VERSION ""

NS_ :

BS_:

BU_:

VAL_TABLE_ pin_diagnostics_state 1 "pdsNOK" 0 "pdsOK" ;

BO_ 2180423678 REAR_IO_1_ECU_CAN1_1: 8 Vector__XXX

 SG_ rllrShttrLckActtRq : 0|2@1+ (1,0) [0|3] "" Vector__XXX

BO_ 2381750526 CABIN_IO_1_ECU_CAN1_1: 8 Vector__XXX

 SG_ hzrdSwtchStt : 0|2@1+ (1,0) [0|3] "" Vector__XXX

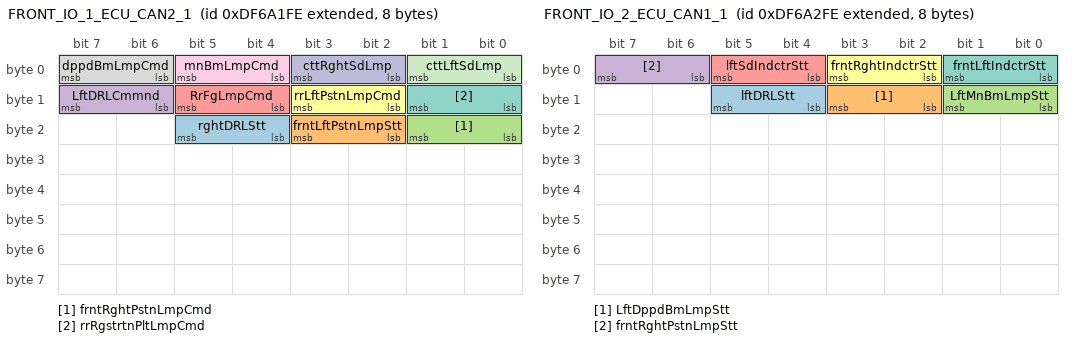
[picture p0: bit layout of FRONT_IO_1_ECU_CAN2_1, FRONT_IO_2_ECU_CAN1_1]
BO_ 2381750782 FRONT_IO_1_ECU_CAN2_1: 8 Vector__XXX

 SG_ rghtDRLStt : 20|2@1+ (1,0) [0|3] "" Vector__XXX

 SG_ frntLftPstnLmpStt : 18|2@1+ (1,0) [0|3] "" Vector__XXX

 SG_ frntRghtPstnLmpCmd : 16|2@1+ (1,0) [0|3] "" Vector__XXX

 SG_ LftDRLCmmnd : 14|2@1+ (1,0) [0|3] "" Vector__XXX

 SG_ RrFgLmpCmd : 12|2@1+ (1,0) [0|3] "" Vector__XXX

 SG_ rrLftPstnLmpCmd : 10|2@1+ (1,0) [0|3] "" Vector__XXX

 SG_ rrRgstrtnPltLmpCmd : 8|2@1+ (1,0) [0|3] "" Vector__XXX

 SG_ dppdBmLmpCmd : 6|2@1+ (1,0) [0|3] "" Vector__XXX

 SG_ mnBmLmpCmd : 4|2@1+ (1,0) [0|3] "" Vector__XXX

 SG_ cttRghtSdLmp : 2|2@1+ (1,0) [0|3] "" Vector__XXX

 SG_ cttLftSdLmp : 0|2@1+ (1,0) [0|3] "" Vector__XXX

BO_ 2381751038 FRONT_IO_2_ECU_CAN1_1: 8 Vector__XXX

 SG_ lftDRLStt : 12|2@1+ (1,0) [0|3] "" Vector__XXX

 SG_ LftDppdBmLmpStt : 10|2@1+ (1,0) [0|3] "" Vector__XXX

 SG_ LftMnBmLmpStt : 8|2@1+ (1,0) [0|3] "" Vector__XXX

 SG_ frntRghtPstnLmpStt : 6|2@1+ (1,0) [0|3] "" Vector__XXX

 SG_ lftSdIndctrStt : 4|2@1+ (1,0) [0|3] "" Vector__XXX

 SG_ frntRghtIndctrStt : 2|2@1+ (1,0) [0|3] "" Vector__XXX

 SG_ frntLftIndctrStt : 0|2@1+ (1,0) [0|3] "" Vector__XXX

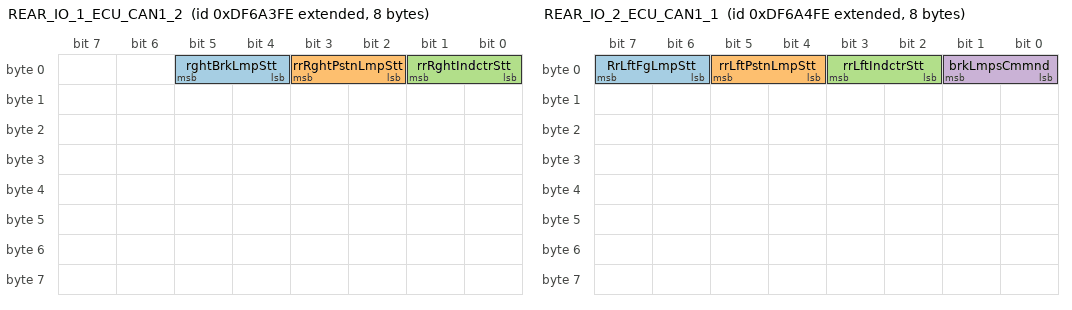
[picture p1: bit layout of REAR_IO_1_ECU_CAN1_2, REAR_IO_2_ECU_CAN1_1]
BO_ 2381751294 REAR_IO_1_ECU_CAN1_2: 8 Vector__XXX

 SG_ rghtBrkLmpStt : 4|2@1+ (1,0) [0|3] "" Vector__XXX

 SG_ rrRghtPstnLmpStt : 2|2@1+ (1,0) [0|3] "" Vector__XXX

 SG_ rrRghtIndctrStt : 0|2@1+ (1,0) [0|3] "" Vector__XXX

BO_ 2381751550 REAR_IO_2_ECU_CAN1_1: 8 Vector__XXX

 SG_ RrLftFgLmpStt : 6|2@1+ (1,0) [0|3] "" Vector__XXX

 SG_ rrLftPstnLmpStt : 4|2@1+ (1,0) [0|3] "" Vector__XXX

 SG_ rrLftIndctrStt : 2|2@1+ (1,0) [0|3] "" Vector__XXX

 SG_ brkLmpsCmmnd : 0|2@1+ (1,0) [0|3] "" Vector__XXX

BO_ 2583078398 CABIN_IO_1_ECU_CAN1_2: 8 Vector__XXX

 SG_ blkhdDrLtchStt : 0|2@1+ (1,0) [0|3] "-" Vector__XXX

BO_ 2583078654 CABIN_IO_2_ECU_CAN2_1: 8 Vector__XXX

 SG_ blkhdDrLtchRq : 4|2@1+ (1,0) [0|3] "-" Vector__XXX

 SG_ pssDrLtchRq : 2|2@1+ (1,0) [0|3] "-" Vector__XXX

 SG_ drvrDrLtchRq : 0|2@1+ (1,0) [0|3] "-" Vector__XXX

BO_ 2583078910 CABIN_IO_3_ECU_CAN1_1: 8 Vector__XXX

 SG_ pssPwrSldngDrSttDspl : 2|3@1+ (1,0) [0|0] "" Vector__XXX

 SG_ pssDrLtchStt : 0|2@1+ (1,0) [0|3] "-" Vector__XXX

BO_ 2583079166 FRONT_IO_1_ECU_CAN2_2: 8 Vector__XXX

 SG_ snsdSrvcHtchStt : 0|2@1+ (1,0) [0|0] "" Vector__XXX

BO_ 2583210494 FRONT_IO_2_ECU_CAN1_2: 8 Vector__XXX

 SG_ WshrCmmnd : 0|1@1+ (1,0) [0|1] "" Vector__XXX

BO_ 2583210750 FRONT_IO_1_ECU_CAN2_3: 8 Vector__XXX

 SG_ Glss2HtrStt : 0|2@1+ (1,0) [0|3] "" Vector__XXX

BO_ 2583211006 FRONT_IO_2_ECU_CAN1_3: 8 Vector__XXX

 SG_ Glss3HtrStt : 0|2@1+ (1,0) [0|3] "" Vector__XXX

BO_ 2365443838 ELREQ_DCU_Stalks: 8 Vector__XXX

 SG_ MainBeamStalksReq : 6|2@1+ (1,0) [0|3] "" Vector__XXX

 SG_ TurnIndReq : 2|4@1+ (1,0) [0|3] "" Vector__XXX

 SG_ SwitchReq : 0|2@1+ (1,0) [0|3] "" Vector__XXX

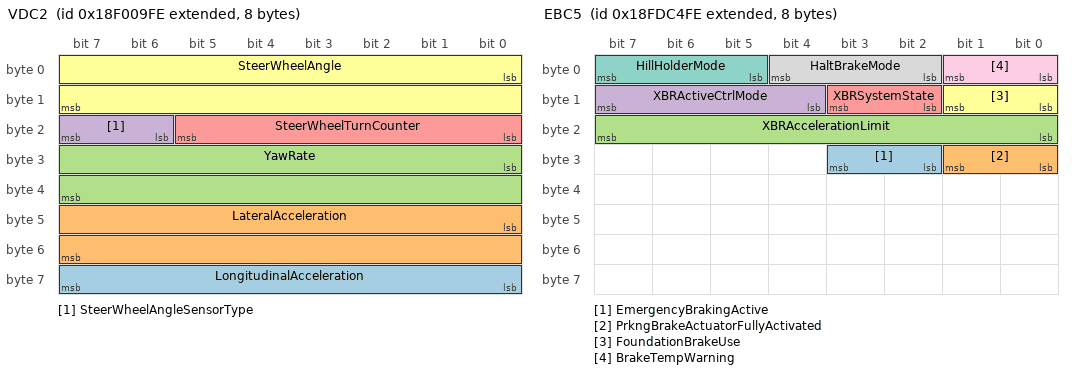
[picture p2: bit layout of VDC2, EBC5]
BO_ 2565868030 VDC2: 8 Vector__XXX

 SG_ LongitudinalAcceleration : 56|8@1+ (0.1,-12.5) [-12.5|12.5] "m/s" Vector__XXX

 SG_ LateralAcceleration : 40|16@1+ (0.00048828125,-15.687) [-15.687|15.687] "m/s" Vector__XXX

 SG_ YawRate : 24|16@1+ (0.0001220703125,-3.92) [-3.92|3.92] "rad/s" Vector__XXX

 SG_ SteerWheelAngleSensorType : 22|2@1+ (1,0) [0|3] "" Vector__XXX

 SG_ SteerWheelTurnCounter : 16|6@1+ (1,-32) [-10|10] "turns" Vector__XXX

 SG_ SteerWheelAngle : 0|16@1+ (0.0009765625,-31.374) [-31.374|31.374] "rad" Vector__XXX

BO_ 2566767870 EBC5: 8 Vector__XXX

 SG_ EmergencyBrakingActive : 26|2@1+ (1,0) [0|3] "" Vector__XXX

 SG_ PrkngBrakeActuatorFullyActivated : 24|2@1+ (1,0) [0|3] "" Vector__XXX

 SG_ XBRAccelerationLimit : 16|8@1+ (0.1,-12.5) [-10|10] "m/s" Vector__XXX

 SG_ XBRActiveCtrlMode : 12|4@1+ (1,0) [0|15] "" Vector__XXX

 SG_ XBRSystemState : 10|2@1+ (1,0) [0|3] "" Vector__XXX

 SG_ FoundationBrakeUse : 8|2@1+ (1,0) [0|3] "" Vector__XXX

 SG_ HillHolderMode : 5|3@1+ (1,0) [0|7] "" Vector__XXX

 SG_ HaltBrakeMode : 2|3@1+ (1,0) [0|7] "" Vector__XXX

 SG_ BrakeTempWarning : 0|2@1+ (1,0) [0|3] "" Vector__XXX

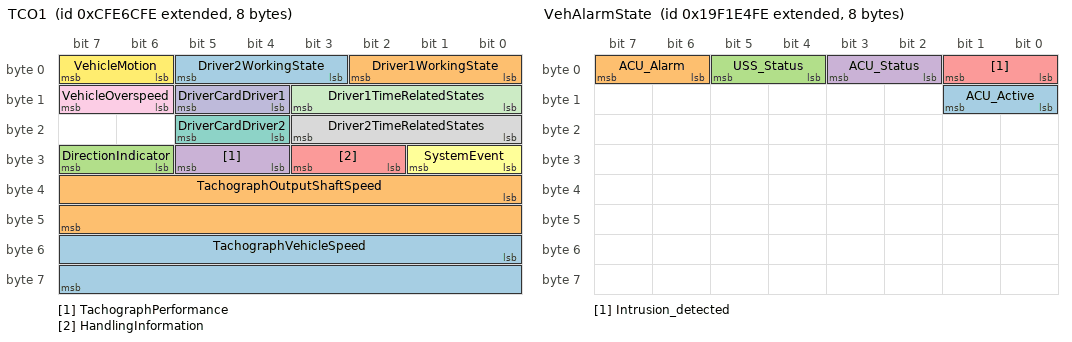
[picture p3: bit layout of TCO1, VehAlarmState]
BO_ 2365484286 TCO1: 8 Vector__XXX

 SG_ TachographVehicleSpeed : 48|16@1+ (0.00390625,0) [0|250.996] "km/h" Vector__XXX

 SG_ TachographOutputShaftSpeed : 32|16@1+ (0.125,0) [0|8031.875] "rpm" Vector__XXX

 SG_ DirectionIndicator : 30|2@1+ (1,0) [0|3] "" Vector__XXX

 SG_ TachographPerformance : 28|2@1+ (1,0) [0|3] "" Vector__XXX

 SG_ HandlingInformation : 26|2@1+ (1,0) [0|3] "" Vector__XXX

 SG_ SystemEvent : 24|2@1+ (1,0) [0|3] "" Vector__XXX

 SG_ DriverCardDriver2 : 20|2@1+ (1,0) [0|3] "" Vector__XXX

 SG_ Driver2TimeRelatedStates : 16|4@1+ (1,0) [0|15] "" Vector__XXX

 SG_ VehicleOverspeed : 14|2@1+ (1,0) [0|3] "" Vector__XXX

 SG_ DriverCardDriver1 : 12|2@1+ (1,0) [0|3] "" Vector__XXX

 SG_ Driver1TimeRelatedStates : 8|4@1+ (1,0) [0|15] "" Vector__XXX

 SG_ VehicleMotion : 6|2@1+ (1,0) [0|3] "" Vector__XXX

 SG_ Driver2WorkingState : 3|3@1+ (1,0) [0|7] "" Vector__XXX

 SG_ Driver1WorkingState : 0|3@1+ (1,0) [0|7] "" Vector__XXX

BO_ 2582766846 VehAlarmState: 8 Vector__XXX

 SG_ ACU_Active : 8|2@1+ (1,0) [0|3] "" Vector__XXX

 SG_ ACU_Alarm : 6|2@1+ (1,0) [0|3] "" Vector__XXX

 SG_ USS_Status : 4|2@1+ (1,0) [0|3] "" Vector__XXX

 SG_ ACU_Status : 2|2@1+ (1,0) [0|3] "" Vector__XXX

 SG_ Intrusion_detected : 0|2@1+ (1,0) [0|3] "-" Vector__XXX

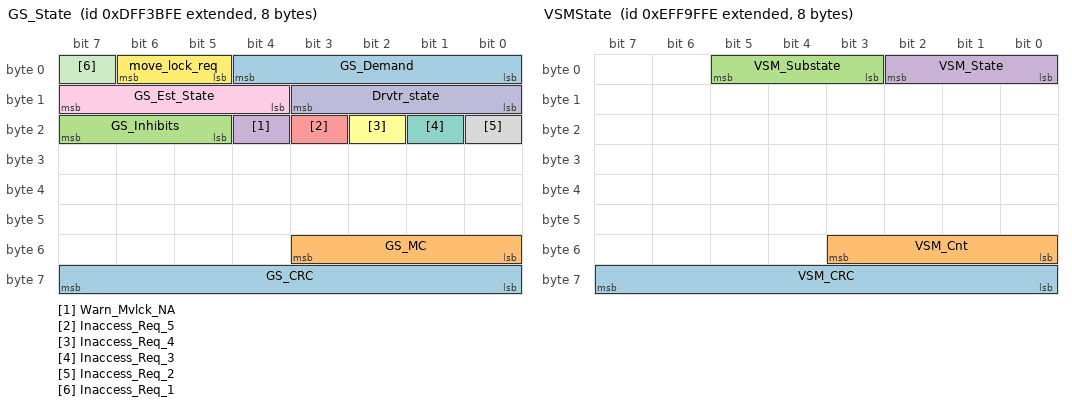
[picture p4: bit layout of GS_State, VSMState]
BO_ 2382314494 GS_State: 8 Vector__XXX

 SG_ GS_CRC : 56|8@1+ (1,0) [0|255] "" Vector__XXX

 SG_ GS_MC : 48|4@1+ (1,0) [0|15] "" Vector__XXX

 SG_ GS_Inhibits : 21|3@1+ (1,0) [0|7] "" Vector__XXX

 SG_ Warn_Mvlck_NA : 20|1@1+ (1,0) [0|1] "" Vector__XXX

 SG_ Inaccess_Req_5 : 19|1@1+ (1,0) [0|1] "" Vector__XXX

 SG_ Inaccess_Req_4 : 18|1@1+ (1,0) [0|1] "" Vector__XXX

 SG_ Inaccess_Req_3 : 17|1@1+ (1,0) [0|1] "" Vector__XXX

 SG_ Inaccess_Req_2 : 16|1@1+ (1,0) [0|1] "" Vector__XXX

 SG_ GS_Est_State : 12|4@1+ (1,0) [0|15] "" Vector__XXX

 SG_ Drvtr_state : 8|4@1+ (1,0) [0|15] "" Vector__XXX

 SG_ Inaccess_Req_1 : 7|1@1+ (1,0) [0|1] "" Vector__XXX

 SG_ move_lock_req : 5|2@1+ (1,0) [0|3] "" Vector__XXX

 SG_ GS_Demand : 0|5@1+ (1,0) [0|31] "" Vector__XXX

BO_ 2365473278 LCMD: 8 Vector__XXX

 SG_ ImplementRearWorkLightCmd : 62|2@1+ (1,0) [0|3] "" Vector__XXX

 SG_ ImplLeftFacingWorkLightCmd : 60|2@1+ (1,0) [0|3] "" Vector__XXX

 SG_ ImplRightFwdWorkLightCmd : 58|2@1+ (1,0) [0|3] "" Vector__XXX

 SG_ LightingDataRqCmd : 56|2@1+ (1,0) [0|3] "" Vector__XXX

 SG_ ImplLeftForwardWorkLightCmd : 54|2@1+ (1,0) [0|3] "" Vector__XXX

 SG_ ImplRightFacingWorkLightCmd : 52|2@1+ (1,0) [0|3] "" Vector__XXX

 SG_ ImplOEMOption1LightCmd : 50|2@1+ (1,0) [0|3] "" Vector__XXX

 SG_ ImplOEMOption2LightCmd : 48|2@1+ (1,0) [0|3] "" Vector__XXX

 SG_ TrctrFrntHghMdWkLightsCmd : 46|2@1+ (1,0) [0|3] "" Vector__XXX

 SG_ TrctrFrntLowMdWkLightsCmd : 44|2@1+ (1,0) [0|3] "" Vector__XXX

 SG_ TrctrSdeHighMdWkLightsCmd : 42|2@1+ (1,0) [0|3] "" Vector__XXX

 SG_ TrctrSideLowMdWkLightsCmd : 40|2@1+ (1,0) [0|3] "" Vector__XXX

 SG_ TrctrRarHighMdWkLightsCmd : 38|2@1+ (1,0) [0|3] "" Vector__XXX

 SG_ TrctrRearLowMdWkLightsCmd : 36|2@1+ (1,0) [0|3] "" Vector__XXX

 SG_ TrctrUndrsdeMdWkLightsCmd : 34|2@1+ (1,0) [0|3] "" Vector__XXX

 SG_ RearFogLightsCmd : 32|2@1+ (1,0) [0|3] "" Vector__XXX

 SG_ TractorMarkerLightCmd : 30|2@1+ (1,0) [0|3] "" Vector__XXX

 SG_ ImplementMarkerLightCmd : 28|2@1+ (1,0) [0|3] "" Vector__XXX

 SG_ TractorClearanceLightCmd : 26|2@1+ (1,0) [0|3] "" Vector__XXX

 SG_ ImplementClearanceLightCmd : 24|2@1+ (1,0) [0|3] "" Vector__XXX

 SG_ LeftStopLightCmd : 22|2@1+ (1,0) [0|3] "" Vector__XXX

 SG_ RightStopLightCmd : 20|2@1+ (1,0) [0|3] "" Vector__XXX

 SG_ CenterStopLightCmd : 18|2@1+ (1,0) [0|3] "" Vector__XXX

 SG_ BackUpLightAndAlarmHornCmd : 16|2@1+ (1,0) [0|3] "" Vector__XXX

 SG_ LeftTurnSignalLightsCmd : 14|2@1+ (1,0) [0|3] "" Vector__XXX

 SG_ RightTurnSignalLightsCmd : 12|2@1+ (1,0) [0|3] "" Vector__XXX

 SG_ RotatingBeaconLightCmd : 10|2@1+ (1,0) [0|3] "" Vector__XXX

 SG_ TractorFrontFogLightsCmd : 8|2@1+ (1,0) [0|3] "" Vector__XXX

 SG_ HighBeamHeadLightCmd : 6|2@1+ (1,0) [0|3] "" Vector__XXX

 SG_ LowBeamHeadLightCmd : 4|2@1+ (1,0) [0|3] "" Vector__XXX

 SG_ AltBeamHeadLightCmd : 2|2@1+ (1,0) [0|3] "" Vector__XXX

 SG_ RunningLightCmd : 0|2@1+ (1,0) [0|3] "" Vector__XXX

BO_ 2399117310 VSMState: 8 Vector__XXX

 SG_ VSM_CRC : 56|8@1+ (1,0) [0|255] "" Vector__XXX

 SG_ VSM_Cnt : 48|4@1+ (1,0) [0|15] "" Vector__XXX

 SG_ VSM_Substate : 3|3@1+ (1,0) [0|7] "" Vector__XXX

 SG_ VSM_State : 0|3@1+ (1,0) [0|7] "" Vector__XXX

BO_ 2566799614 LD: 8 Vector__XXX

 SG_ ImplementRearWorkLight : 62|2@1+ (1,0) [0|3] "" Vector__XXX

 SG_ ImplLeftFacingWorkLight : 60|2@1+ (1,0) [0|3] "" Vector__XXX

 SG_ ImplRightForwardWorkLight : 58|2@1+ (1,0) [0|3] "" Vector__XXX

 SG_ ImplLeftForwardWorkLight : 54|2@1+ (1,0) [0|3] "" Vector__XXX

 SG_ ImplRightFacingWorkLight : 52|2@1+ (1,0) [0|3] "" Vector__XXX

 SG_ ImplementOEMOption1Light : 50|2@1+ (1,0) [0|3] "" Vector__XXX

 SG_ ImplementOEMOption2Light : 48|2@1+ (1,0) [0|3] "" Vector__XXX

 SG_ TrctorFrontHighMdWkLights : 46|2@1+ (1,0) [0|3] "" Vector__XXX

 SG_ TractorFrontLowMdWkLights : 44|2@1+ (1,0) [0|3] "" Vector__XXX

 SG_ TractorSideHighMdWkLights : 42|2@1+ (1,0) [0|3] "" Vector__XXX

 SG_ TractorSideLowMdWkLights : 40|2@1+ (1,0) [0|3] "" Vector__XXX

 SG_ TractorRearHighMdWkLights : 38|2@1+ (1,0) [0|3] "" Vector__XXX

 SG_ TractorRearLowMdWkLights : 36|2@1+ (1,0) [0|3] "" Vector__XXX

 SG_ TrctorUndersideMdWkLights : 34|2@1+ (1,0) [0|3] "" Vector__XXX

 SG_ RearFogLights : 32|2@1+ (1,0) [0|3] "" Vector__XXX

 SG_ TractorMarkerLight : 30|2@1+ (1,0) [0|3] "" Vector__XXX

 SG_ ImplementMarkerLight : 28|2@1+ (1,0) [0|3] "" Vector__XXX

 SG_ TractorClearanceLight : 26|2@1+ (1,0) [0|3] "" Vector__XXX

 SG_ ImplementClearanceLight : 24|2@1+ (1,0) [0|3] "" Vector__XXX

 SG_ LeftStopLight : 22|2@1+ (1,0) [0|3] "" Vector__XXX

 SG_ RightStopLight : 20|2@1+ (1,0) [0|3] "" Vector__XXX

 SG_ CenterStopLight : 18|2@1+ (1,0) [0|3] "" Vector__XXX

 SG_ BackUpLightAndAlarmHorn : 16|2@1+ (1,0) [0|3] "" Vector__XXX

 SG_ LeftTurnSignalLights : 14|2@1+ (1,0) [0|3] "" Vector__XXX

 SG_ RightTurnSignalLights : 12|2@1+ (1,0) [0|3] "" Vector__XXX

 SG_ RotatingBeaconLight : 10|2@1+ (1,0) [0|3] "" Vector__XXX

 SG_ TractorFrontFogLights : 8|2@1+ (1,0) [0|3] "" Vector__XXX

 SG_ HighBeamHeadLight : 6|2@1+ (1,0) [0|3] "" Vector__XXX

 SG_ LowBeamHeadLight : 4|2@1+ (1,0) [0|3] "" Vector__XXX

 SG_ AltBeamHeadLight : 2|2@1+ (1,0) [0|3] "" Vector__XXX

 SG_ RunningLight : 0|2@1+ (1,0) [0|3] "" Vector__XXX

BO_ 2381851134 HornSwitchState: 8 Vector__XXX

 SG_ HornSwitchReq : 0|2@1+ (1,0) [0|3] "" Vector__XXX

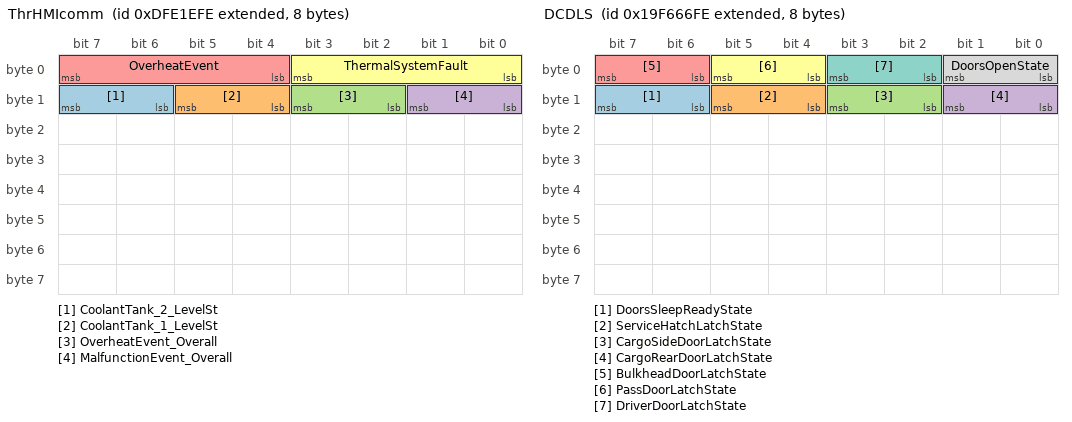
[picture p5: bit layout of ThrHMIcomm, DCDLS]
BO_ 2382241534 ThrHMIcomm: 8 Vector__XXX

 SG_ CoolantTank_2_LevelSt : 14|2@1+ (1,0) [0|0] "" Vector__XXX

 SG_ CoolantTank_1_LevelSt : 12|2@1+ (1,0) [0|0] "" Vector__XXX

 SG_ OverheatEvent_Overall : 10|2@1+ (1,0) [0|0] "" Vector__XXX

 SG_ MalfunctionEvent_Overall : 8|2@1+ (1,0) [0|0] "" Vector__XXX

 SG_ OverheatEvent : 4|4@1+ (1,0) [0|0] "" Vector__XXX

 SG_ ThermalSystemFault : 0|4@1+ (1,0) [0|0] "" Vector__XXX

BO_ 2314625790 RideHeightSensorRaw: 8 Vector__XXX

 SG_ HeightMeasured : 8|8@1+ (1,0) [0|255] "mm" Vector__XXX

 SG_ RotationAngle : 0|8@1+ (1,90) [90|270] "deg" Vector__XXX

BO_ 2583062270 DCDLS: 8 Vector__XXX

 SG_ DoorsSleepReadyState : 14|2@1+ (1,0) [0|3] "-" Vector__XXX

 SG_ ServiceHatchLatchState : 12|2@1+ (1,0) [0|0] "" Vector__XXX

 SG_ CargoSideDoorLatchState : 10|2@1+ (1,0) [0|3] "-" Vector__XXX

 SG_ CargoRearDoorLatchState : 8|2@1+ (1,0) [0|3] "-" Vector__XXX

 SG_ BulkheadDoorLatchState : 6|2@1+ (1,0) [0|3] "-" Vector__XXX

 SG_ PassDoorLatchState : 4|2@1+ (1,0) [0|3] "-" Vector__XXX

 SG_ DriverDoorLatchState : 2|2@1+ (1,0) [0|3] "-" Vector__XXX

 SG_ DoorsOpenState : 0|2@1+ (1,0) [0|3] "-" Vector__XXX

BO_ 2566882814 VehicleKeyState: 8 Vector__XXX

 SG_ KeyRange : 3|3@1+ (1,0) [0|7] "-" Vector__XXX

 SG_ KeyCommand : 0|3@1+ (1,0) [0|7] "-" Vector__XXX

BO_ 2583062526 CENTLOCKIN_HMI: 8 Vector__XXX

 SG_ CentralLockRequest : 0|3@1+ (1,0) [0|7] "-" Vector__XXX

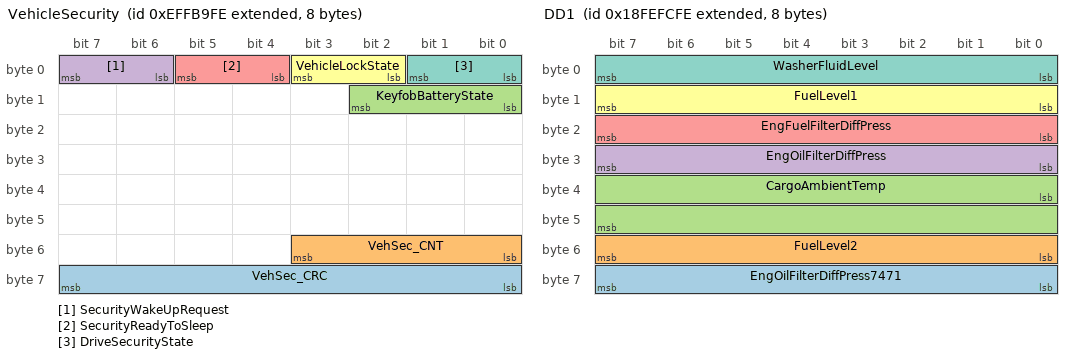
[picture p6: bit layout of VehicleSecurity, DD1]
BO_ 2399123966 VehicleSecurity: 8 Vector__XXX

 SG_ VehSec_CRC : 56|8@1+ (1,0) [0|255] "" Vector__XXX

 SG_ VehSec_CNT : 48|4@1+ (1,0) [0|15] "" Vector__XXX

 SG_ KeyfobBatteryState : 8|3@1+ (1,0) [0|7] "" Vector__XXX

 SG_ SecurityWakeUpRequest : 6|2@1+ (1,0) [0|3] "" Vector__XXX

 SG_ SecurityReadyToSleep : 4|2@1+ (1,0) [0|3] "" Vector__XXX

 SG_ VehicleLockState : 2|2@1+ (1,0) [0|3] "" Vector__XXX

 SG_ DriveSecurityState : 0|2@1+ (1,0) [0|3] "" Vector__XXX

BO_ 2583065854 CENTLOCKIN_KeyFob: 8 Vector__XXX

 SG_ CentralLockRequest : 0|3@1+ (1,0) [0|7] "-" Vector__XXX

BO_ 2163223550 CN: 8 Vector__XXX

 SG_ CrashChecksum : 60|4@1+ (1,0) [0|15] "" Vector__XXX

 SG_ CrashCounter : 56|4@1+ (1,0) [0|15] "" Vector__XXX

 SG_ CrashType : 0|5@1+ (1,0) [0|31] "" Vector__XXX

BO_ 2566847742 DD1: 8 Vector__XXX

 SG_ EngOilFilterDiffPress7471 : 56|8@1+ (5,0) [0|1250] "kPa" Vector__XXX

 SG_ FuelLevel2 : 48|8@1+ (0.4,0) [0|100] "%" Vector__XXX

 SG_ CargoAmbientTemp : 32|16@1+ (0.03125,-273) [-273|1734.96875] "C" Vector__XXX

 SG_ EngOilFilterDiffPress : 24|8@1+ (0.5,0) [0|125] "kPa" Vector__XXX

 SG_ EngFuelFilterDiffPress : 16|8@1+ (2,0) [0|500] "kPa" Vector__XXX

 SG_ FuelLevel1 : 8|8@1+ (0.4,0) [0|100] "%" Vector__XXX

 SG_ WasherFluidLevel : 0|8@1+ (0.4,0) [0|100] "%" Vector__XXX

BO_ 2583173886 WPRWSH_UserRequest: 8 Vector__XXX

 SG_ WipeRequest : 2|3@1+ (1,0) [0|7] "" Vector__XXX

 SG_ WashRequest : 0|2@1+ (1,0) [0|3] "" Vector__XXX

BO_ 2516075518 RideHeight_Info: 8 Vector__XXX

 SG_ RideHeight_Value : 0|3@1+ (1,0) [0|0] "" Vector__XXX

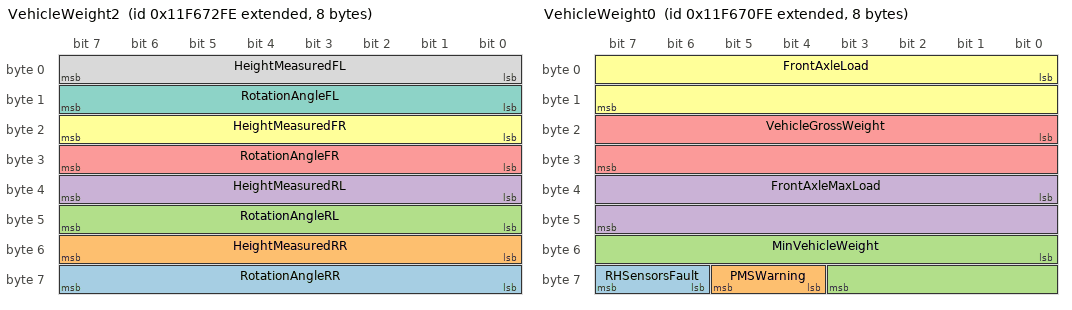
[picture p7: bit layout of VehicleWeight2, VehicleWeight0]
BO_ 2448847614 VehicleWeight2: 8 Vector__XXX

 SG_ RotationAngleRR : 56|8@1+ (1,90) [90|270] "deg" Vector__XXX

 SG_ HeightMeasuredRR : 48|8@1+ (1,0) [0|255] "mm" Vector__XXX

 SG_ RotationAngleRL : 40|8@1+ (1,90) [90|270] "deg" Vector__XXX

 SG_ HeightMeasuredRL : 32|8@1+ (1,0) [0|255] "mm" Vector__XXX

 SG_ RotationAngleFR : 24|8@1+ (1,90) [90|270] "deg" Vector__XXX

 SG_ HeightMeasuredFR : 16|8@1+ (1,0) [0|255] "mm" Vector__XXX

 SG_ RotationAngleFL : 8|8@1+ (1,90) [90|270] "deg" Vector__XXX

 SG_ HeightMeasuredFL : 0|8@1+ (1,0) [0|255] "mm" Vector__XXX

BO_ 2448847102 VehicleWeight0: 8 Vector__XXX

 SG_ RHSensorsFault : 62|2@1+ (1,0) [0|3] "" Vector__XXX

 SG_ PMSWarning : 60|2@1+ (1,0) [0|3] "" Vector__XXX

 SG_ MinVehicleWeight : 48|12@1+ (10,0) [0|40000] "kg" Vector__XXX

 SG_ FrontAxleMaxLoad : 32|16@1+ (1,0) [0|65535] "kg" Vector__XXX

 SG_ VehicleGrossWeight : 16|16@1+ (1,0) [0|65535] "kg" Vector__XXX

 SG_ FrontAxleLoad : 0|16@1+ (1,0) [0|65535] "kg" Vector__XXX

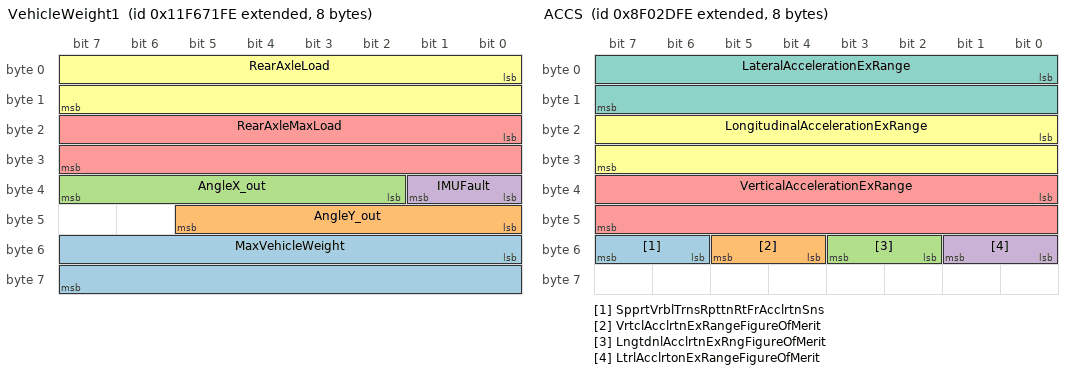
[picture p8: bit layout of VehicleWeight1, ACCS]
BO_ 2448847358 VehicleWeight1: 8 Vector__XXX

 SG_ MaxVehicleWeight : 48|16@1+ (1,0) [0|65535] "kg" Vector__XXX

 SG_ AngleY_out : 40|6@1+ (1.5,-45) [-45|45] "deg" Vector__XXX

 SG_ AngleX_out : 34|6@1+ (1.5,-45) [-45|45] "deg" Vector__XXX

 SG_ IMUFault : 32|2@1+ (1,0) [0|3] "" Vector__XXX

 SG_ RearAxleMaxLoad : 16|16@1+ (1,0) [0|65535] "kg" Vector__XXX

 SG_ RearAxleLoad : 0|16@1+ (1,0) [0|65535] "kg" Vector__XXX

BO_ 2297441790 ACCS: 8 Vector__XXX

 SG_ SpprtVrblTrnsRpttnRtFrAcclrtnSns : 54|2@1+ (1,0) [0|3] "" Vector__XXX

 SG_ VrtclAcclrtnExRangeFigureOfMerit : 52|2@1+ (1,0) [0|3] "" Vector__XXX

 SG_ LngtdnlAcclrtnExRngFigureOfMerit : 50|2@1+ (1,0) [0|3] "" Vector__XXX

 SG_ LtrlAcclrtonExRangeFigureOfMerit : 48|2@1+ (1,0) [0|3] "" Vector__XXX

 SG_ VerticalAccelerationExRange : 32|16@1+ (0.01,-320) [-320|322.55] "m/s" Vector__XXX

 SG_ LongitudinalAccelerationExRange : 16|16@1+ (0.01,-320) [-320|322.55] "m/s" Vector__XXX

 SG_ LateralAccelerationExRange : 0|16@1+ (0.01,-320) [-320|322.55] "m/s" Vector__XXX

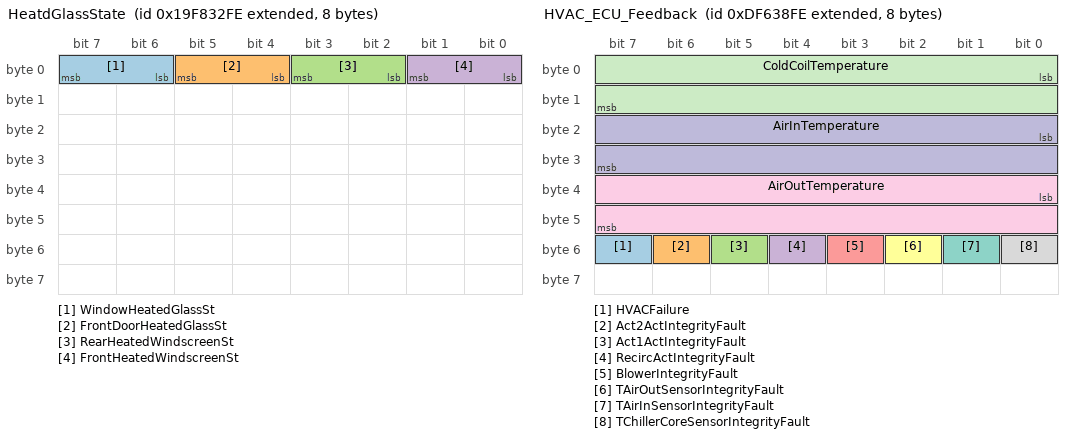
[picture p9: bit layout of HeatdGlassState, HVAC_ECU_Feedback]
BO_ 2583180030 HeatdGlassState: 8 Vector__XXX

 SG_ WindowHeatedGlassSt : 6|2@1+ (1,0) [0|3] "" Vector__XXX

 SG_ FrontDoorHeatedGlassSt : 4|2@1+ (1,0) [0|3] "" Vector__XXX

 SG_ RearHeatedWindscreenSt : 2|2@1+ (1,0) [0|3] "" Vector__XXX

 SG_ FrontHeatedWindscreenSt : 0|2@1+ (1,0) [0|3] "" Vector__XXX

BO_ 2499547902 CDC: 8 Vector__XXX

 SG_ MirrorRight2HeatCmd : 54|2@1+ (1,0) [0|3] "" Vector__XXX

 SG_ MirrorLeft2HeatCmd : 52|2@1+ (1,0) [0|3] "" Vector__XXX

 SG_ MirrorRight1HeatCmd : 50|2@1+ (1,0) [0|3] "" Vector__XXX

 SG_ MirrorLeft1HeatCmd : 48|2@1+ (1,0) [0|3] "" Vector__XXX

 SG_ MirrorRight2VerticalCmd : 46|2@1+ (1,0) [0|3] "" Vector__XXX

 SG_ MirrorRight2HorizontalCmd : 44|2@1+ (1,0) [0|3] "" Vector__XXX

 SG_ MirrorLeft2VerticalCmd : 42|2@1+ (1,0) [0|3] "" Vector__XXX

 SG_ MirrorLeft2HorizontalCmd : 40|2@1+ (1,0) [0|3] "" Vector__XXX

 SG_ MirrorRight1VerticalCmd : 38|2@1+ (1,0) [0|3] "" Vector__XXX

 SG_ MirrorRight1HorizontalCmd : 36|2@1+ (1,0) [0|3] "" Vector__XXX

 SG_ MirrorLeft1VerticalCmd : 34|2@1+ (1,0) [0|3] "" Vector__XXX

 SG_ MirrorLeft1HorizontalCmd : 32|2@1+ (1,0) [0|3] "" Vector__XXX

 SG_ RightRearWindowPosCmd : 27|3@1+ (1,0) [0|7] "" Vector__XXX

 SG_ LeftRearWindowPosCmd : 24|3@1+ (1,0) [0|7] "" Vector__XXX

 SG_ RightFrontWindowPosCmd : 19|3@1+ (1,0) [0|7] "" Vector__XXX

 SG_ LeftFrontWindowPosCmd : 16|3@1+ (1,0) [0|7] "" Vector__XXX

 SG_ RemoteCabDoorLockReq : 8|3@1+ (1,0) [0|7] "" Vector__XXX

 SG_ DoorsLockActCmd : 0|3@1+ (1,0) [0|7] "" Vector__XXX

BO_ 2583173374 WPRWSH_WiperFaults: 8 Vector__XXX

 SG_ WiperSilenceFault : 2|1@1+ (1,0) [0|1] "" Vector__XXX

 SG_ WiperHomePosFault : 1|1@1+ (1,0) [0|1] "" Vector__XXX

 SG_ WiperControlFault : 0|1@1+ (1,0) [0|1] "" Vector__XXX

BO_ 2583177470 WPRWSH_RainData: 8 Vector__XXX

 SG_ RainIntensity : 0|3@1+ (1,0) [0|7] "" Vector__XXX

BO_ 2583175166 WPRWSH_WiperArbReq: 8 Vector__XXX

 SG_ WipeArbRequest : 0|3@1+ (1,0) [0|5] "" Vector__XXX

BO_ 2364552702 ImmoState: 8 Vector__XXX

 SG_ ImmoState : 0|2@1+ (1,0) [0|3] "" Vector__XXX

BO_ 2565865982 EBC1: 8 Vector__XXX

 SG_ TrctrMntdTrailerABSWarningSignal : 62|2@1+ (1,0) [0|3] "" Vector__XXX

 SG_ TrailerABSStatus : 60|2@1+ (1,0) [0|3] "" Vector__XXX

 SG_ HaltBrakeSwitch : 58|2@1+ (1,0) [0|3] "" Vector__XXX

 SG_ SrcAddrssOfCntrllngDvcFrBrkeCtrl : 48|8@1+ (1,0) [0|253] "" Vector__XXX

 SG_ ATC_ASRInformationSignal : 46|2@1+ (1,0) [0|3] "" Vector__XXX

 SG_ ABS_EBSAmberWarningSignal : 44|2@1+ (1,0) [0|3] "" Vector__XXX

 SG_ EBSRedWarningSignal : 42|2@1+ (1,0) [0|3] "" Vector__XXX

 SG_ ABSFullyOperational : 40|2@1+ (1,0) [0|3] "" Vector__XXX

 SG_ EngRetarderSelection : 32|8@1+ (0.4,0) [0|100] "%" Vector__XXX

 SG_ RemoteAccelEnableSwitch : 30|2@1+ (1,0) [0|3] "" Vector__XXX

 SG_ EngAuxShutdownSwitch : 28|2@1+ (1,0) [0|3] "" Vector__XXX

 SG_ EngDerateSwitch : 26|2@1+ (1,0) [0|3] "" Vector__XXX

 SG_ AccelInterlockSwitch : 24|2@1+ (1,0) [0|3] "" Vector__XXX

 SG_ TractionCtrlOverrideSwitch : 22|2@1+ (1,0) [0|3] "" Vector__XXX

 SG_ ASRHillHolderSwitch : 20|2@1+ (1,0) [0|3] "" Vector__XXX

 SG_ ASROffroadSwitch : 18|2@1+ (1,0) [0|3] "" Vector__XXX

 SG_ ABSOffroadSwitch : 16|2@1+ (1,0) [0|3] "" Vector__XXX

 SG_ BrakePedalPos : 8|8@1+ (0.4,0) [0|100] "%" Vector__XXX

 SG_ EBSBrakeSwitch : 6|2@1+ (1,0) [0|3] "" Vector__XXX

 SG_ AntiLockBrakingActive : 4|2@1+ (1,0) [0|3] "" Vector__XXX

 SG_ ASRBrakeCtrlActive : 2|2@1+ (1,0) [0|3] "" Vector__XXX

 SG_ ASREngCtrlActive : 0|2@1+ (1,0) [0|3] "" Vector__XXX

BO_ 2583176190 SeatSt: 8 Vector__XXX

 SG_ SigSeatSt : 6|2@1+ (1,0) [0|3] "" Vector__XXX

BO_ 2381731326 TP_TouchEvent: 8 Vector__XXX

 SG_ TouchFailState : 3|3@1+ (1,0) [0|7] "" Vector__XXX

 SG_ TouchEvent : 0|3@1+ (1,0) [0|7] "" Vector__XXX

BO_ 2381723902 HVAC_ECU_Feedback: 8 Vector__XXX

 SG_ HVACFailure : 55|1@1+ (1,0) [0|1] "" Vector__XXX

 SG_ Act2ActIntegrityFault : 54|1@1+ (1,0) [0|1] "" Vector__XXX

 SG_ Act1ActIntegrityFault : 53|1@1+ (1,0) [0|1] "" Vector__XXX

 SG_ RecircActIntegrityFault : 52|1@1+ (1,0) [0|1] "" Vector__XXX

 SG_ BlowerIntegrityFault : 51|1@1+ (1,0) [0|1] "" Vector__XXX

 SG_ TAirOutSensorIntegrityFault : 50|1@1+ (1,0) [0|1] "" Vector__XXX

 SG_ TAirInSensorIntegrityFault : 49|1@1+ (1,0) [0|1] "" Vector__XXX

 SG_ TChillerCoreSensorIntegrityFault : 48|1@1+ (1,0) [0|1] "" Vector__XXX

 SG_ AirOutTemperature : 32|16@1+ (0.03125,-273) [-273|1774.96875] "C" Vector__XXX

 SG_ AirInTemperature : 16|16@1+ (0.03125,-273) [-273|1774.96875] "C" Vector__XXX

 SG_ ColdCoilTemperature : 0|16@1+ (0.03125,-273) [-273|1774.96875] "C" Vector__XXX

BO_ 2566848570 AirHandler_Temperatures: 8 Device

 SG_ BlowerSpeed : 48|8@1+ (0.4,0) [0|102] "%"  Host

 SG_ AirOutTemperature : 32|16@1+ (0.03125,-273) [-273|1774.97] "C"  Host

 SG_ AirInTemperature : 16|16@1+ (0.03125,-273) [-273|1774.97] "C"  Host

 SG_ ColdCoilTemperature : 0|16@1+ (0.03125,-273) [-273|1774.97] "C"  Host

BO_ 2566848826 AirHandler_Status1: 8 Device

 SG_ Defrost_Act_Position : 56|8@1+ (10,0) [0|2550] "steps"  Host

 SG_ Defrost_Act_Stall : 55|1@1+ (1,0) [0|1] ""  Host

 SG_ Defrost_Act_Voltage : 53|2@1+ (1,0) [0|3] ""  Host

 SG_ Defrost_Act_Temp : 52|1@1+ (1,0) [0|1] ""  Host

 SG_ Defrost_Act_Response : 51|1@1+ (1,0) [0|1] ""  Host

 SG_ Addressing_Status : 48|3@1+ (1,0) [0|7] ""  Host

 SG_ Face_Act_Position : 40|8@1+ (10,0) [0|2550] "steps"  Host

 SG_ Face_Act_Stall : 39|1@1+ (1,0) [0|1] ""  Host

 SG_ Face_Act_Voltage : 37|2@1+ (1,0) [0|3] ""  Host

 SG_ Face_Act_Temp : 36|1@1+ (1,0) [0|1] ""  Host

 SG_ Face_Act_Response : 35|1@1+ (1,0) [0|1] ""  Host

 SG_ Calibration_Status : 32|3@1+ (1,0) [0|7] ""  Host

 SG_ Foot_Act_Position : 24|8@1+ (10,0) [0|2550] "steps"  Host

 SG_ Foot_Act_Stall : 23|1@1+ (1,0) [0|1] ""  Host

 SG_ Foot_Act_Voltage : 21|2@1+ (1,0) [0|3] ""  Host

 SG_ Foot_Act_Temp : 20|1@1+ (1,0) [0|1] ""  Host

 SG_ Foot_Act_Response : 19|1@1+ (1,0) [0|1] ""  Host

 SG_ AirDirectionMode : 16|3@1+ (1,0) [0|7] ""  Host

 SG_ RecircActPosition : 8|8@1+ (10,0) [0|2550] "steps"  Host

 SG_ RecircActStall : 7|1@1+ (1,0) [0|1] ""  Host

 SG_ RecircActVoltage : 5|2@1+ (1,0) [0|3] ""  Host

 SG_ RecircActTemp : 4|1@1+ (1,0) [0|1] ""  Host

 SG_ RecircActResponse : 3|1@1+ (1,0) [0|1] ""  Host

 SG_ RecircMode : 0|3@1+ (1,0) [0|7] ""  Host

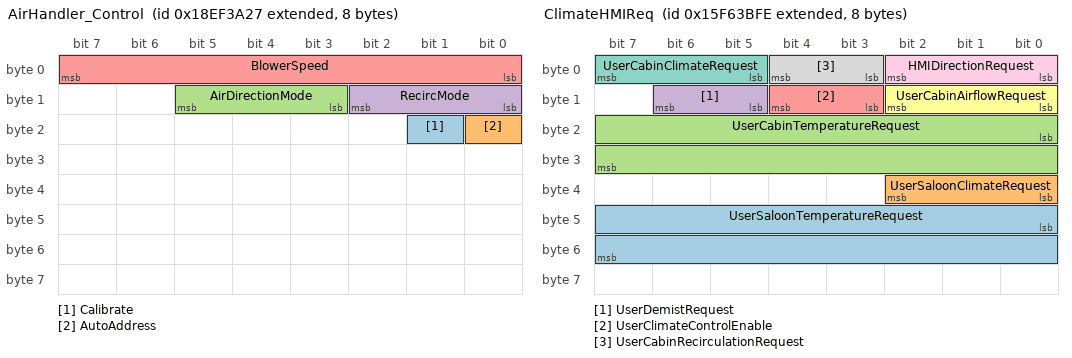
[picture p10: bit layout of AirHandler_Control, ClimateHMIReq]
BO_ 2565814823 AirHandler_Control: 8 Host

 SG_ Calibrate : 17|1@1+ (1,0) [0|1] ""  Device

 SG_ AutoAddress : 16|1@1+ (1,0) [0|1] ""  Device

 SG_ AirDirectionMode : 11|3@1+ (1,0) [0|7] ""  Device

 SG_ RecircMode : 8|3@1+ (1,0) [0|7] ""  Device

 SG_ BlowerSpeed : 0|8@1+ (0.4,0) [0|102] "%"  Device

BO_ 2515942398 ClimateHMIReq: 8 Vector__XXX

 SG_ UserSaloonTemperatureRequest : 40|16@1+ (0.03125,-273) [-273|1774.96875] "C" Vector__XXX

 SG_ UserSaloonClimateRequest : 32|3@1+ (1,0) [0|7] "" Vector__XXX

 SG_ UserCabinTemperatureRequest : 16|16@1+ (0.03125,-273) [-273|1774.96875] "C" Vector__XXX

 SG_ UserDemistRequest : 13|2@1+ (1,0) [0|3] "" Vector__XXX

 SG_ UserClimateControlEnable : 11|2@1+ (1,0) [0|3] "" Vector__XXX

 SG_ UserCabinAirflowRequest : 8|3@1+ (1,0) [0|7] "" Vector__XXX

 SG_ UserCabinClimateRequest : 5|3@1+ (1,0) [0|7] "" Vector__XXX

 SG_ UserCabinRecirculationRequest : 3|2@1+ (1,0) [0|3] "" Vector__XXX

 SG_ HMIDirectionRequest : 0|3@1+ (1,0) [0|0] "" Vector__XXX

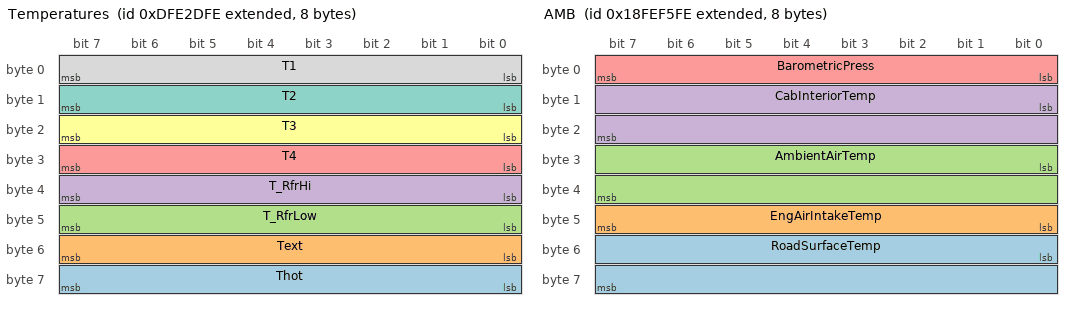
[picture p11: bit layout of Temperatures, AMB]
BO_ 2382245374 Temperatures: 8 Vector__XXX

 SG_ Thot : 56|8@1+ (1,-40) [-40|200] "" Vector__XXX

 SG_ Text : 48|8@1+ (1,-40) [-40|200] "" Vector__XXX

 SG_ T_RfrLow : 40|8@1+ (1,-40) [-40|200] "" Vector__XXX

 SG_ T_RfrHi : 32|8@1+ (1,-40) [-40|200] "" Vector__XXX

 SG_ T4 : 24|8@1+ (1,-40) [-40|200] "" Vector__XXX

 SG_ T3 : 16|8@1+ (1,-40) [-40|200] "" Vector__XXX

 SG_ T2 : 8|8@1+ (1,-40) [-40|200] "" Vector__XXX

 SG_ T1 : 0|8@1+ (1,-40) [-40|200] "" Vector__XXX

BO_ 2515942654 ClimateTempData: 8 Vector__XXX

 SG_ ActualSaloonTemperature : 32|16@1+ (0.03125,-273) [-273|1774.96875] "C" Vector__XXX

 SG_ ActualCabinTemperature : 16|16@1+ (0.03125,-273) [-273|1774.96875] "C" Vector__XXX

 SG_ TargetCabinTemperature : 0|16@1+ (0.03125,-273) [-273|1774.96875] "C" Vector__XXX

BO_ 2566845950 AMB: 8 Vector__XXX

 SG_ RoadSurfaceTemp : 48|16@1+ (0.03125,-273) [-273|1734.96875] "C" Vector__XXX

 SG_ EngAirIntakeTemp : 40|8@1+ (1,-40) [-40|210] "C" Vector__XXX

 SG_ AmbientAirTemp : 24|16@1+ (0.03125,-273) [-273|1734.96875] "C" Vector__XXX

 SG_ CabInteriorTemp : 8|16@1+ (0.03125,-273) [-273|1734.96875] "C" Vector__XXX

 SG_ BarometricPress : 0|8@1+ (0.5,0) [0|125] "kPa" Vector__XXX

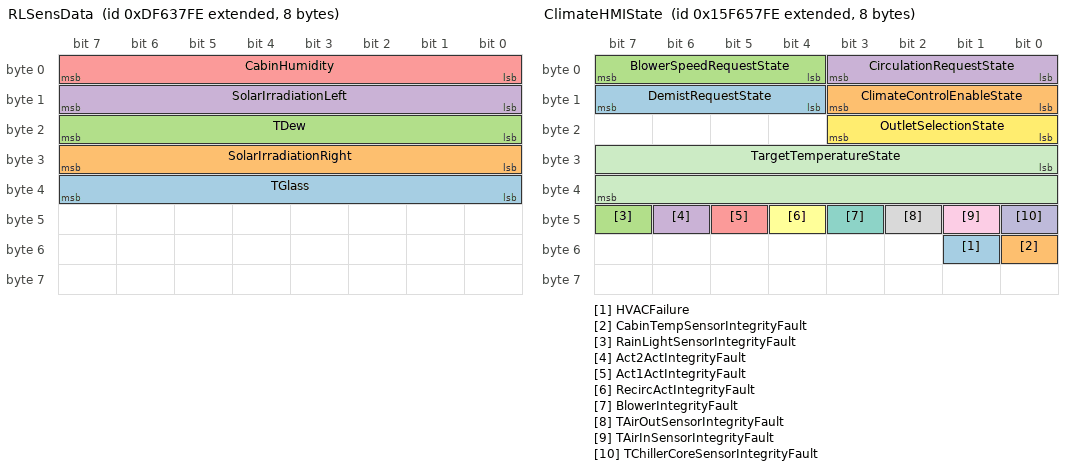
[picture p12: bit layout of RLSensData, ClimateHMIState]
BO_ 2381723646 RLSensData: 8 Vector__XXX

 SG_ TGlass : 32|8@1+ (0.5,0) [0|127.5] "C" Vector__XXX

 SG_ SolarIrradiationRight : 24|8@1+ (5,0) [0|1275] "W/m2" Vector__XXX

 SG_ TDew : 16|8@1+ (0.5,0) [0|127.5] "C" Vector__XXX

 SG_ SolarIrradiationLeft : 8|8@1+ (5,0) [0|1275] "W/m2" Vector__XXX

 SG_ CabinHumidity : 0|8@1+ (0.5,0) [0|127.5] "%" Vector__XXX

BO_ 2382239742 CabineDemand: 8 Vector__XXX

 SG_ CabineHeatingDemand : 8|8@1+ (1,-100) [-100|100] "" Vector__XXX

 SG_ CabineCoolingDemand : 0|8@1+ (1,-100) [-100|100] "" Vector__XXX

BO_ 2515949566 ClimateHMIState: 8 Vector__XXX

 SG_ HVACFailure : 49|1@1+ (1,0) [0|1] "" Vector__XXX

 SG_ CabinTempSensorIntegrityFault : 48|1@1+ (1,0) [0|1] "" Vector__XXX

 SG_ RainLightSensorIntegrityFault : 47|1@1+ (1,0) [0|1] "" Vector__XXX

 SG_ Act2ActIntegrityFault : 46|1@1+ (1,0) [0|1] "" Vector__XXX

 SG_ Act1ActIntegrityFault : 45|1@1+ (1,0) [0|1] "" Vector__XXX

 SG_ RecircActIntegrityFault : 44|1@1+ (1,0) [0|1] "" Vector__XXX

 SG_ BlowerIntegrityFault : 43|1@1+ (1,0) [0|1] "" Vector__XXX

 SG_ TAirOutSensorIntegrityFault : 42|1@1+ (1,0) [0|1] "" Vector__XXX

 SG_ TAirInSensorIntegrityFault : 41|1@1+ (1,0) [0|1] "" Vector__XXX

 SG_ TChillerCoreSensorIntegrityFault : 40|1@1+ (1,0) [0|1] "" Vector__XXX

 SG_ TargetTemperatureState : 24|16@1+ (0.03125,-273) [-273|1774.96875] "C" Vector__XXX

 SG_ OutletSelectionState : 16|4@1+ (1,0) [0|15] "" Vector__XXX

 SG_ DemistRequestState : 12|4@1+ (1,0) [0|15] "" Vector__XXX

 SG_ ClimateControlEnableState : 8|4@1+ (1,0) [0|15] "" Vector__XXX

 SG_ BlowerSpeedRequestState : 4|4@1+ (1,0) [0|15] "" Vector__XXX

 SG_ CirculationRequestState : 0|4@1+ (1,0) [0|15] "" Vector__XXX

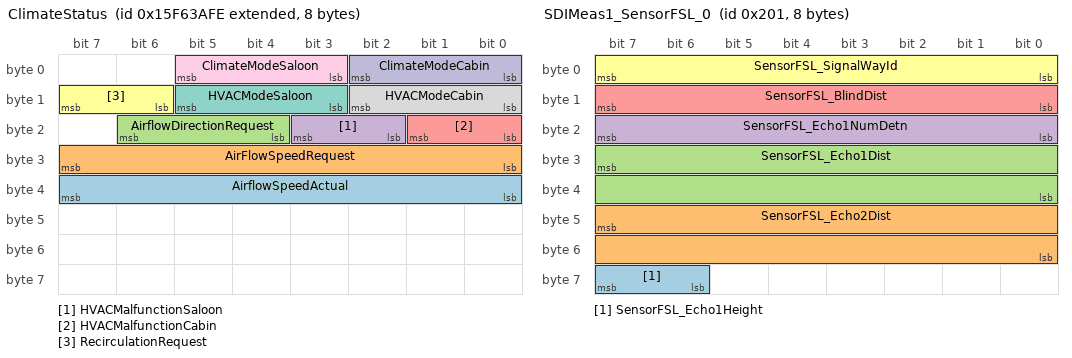
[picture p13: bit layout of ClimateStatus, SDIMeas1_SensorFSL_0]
BO_ 2515942142 ClimateStatus: 8 Vector__XXX

 SG_ AirflowSpeedActual : 32|8@1+ (0.5,0) [0|127.5] "" Vector__XXX

 SG_ AirFlowSpeedRequest : 24|8@1+ (0.4,0) [0|102] "%" Vector__XXX

 SG_ AirflowDirectionRequest : 20|3@1+ (1,0) [0|7] "" Vector__XXX

 SG_ HVACMalfunctionSaloon : 18|2@1+ (1,0) [0|0] "" Vector__XXX

 SG_ HVACMalfunctionCabin : 16|2@1+ (1,0) [0|0] "" Vector__XXX

 SG_ RecirculationRequest : 14|2@1+ (1,0) [0|3] "" Vector__XXX

 SG_ HVACModeSaloon : 11|3@1+ (1,0) [0|0] "" Vector__XXX

 SG_ HVACModeCabin : 8|3@1+ (1,0) [0|0] "" Vector__XXX

 SG_ ClimateModeSaloon : 3|3@1+ (1,0) [0|0] "" Vector__XXX

 SG_ ClimateModeCabin : 0|3@1+ (1,0) [0|0] "" Vector__XXX

BO_ 2516060670 ParkAssistRequest: 8 Vector__XXX

 SG_ paEnableReq : 8|2@1+ (1,0) [0|0] "" Vector__XXX

 SG_ paAutoReq : 0|8@1+ (1,0) [0|255] "" Vector__XXX

BO_ 513 SDIMeas1_SensorFSL_0: 8 SDI

 SG_ SensorFSL_Echo1Height : 63|2@0+ (1,0) [0|3] ""  Tester

 SG_ SensorFSL_Echo2Dist : 47|16@0+ (1,0) [0|65535] "mm"  Tester

 SG_ SensorFSL_Echo1Dist : 31|16@0+ (1,0) [0|65535] "mm"  Tester

 SG_ SensorFSL_Echo1NumDetn : 23|8@0+ (1,0) [0|255] "Unitless"  Tester

 SG_ SensorFSL_BlindDist : 15|8@0+ (4,0) [0|1020] "mm"  Tester

 SG_ SensorFSL_SignalWayId : 7|8@0+ (1,0) [0|255] ""  Tester

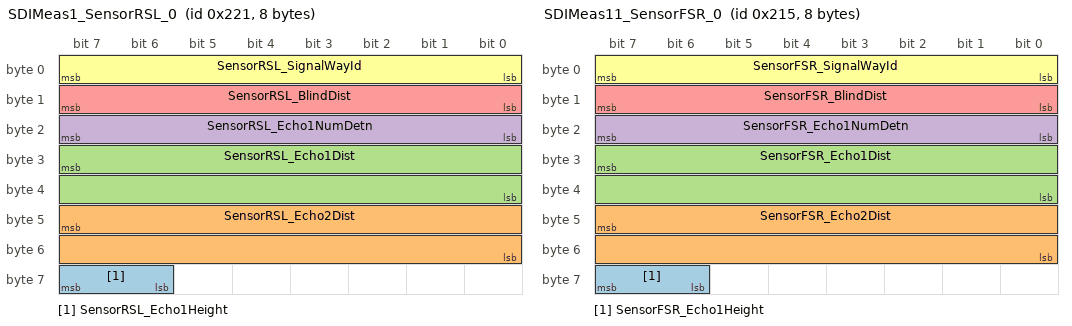
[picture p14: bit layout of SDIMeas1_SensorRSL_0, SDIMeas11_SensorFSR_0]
BO_ 545 SDIMeas1_SensorRSL_0: 8 SDI

 SG_ SensorRSL_Echo1Height : 63|2@0+ (1,0) [0|3] ""  Tester

 SG_ SensorRSL_Echo2Dist : 47|16@0+ (1,0) [0|65535] "mm"  Tester

 SG_ SensorRSL_Echo1Dist : 31|16@0+ (1,0) [0|65535] "mm"  Tester

 SG_ SensorRSL_Echo1NumDetn : 23|8@0+ (1,0) [0|255] "Unitless"  Tester

 SG_ SensorRSL_BlindDist : 15|8@0+ (4,0) [0|1020] "mm"  Tester

 SG_ SensorRSL_SignalWayId : 7|8@0+ (1,0) [0|255] ""  Tester

BO_ 533 SDIMeas11_SensorFSR_0: 8 SDI

 SG_ SensorFSR_Echo1Height : 63|2@0+ (1,0) [0|3] ""  Tester

 SG_ SensorFSR_Echo2Dist : 47|16@0+ (1,0) [0|65535] "mm"  Tester

 SG_ SensorFSR_Echo1Dist : 31|16@0+ (1,0) [0|65535] "mm"  Tester

 SG_ SensorFSR_Echo1NumDetn : 23|8@0+ (1,0) [0|255] "Unitless"  Tester

 SG_ SensorFSR_BlindDist : 15|8@0+ (4,0) [0|1020] "mm"  Tester

 SG_ SensorFSR_SignalWayId : 7|8@0+ (1,0) [0|255] ""  Tester

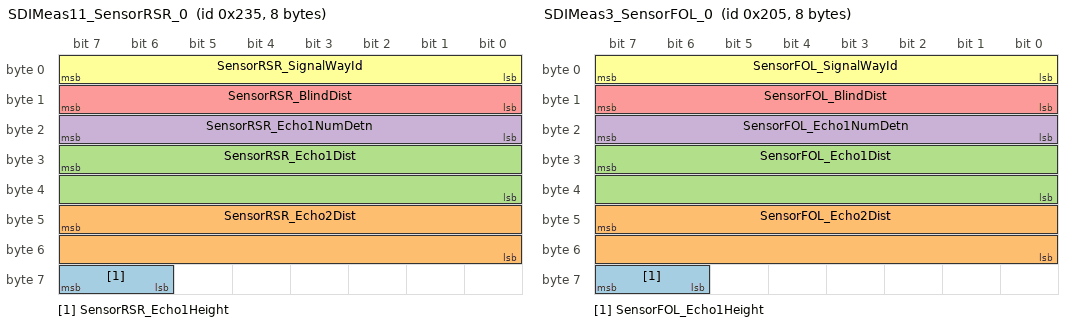
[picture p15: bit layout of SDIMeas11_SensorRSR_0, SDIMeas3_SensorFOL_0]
BO_ 565 SDIMeas11_SensorRSR_0: 8 SDI

 SG_ SensorRSR_Echo1Height : 63|2@0+ (1,0) [0|3] ""  Tester

 SG_ SensorRSR_Echo2Dist : 47|16@0+ (1,0) [0|65655] "mm"  Tester

 SG_ SensorRSR_Echo1Dist : 31|16@0+ (1,0) [0|65655] "mm"  Tester

 SG_ SensorRSR_Echo1NumDetn : 23|8@0+ (1,0) [0|255] "Unitless"  Tester

 SG_ SensorRSR_BlindDist : 15|8@0+ (4,0) [0|1020] "mm"  Tester

 SG_ SensorRSR_SignalWayId : 7|8@0+ (1,0) [0|255] ""  Tester

BO_ 517 SDIMeas3_SensorFOL_0: 8 SDI

 SG_ SensorFOL_Echo1Height : 63|2@0+ (1,0) [0|3] ""  Tester

 SG_ SensorFOL_Echo2Dist : 47|16@0+ (1,0) [0|65535] "mm"  Tester

 SG_ SensorFOL_Echo1Dist : 31|16@0+ (1,0) [0|65535] "mm"  Tester

 SG_ SensorFOL_Echo1NumDetn : 23|8@0+ (1,0) [0|255] "Unitless"  Tester

 SG_ SensorFOL_BlindDist : 15|8@0+ (4,0) [0|1020] "mm"  Tester

 SG_ SensorFOL_SignalWayId : 7|8@0+ (1,0) [0|255] ""  Tester

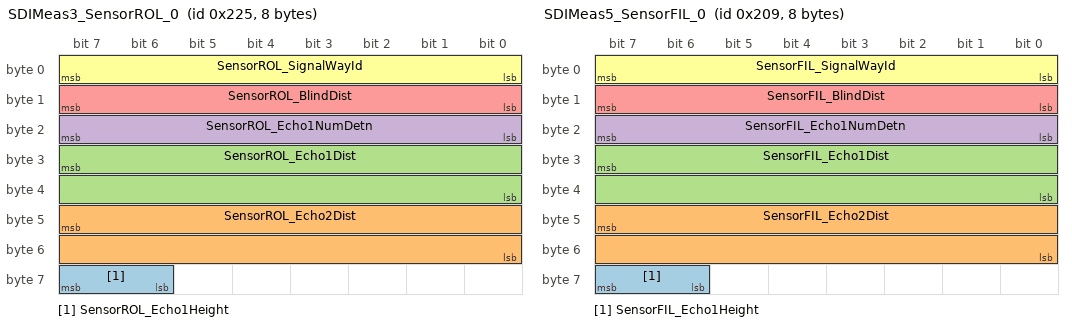
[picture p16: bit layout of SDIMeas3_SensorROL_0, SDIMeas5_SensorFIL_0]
BO_ 549 SDIMeas3_SensorROL_0: 8 SDI

 SG_ SensorROL_Echo1Height : 63|2@0+ (1,0) [0|3] ""  Tester

 SG_ SensorROL_Echo2Dist : 47|16@0+ (1,0) [0|65535] "mm"  Tester

 SG_ SensorROL_Echo1Dist : 31|16@0+ (1,0) [0|65535] "mm"  Tester

 SG_ SensorROL_Echo1NumDetn : 23|8@0+ (1,0) [0|255] "Unitless"  Tester

 SG_ SensorROL_BlindDist : 15|8@0+ (4,0) [0|1020] "mm"  Tester

 SG_ SensorROL_SignalWayId : 7|8@0+ (1,0) [0|255] ""  Tester

BO_ 521 SDIMeas5_SensorFIL_0: 8 SDI

 SG_ SensorFIL_Echo1Height : 63|2@0+ (1,0) [0|3] ""  Tester

 SG_ SensorFIL_Echo2Dist : 47|16@0+ (1,0) [0|65535] "mm"  Tester

 SG_ SensorFIL_Echo1Dist : 31|16@0+ (1,0) [0|65535] "mm"  Tester

 SG_ SensorFIL_Echo1NumDetn : 23|8@0+ (1,0) [0|255] "Unitless"  Tester

 SG_ SensorFIL_BlindDist : 15|8@0+ (4,0) [0|1020] "mm"  Tester

 SG_ SensorFIL_SignalWayId : 7|8@0+ (1,0) [0|255] ""  Tester

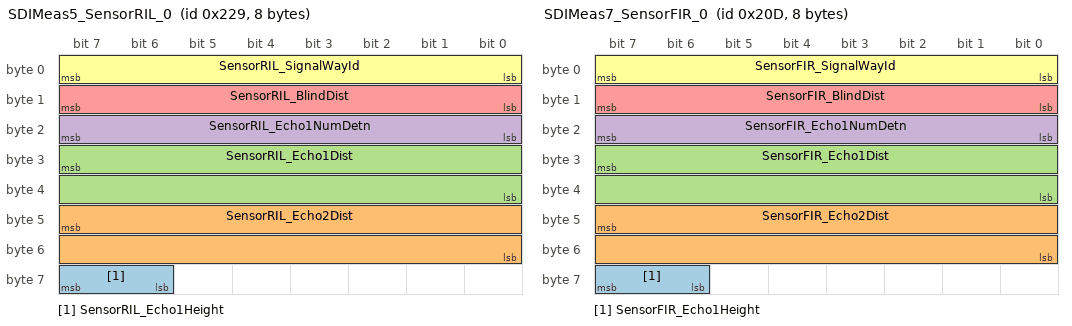
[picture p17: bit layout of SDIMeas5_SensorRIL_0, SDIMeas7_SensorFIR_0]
BO_ 553 SDIMeas5_SensorRIL_0: 8 SDI

 SG_ SensorRIL_Echo1Height : 63|2@0+ (1,0) [0|3] ""  Tester

 SG_ SensorRIL_Echo2Dist : 47|16@0+ (1,0) [0|65535] "mm"  Tester

 SG_ SensorRIL_Echo1Dist : 31|16@0+ (1,0) [0|65535] "mm"  Tester

 SG_ SensorRIL_Echo1NumDetn : 23|8@0+ (1,0) [0|255] "Unitless"  Tester

 SG_ SensorRIL_BlindDist : 15|8@0+ (4,0) [0|1020] "mm"  Tester

 SG_ SensorRIL_SignalWayId : 7|8@0+ (1,0) [0|255] ""  Tester

BO_ 525 SDIMeas7_SensorFIR_0: 8 SDI

 SG_ SensorFIR_Echo1Height : 63|2@0+ (1,0) [0|3] ""  Tester

 SG_ SensorFIR_Echo2Dist : 47|16@0+ (1,0) [0|65535] "mm"  Tester

 SG_ SensorFIR_Echo1Dist : 31|16@0+ (1,0) [0|65535] "mm"  Tester

 SG_ SensorFIR_Echo1NumDetn : 23|8@0+ (1,0) [0|255] "Unitless"  Tester

 SG_ SensorFIR_BlindDist : 15|8@0+ (4,0) [0|1020] "mm"  Tester

 SG_ SensorFIR_SignalWayId : 7|8@0+ (1,0) [0|255] ""  Tester

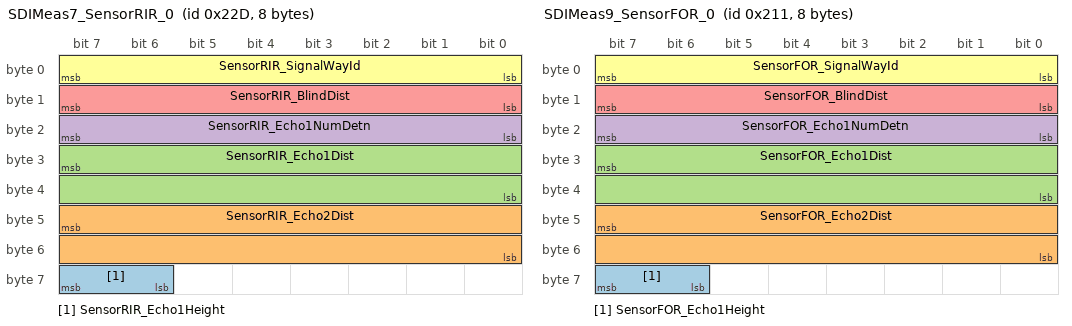
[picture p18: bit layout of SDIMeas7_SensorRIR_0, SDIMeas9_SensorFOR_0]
BO_ 557 SDIMeas7_SensorRIR_0: 8 SDI

 SG_ SensorRIR_Echo1Height : 63|2@0+ (1,0) [0|3] ""  Tester

 SG_ SensorRIR_Echo2Dist : 47|16@0+ (1,0) [0|65575] "mm"  Tester

 SG_ SensorRIR_Echo1Dist : 31|16@0+ (1,0) [0|65575] "mm"  Tester

 SG_ SensorRIR_Echo1NumDetn : 23|8@0+ (1,0) [0|255] "Unitless"  Tester

 SG_ SensorRIR_BlindDist : 15|8@0+ (4,0) [0|1020] "mm"  Tester

 SG_ SensorRIR_SignalWayId : 7|8@0+ (1,0) [0|255] ""  Tester

BO_ 529 SDIMeas9_SensorFOR_0: 8 SDI

 SG_ SensorFOR_Echo1Height : 63|2@0+ (1,0) [0|3] ""  Tester

 SG_ SensorFOR_Echo2Dist : 47|16@0+ (1,0) [0|65535] "mm"  Tester

 SG_ SensorFOR_Echo1Dist : 31|16@0+ (1,0) [0|65535] "mm"  Tester

 SG_ SensorFOR_Echo1NumDetn : 23|8@0+ (1,0) [0|255] "Unitless"  Tester

 SG_ SensorFOR_BlindDist : 15|8@0+ (4,0) [0|1020] "mm"  Tester

 SG_ SensorFOR_SignalWayId : 7|8@0+ (1,0) [0|255] ""  Tester

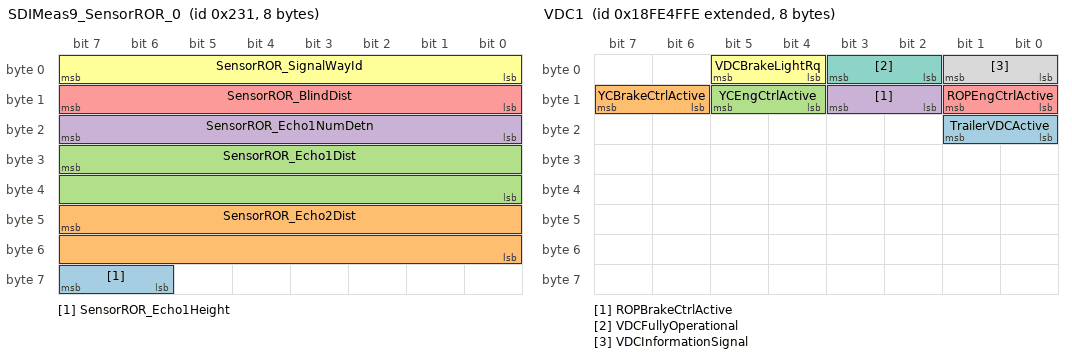
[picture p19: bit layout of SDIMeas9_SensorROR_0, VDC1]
BO_ 561 SDIMeas9_SensorROR_0: 8 SDI

 SG_ SensorROR_Echo1Height : 63|2@0+ (1,0) [0|3] ""  Tester

 SG_ SensorROR_Echo2Dist : 47|16@0+ (1,0) [0|65615] "mm"  Tester

 SG_ SensorROR_Echo1Dist : 31|16@0+ (1,0) [0|65615] "mm"  Tester

 SG_ SensorROR_Echo1NumDetn : 23|8@0+ (1,0) [0|255] "Unitless"  Tester

 SG_ SensorROR_BlindDist : 15|8@0+ (4,0) [0|1020] "mm"  Tester

 SG_ SensorROR_SignalWayId : 7|8@0+ (1,0) [0|255] ""  Tester

BO_ 2516060414 ParkAssistStatus: 8 Vector__XXX

 SG_ paStatus : 0|8@1+ (1,0) [0|255] "" Vector__XXX

BO_ 2516059134 ParkAssistData1to4: 8 Vector__XXX

 SG_ D4 : 48|16@1+ (1,0) [0|65535] "mm" Vector__XXX

 SG_ D3 : 32|16@1+ (1,0) [0|65535] "mm" Vector__XXX

 SG_ D2 : 16|16@1+ (1,0) [0|65535] "mm" Vector__XXX

 SG_ D1 : 0|16@1+ (1,0) [0|65535] "mm" Vector__XXX

BO_ 2516059390 ParkAssistData5to8: 8 Vector__XXX

 SG_ D8 : 48|16@1+ (1,0) [0|65535] "mm" Vector__XXX

 SG_ D7 : 32|16@1+ (1,0) [0|65535] "mm" Vector__XXX

 SG_ D6 : 16|16@1+ (1,0) [0|65535] "mm" Vector__XXX

 SG_ D5 : 0|16@1+ (1,0) [0|65535] "mm" Vector__XXX

BO_ 2516059646 ParkAssistData9to12: 8 Vector__XXX

 SG_ D9 : 48|16@1+ (1,0) [0|65535] "mm" Vector__XXX

 SG_ D12 : 32|16@1+ (1,0) [0|65535] "mm" Vector__XXX

 SG_ D11 : 16|16@1+ (1,0) [0|65535] "mm" Vector__XXX

 SG_ D10 : 0|16@1+ (1,0) [0|65535] "mm" Vector__XXX

BO_ 2566803454 VDC1: 8 Vector__XXX

 SG_ TrailerVDCActive : 16|2@1+ (1,0) [0|3] "" Vector__XXX

 SG_ YCBrakeCtrlActive : 14|2@1+ (1,0) [0|3] "" Vector__XXX

 SG_ YCEngCtrlActive : 12|2@1+ (1,0) [0|3] "" Vector__XXX

 SG_ ROPBrakeCtrlActive : 10|2@1+ (1,0) [0|3] "" Vector__XXX

 SG_ ROPEngCtrlActive : 8|2@1+ (1,0) [0|3] "" Vector__XXX

 SG_ VDCBrakeLightRq : 4|2@1+ (1,0) [0|3] "" Vector__XXX

 SG_ VDCFullyOperational : 2|2@1+ (1,0) [0|3] "" Vector__XXX

 SG_ VDCInformationSignal : 0|2@1+ (1,0) [0|3] "" Vector__XXX

CM_ SG_ 2180423678 rllrShttrLckActtRq "Indicates the roller shutter lock state report to the HMI";

CM_ SG_ 2381750526 hzrdSwtchStt "A 2 bit parameter to indicate the selected position of operator's switch";

CM_ SG_ 2381750782 rghtDRLStt "This parameter provides measured data from a center brake lamps

00 De activated
01 Activated
10 Fault Detected
11 Not Available";

CM_ SG_ 2381750782 frntLftPstnLmpStt "This parameter provides measured data from a center brake lamps

00 De activated
01 Activated
10 Fault Detected
11 Not Available";

CM_ SG_ 2381750782 frntRghtPstnLmpCmd "Command to activate or deactivate a brake lighs

00 De activate
01 Activate
10 Reserved
11 Don't Care";

CM_ SG_ 2381750782 LftDRLCmmnd "Command to activate or deactivate a brake lighs

00 De activate
01 Activate
10 Reserved
11 Don't Care";

CM_ SG_ 2381750782 RrFgLmpCmd "Command to activate or deactivate a brake lighs

00 De activate
01 Activate
10 Reserved
11 Don't Care";

CM_ SG_ 2381750782 rrLftPstnLmpCmd "Command to activate or deactivate a brake lighs

00 De activate
01 Activate
10 Reserved
11 Don't Care";

CM_ SG_ 2381750782 rrRgstrtnPltLmpCmd "Command to activate or deactivate a brake lighs

00 De activate
01 Activate
10 Reserved
11 Don't Care";

CM_ SG_ 2381750782 dppdBmLmpCmd "Command to activate or deactivate a brake lighs

00 De activate
01 Activate
10 Reserved
11 Don't Care";

CM_ SG_ 2381750782 mnBmLmpCmd "Command to activate or deactivate a brake lighs

00 De activate
01 Activate
10 Reserved
11 Don't Care";

CM_ SG_ 2381750782 cttRghtSdLmp "Command to activate or deactivate a brake lighs

00 De activate
01 Activate
10 Reserved
11 Don't Care";

CM_ SG_ 2381750782 cttLftSdLmp "Command to activate or deactivate a brake lighs

00 De activate
01 Activate
10 Reserved
11 Don't Care";

CM_ SG_ 2381751038 lftDRLStt "This parameter provides measured data from a center brake lamps

00 De activated
01 Activated
10 Fault Detected
11 Not Available";

CM_ SG_ 2381751038 LftDppdBmLmpStt "This parameter provides measured data from a center brake lamps

00 De activated
01 Activated
10 Fault Detected
11 Not Available";

CM_ SG_ 2381751038 LftMnBmLmpStt "This parameter provides measured data from a center brake lamps

00 De activated
01 Activated
10 Fault Detected
11 Not Available";

CM_ SG_ 2381751038 frntRghtPstnLmpStt "This parameter provides measured data from a center brake lamps

00 De activated
01 Activated
10 Fault Detected
11 Not Available";

CM_ SG_ 2381751038 lftSdIndctrStt "This parameter provides measured data from a center brake lamps

00 De activated
01 Activated
10 Fault Detected
11 Not Available";

CM_ SG_ 2381751038 frntRghtIndctrStt "This parameter provides measured data from a center brake lamps

00 De activated
01 Activated
10 Fault Detected
11 Not Available";

CM_ SG_ 2381751038 frntLftIndctrStt "This parameter provides measured data from a center brake lamps

00 De activated
01 Activated
10 Fault Detected
11 Not Available";

CM_ SG_ 2381751294 rghtBrkLmpStt "This parameter provides measured data from a center brake lamps

00 De activated
01 Activated
10 Fault Detected
11 Not Available";

CM_ SG_ 2381751294 rrRghtPstnLmpStt "This parameter provides measured data from a center brake lamps

00 De activated
01 Activated
10 Fault Detected
11 Not Available";

CM_ SG_ 2381751294 rrRghtIndctrStt "This parameter provides measured data from a center brake lamps

00 De activated
01 Activated
10 Fault Detected
11 Not Available";

CM_ SG_ 2381751550 RrLftFgLmpStt "This parameter provides measured data from a center brake lamps

00 De activated
01 Activated
10 Fault Detected
11 Not Available";

CM_ SG_ 2381751550 rrLftPstnLmpStt "This parameter provides measured data from a center brake lamps

00 De activated
01 Activated
10 Fault Detected
11 Not Available";

CM_ SG_ 2381751550 rrLftIndctrStt "This parameter provides measured data from a center brake lamps

00 De activated
01 Activated
10 Fault Detected
11 Not Available";

CM_ SG_ 2381751550 brkLmpsCmmnd "Command to activate or deactivate a brake lighs

00 De activate
01 Activate
10 Reserved
11 Don't Care";

CM_ SG_ 2583078398 blkhdDrLtchStt "Actual state of the door latch";

CM_ SG_ 2583078654 blkhdDrLtchRq "DoorUnlatchReq";

CM_ SG_ 2583078654 pssDrLtchRq "DoorUnlatchReq";

CM_ SG_ 2583078654 drvrDrLtchRq "DoorUnlatchReq";

CM_ SG_ 2583078910 pssDrLtchStt "The status of vehicle door";

CM_ SG_ 2583079166 snsdSrvcHtchStt "State of service hatch";

CM_ SG_ 2583210494 WshrCmmnd "Command from the Washer Controller to the Washer Driver.";

CM_ BO_ 2365443838 "The message containing the request on external light sources from the operator's external light control switch(s).";

CM_ SG_ 2365443838 MainBeamStalksReq "A 2 bit parameter to indicate the selected position of the operator's main light stalk";

CM_ SG_ 2365443838 TurnIndReq "A 4 bit parameter to indicate the selected position of the operator's turn signal stalk";

CM_ SG_ 2365443838 SwitchReq "A 2 bit parameter to indicate the selected position of operator's switch";

CM_ BO_ 2565868030 "Vehicle Dynamic Stability Control 2
Contains information which relates to the vehicle's movement.";

CM_ SG_ 2565868030 LongitudinalAcceleration "Indicates the longitudinal acceleration of the vehicle. A positive longitudinal acceleration signal results when the vehicle speed increases, regardless of driving the vehicle forward or backward.  This parameter is applicable to vehicle speed ...";

CM_ SG_ 2565868030 LateralAcceleration "Indicates a lateral acceleration of the vehicle (the component of vehicle acceleration vector along the Y-axis). A positive lateral acceleration signal results when the vehicle is accelerated to the left.  This parameter is defined according to a ...";

CM_ SG_ 2565868030 YawRate "Indicates the rate of rotation about the vertical axis (i.e. the z-axis).  A positive yaw rate signal results when the vehicle turns counter-clockwise.   This parameter is defined according to a Z-Up axis system and the sign of the value is in ...";

CM_ SG_ 2565868030 SteerWheelAngleSensorType "Indicates whether the steering wheel angle sensor is capable of absolute measuring of the number of steering wheel turns or not (relative measuring to position at ignition on).
00 Relative measuring principle
01 Absolute measuring principle
10 ...";

CM_ SG_ 2565868030 SteerWheelTurnCounter "Indicates number of steering wheel turns, absolute position or relative position at ignition on. Positive values indicate left turns.";

CM_ SG_ 2565868030 SteerWheelAngle "The main operator`s steering wheel angle (on the steering column, not the actual wheel angle).  The vehicle being steered to the left (counterclockwise) results in a positive steering wheel angle.  This is the yaw angle of the steering wheel with ...";

CM_ BO_ 2566767870 "Electronic Brake Controller 5
Used for information on brake control.";

CM_ SG_ 2566767870 EmergencyBrakingActive "Signal which indicates an emergency braking situation (ref. ECE Regulation 13 paragraph 5.2.1.31) with high  deceleration values.  This signal can be used to activate the hazard lights (ref ECE Regulation 48 paragraph 6.23) to
indicate other road ...";

CM_ SG_ 2566767870 PrkngBrakeActuatorFullyActivated "Signal which indicates when the parking brake actuator is fully activated.  (see also SPN 70 and 619).

00 - Parking Brake Actuator not fully activated
01 - Parking Brake Actuator fully activated
10 - Error
11 - Not available";

CM_ SG_ 2566767870 XBRAccelerationLimit "The brake system may temporarily or generally limit the maximum brake performance available for external systems. A temporary limit may be nessary due to high brake temperature; a general limit may be defined by the vehicle manufacturer, e.g. a ...";

CM_ SG_ 2566767870 XBRActiveCtrlMode "This parameter indicates which XBR Control Mode is executed by the brake system.
0000                No brake demand being executed (default mode)
0001                Driver's brake demand being executed, no external brake demand
0010 ...";

CM_ SG_ 2566767870 XBRSystemState "This parameter indicates which external brake control is allowed.
00 - Any external brake demand will be accepted (brake system fully operational)
01 - Only external brake demand of highest XBR Priority (00) will be accepted  (e.g. because the ...";

CM_ SG_ 2566767870 FoundationBrakeUse "This parameter indicates if the brake system presently uses the foundation brakes.

00   Foundation brakes not in use
01   Foundation brakes in use
10   Reserved
11   Not available";

CM_ SG_ 2566767870 HillHolderMode "Signal which indicates the current mode of the hill holder function.
000            Inactive
001            Active
010            Active, but will change to inactive in a short time.  (This mode may be used to warn the driver)
011 ...";

CM_ SG_ 2566767870 HaltBrakeMode "Signal which indicates the current mode of the halt brake function.
000            Inactive
001            Active
010            Active, but not functioning properly.  (This mode may be used to warn the driver)
011 - 101  Not defined
110 ...";

CM_ SG_ 2566767870 BrakeTempWarning "This parameter indicates if the temperature in the service brakes exceeds a certain value. It can be used for a warning information for the driver. The temperature warning value is vehicle manufacturer specific.
00 Not Active
01 Active
10 ...";

CM_ BO_ 2365484286 "Tachograph";

CM_ SG_ 2365484286 TachographVehicleSpeed "Speed of the vehicle registered by the tachograph.";

CM_ SG_ 2365484286 TachographOutputShaftSpeed "Calculated speed of the transmission output shaft.";

CM_ SG_ 2365484286 DirectionIndicator "Indicates the direction of the vehicle.

00 - Forward
01 - Reverse
10 - Error
11 - Not available";

CM_ SG_ 2365484286 TachographPerformance "Indicates the tachograph performance; including electronic or mechanical analysis, instrument analysis, speed sensor analysis, mass storage analysis, and printer analysis.
00 - Normal performance
01 - Performance analysis
10 - Error
11 - Not ...";

CM_ SG_ 2365484286 HandlingInformation "Indicates that handling information is present.  Information could include 'no printer paper', 'no driver card', etc.

00 - No handling information
01 - Handling information
10 - Error
11 - Not available";

CM_ SG_ 2365484286 SystemEvent "Indicates that a tachograph event has occurred.  This may include power supply interruption, interruption of the speed sensor, incorrect data on the driver card, driving without a driver card, illegal removal of a driver card, insertion of a driver ...";

CM_ SG_ 2365484286 DriverCardDriver2 "Indicates the presence of a driver card

00 - Driver card not present
01 - Driver card present
10 - Error
11 - Not available";

CM_ SG_ 2365484286 Driver2TimeRelatedStates "Indicates if the driver approaches or exceeds working time limits (or other limits).
0000 Normal/No limits reached
0001 Limit #1 - 15 min before 4  h
0010 Limit #2 - 4  h reached
0011 Limit #3 - 15 min before 9 h
0100 Limit #4 - 9 h reached
 ...";

CM_ SG_ 2365484286 VehicleOverspeed "Indicates whether the vehicle is exceeding the legal speed limit set in the tachograph.

00 No overspeed
01 Overspeed
10 Error
11 Not available";

CM_ SG_ 2365484286 DriverCardDriver1 "Indicates the presence of a driver card

00 - Driver card not present
01 - Driver card present
10 - Error
11 - Not available";

CM_ SG_ 2365484286 Driver1TimeRelatedStates "Indicates if the driver approaches or exceeds working time limits (or other limits).
0000 Normal/No limits reached
0001 Limit #1 - 15 min before 4  h
0010 Limit #2 - 4  h reached
0011 Limit #3 - 15 min before 9 h
0100 Limit #4 - 9 h reached
 ...";

CM_ SG_ 2365484286 VehicleMotion "Indicates whether motion of the vehicle is detected or not.

00 Vehicle motion not detected
01 Vehicle motion detected
10 - Error
11 - Not available";

CM_ SG_ 2365484286 Driver2WorkingState "State of work of the driver.  

000 Rest - sleeping
001 Driver available - short break
010 Work - loading, unloading, working in an office
011 Drive - behind wheel 
100-101 Reserved
110 Error
111 Not available";

CM_ SG_ 2365484286 Driver1WorkingState "State of work of the driver.  

000 Rest - sleeping
001 Driver available - short break
010 Work - loading, unloading, working in an office
011 Drive - behind wheel 
100-101 Reserved
110 Error
111 Not available";

CM_ SG_ 2582766846 ACU_Active "State of siren ";

CM_ SG_ 2582766846 ACU_Alarm "State of alarm";

CM_ SG_ 2582766846 USS_Status "Arm or disarm USS status ";

CM_ SG_ 2582766846 ACU_Status "Arm or disarm ACU status ";

CM_ SG_ 2582766846 Intrusion_detected "State of intrusion detection
";

CM_ BO_ 2382314494 "Contains information about states of Gear Selector, Drivetrain, Gearbox Interlock and GS Request Sources.
";

CM_ SG_ 2382314494 GS_Inhibits "Gear Selector Request from VSM";

CM_ SG_ 2382314494 Inaccess_Req_5 "Flag  of the VSM request inaccessibility. If it is true then VSM GS request signal is valid but not correct in current circumstances";

CM_ SG_ 2382314494 Inaccess_Req_4 "Flag  of the HMI3 request inaccessibility. If it is true then HMI3 GS request signal is valid but not correct in current circumstances";

CM_ SG_ 2382314494 Inaccess_Req_3 "Flag  of the HMI2 request inaccessibility. If it is true then HMI2 GS request signal is valid but not correct in current circumstances";

CM_ SG_ 2382314494 Inaccess_Req_2 "Flag  of the HMI1 request inaccessibility. If it is true then HMI1 GS request signal is valid but not correct in current circumstances";

CM_ SG_ 2382314494 GS_Est_State "Gear Selector State estimated by Gear Selector module";

CM_ SG_ 2382314494 Drvtr_state "Drivetrain state calculated by Gear Selector module";

CM_ SG_ 2382314494 Inaccess_Req_1 "Flag  of the AI request inaccessibility. If it is true then AI GS request signal is valid but not correct in current circumstances";

CM_ SG_ 2382314494 move_lock_req "Move-locking device request";

CM_ SG_ 2382314494 GS_Demand "Gear selecor demand";

CM_ BO_ 2365473278 "Lighting Command
The lighting command message has been defined as a global message from the tractor to all lighting controllers on the tractor and attached implements.  Separate messages are provided for tractor and implement work and driving ...";

CM_ SG_ 2365473278 ImplementRearWorkLightCmd "Command to activate or de-activate implement rear work lights.  (This is also the same as Reversing Lights for truck applications.)  

00 De-activate
01 Activate
10 Reserved
11 Don't Care";

CM_ SG_ 2365473278 ImplLeftFacingWorkLightCmd "Command to activate or de-activate the left facing work lights toward the left end of the implement.

00 De-activate
01 Activate
10 Reserved
11 Don't Care";

CM_ SG_ 2365473278 ImplRightFwdWorkLightCmd "Command to activate or de-activate the forward facing work lights toward the right end of the implement.

00 De-activate
01 Activate
10 Reserved
11 Don't Care";

CM_ SG_ 2365473278 LightingDataRqCmd "Command to provide a response of the light state

00 De-activate
01 Activate
10 Reserved
11 Don't Care";

CM_ SG_ 2365473278 ImplLeftForwardWorkLightCmd "Command to activate or de-activate work lights mounted on an implement to illuminate beyond left end of the implement.

00 De-activate
01 Activate
10 Reserved
11 Don't Care";

CM_ SG_ 2365473278 ImplRightFacingWorkLightCmd "Command to activate or de-activate work lights mounted on an implement to illuminate beyond right end of the implement.

00 De-activate
01 Activate
10 Reserved
11 Don't Care";

CM_ SG_ 2365473278 ImplOEMOption1LightCmd "Command to activate or de-activate an implement OEM option 1 light.  This is provided to meet special needs on implements, such as tank inspection or filling lights.

00 De-activate
01 Activate
10 Reserved
11 Don't Care";

CM_ SG_ 2365473278 ImplOEMOption2LightCmd "Command to activate or de-activate an implement OEM option 2 light.  This is provided to meet special needs on implements, such as tank inspection or filling lights.

00 De-activate
01 Activate
10 Reserved
11 Don't Care";

CM_ SG_ 2365473278 TrctrFrntHghMdWkLightsCmd "Command to activate or de-activate the tractor front high mounted work lights.

00 De-activate
01 Activate
10 Reserved
11 Don't Care";

CM_ SG_ 2365473278 TrctrFrntLowMdWkLightsCmd "Command to activate or de-activate the tractor front low mounted work lights.

00 De-activate
01 Activate
10 Reserved
11 Don't Care";

CM_ SG_ 2365473278 TrctrSdeHighMdWkLightsCmd "Command to activate or de-activate the tractor side high mounted work lights.

00 De-activate
01 Activate
10 Reserved
11 Don't Care";

CM_ SG_ 2365473278 TrctrSideLowMdWkLightsCmd "Command to activate or de-activate the tractor side low mounted work lights.

00 De-activate
01 Activate
10 Reserved
11 Don't Care";

CM_ SG_ 2365473278 TrctrRarHighMdWkLightsCmd "Command to activate or de-activate the tractor rear high  mounted work lights.

00 De-activate
01 Activate
10 Reserved
11 Don't Care";

CM_ SG_ 2365473278 TrctrRearLowMdWkLightsCmd "Command to activate or de-activate the tractor rear low  mounted work lights.

00 De-activate
01 Activate
10 Reserved
11 Don't Care";

CM_ SG_ 2365473278 TrctrUndrsdeMdWkLightsCmd "Command to activate or de-activate the tractor underside mounted work lights.

00 De-activate
01 Activate
10 Reserved
11 Don't Care";

CM_ SG_ 2365473278 RearFogLightsCmd "Command to activate or de-activate tractor or implement rear fog lights.  

00 De-activate
01 Activate
10 Reserved
11 Don't Care";

CM_ SG_ 2365473278 TractorMarkerLightCmd "Command to activate or de-activate tractor and implement front position lights, rear red tail lights, side amber running lights, license plate lights and instrument and switch back lights.  

00 De-activate
01 Activate
10 Reserved
11 Don't Care";

CM_ SG_ 2365473278 ImplementMarkerLightCmd "Command to activate or de-activate implement front position lights, rear red tail lights, side amber running lights, license plate lights and instrument and switch back lights.  

00 De-activate
01 Activate
10 Reserved
11 Don't Care";

CM_ SG_ 2365473278 TractorClearanceLightCmd "Command to activate or de-activate the tractor high mounted clearance and center ID lights

00 De-activate
01 Activate
10 Reserved
11 Don't Care";

CM_ SG_ 2365473278 ImplementClearanceLightCmd "Command to activate or de-activate the implement high mounted clearance and lights.  

00 De-activate
01 Activate
10 Reserved
11 Don't Care";

CM_ SG_ 2365473278 LeftStopLightCmd "Command to activate or de-activate the tractor and implement left stop lights

00 De-activate
01 Activate
10 Reserved
11 Don't Care";

CM_ SG_ 2365473278 RightStopLightCmd "Command to activate or de-activate the tractor and implement right stop light

00 De-activate
01 Activate
10 Reserved
11 Don't Care";

CM_ SG_ 2365473278 CenterStopLightCmd "Command to activate or de-activate the tractor and implement center stop light

00 De-activate
01 Activate
10 Reserved
11 Don't Care";

CM_ SG_ 2365473278 BackUpLightAndAlarmHornCmd "Command to activate or de-activate the back up lights and/ or associated alarm if required

00 De-activate
01 Activate
10 Reserved
11 Don't Care";

CM_ SG_ 2365473278 LeftTurnSignalLightsCmd "Command to activate or de-activate left turn signal lights on the tractor and all connected implements

00 De-activate
01 Activate
10 Reserved
11 Don't Care";

CM_ SG_ 2365473278 RightTurnSignalLightsCmd "Command to activate or de-activate right turn signal lights on the tractor and all connected implements

00 De-activate
01 Activate
10 Reserved
11 Don't Care";

CM_ SG_ 2365473278 RotatingBeaconLightCmd "Command to activate or de-activate slow moving vehicle indicator lights on tractor and/or implements.  Activation of the slow moving vehicle lights implies that the controller should manipulate the lighting as appropriate to provide the slow moving ...";

CM_ SG_ 2365473278 TractorFrontFogLightsCmd "Command to activate or de-activate tractor front fog lights.

00 De-activate
01 Activate
10 Reserved
11 Don't Care";

CM_ SG_ 2365473278 HighBeamHeadLightCmd "Command to activate or de-activate the tractor high beam head light lamps. 

00 De-activate
01 Activate
10 Reserved
11 Don't Care";

CM_ SG_ 2365473278 LowBeamHeadLightCmd "Command to activate or de-activate the tractor low beam head light lamps. 

00 De-activate
01 Activate
10 Reserved
11 Don't Care";

CM_ SG_ 2365473278 AltBeamHeadLightCmd "Command to activate or de-activate the tractor alternate head lights (only low beam is available on alternate head lights).  The alternate position lights are intended for use with loader and snow plows that tend to block the primary head lights.
 ...";

CM_ SG_ 2365473278 RunningLightCmd "Command to activate or de-activate the tractor or powered vehicle running lights.  Usually only used for on road vehicles.

00 De-activate
01 Activate
10 Reserved
11 Don't Care";

CM_ BO_ 2399117310 "For DEBUG-TEST only! Consist of signals that can replace AIN siganls from Analog button block";

CM_ SG_ 2399117310 VSM_CRC "Gear selector request from AI";

CM_ SG_ 2399117310 VSM_Cnt "Gear selector request from AI";

CM_ SG_ 2399117310 VSM_State "Gear selector request from AI";

CM_ BO_ 2566799614 "Lighting Data
This lighting message is a response to the request for lighting data in the lighting command message.  Each lighting controller on the tractor and attached implements must transmit this message to the Tractor ECU when requested.  The ...";

CM_ SG_ 2566799614 ImplementRearWorkLight "This parameter provides measured data from the implement rear work lamps.

00 De-activated
01 Activated
10 Fault Detected
11 Not Available";

CM_ SG_ 2566799614 ImplLeftFacingWorkLight "This parameter provides measured data from the left facing work lights toward the left end of the implement.

00 De-activated
01 Activated
10 Fault Detected
11 Not Available";

CM_ SG_ 2566799614 ImplRightForwardWorkLight "This parameter provides measured data from the forward facing work lights toward the right end of the implement.

00 De-activated
01 Activated
10 Fault Detected
11 Not Available";

CM_ SG_ 2566799614 ImplLeftForwardWorkLight "This parameter provides measured data from the work lights mounted on an implement to illuminate the forward left end of the implement.

00 De-activate
01 Activate
10 Fault Detected
11 Not Available";

CM_ SG_ 2566799614 ImplRightFacingWorkLight "This parameter provides measured data from the work lights mounted on an implement to illuminate beyond right end of the implement.

00 De-activated
01 Activated
10 Fault Detected
11 Not Available";

CM_ SG_ 2566799614 ImplementOEMOption1Light "This parameter provides measured data from the implement OEM option 1 light.

00 De-activated
01 Activated
10 Fault Detected
11 Not Available";

CM_ SG_ 2566799614 ImplementOEMOption2Light "This parameter provides measured data from the implement OEM option 2 light.

00 De-activated
01 Activated
10 Fault Detected
11 Not Available";

CM_ SG_ 2566799614 TrctorFrontHighMdWkLights "This parameter provides measured data from the tractor front high mounted work lights. 

00 De-activated
01 Activated
10 Fault Detected
11 Not Available";

CM_ SG_ 2566799614 TractorFrontLowMdWkLights "This parameter provides measured data from the tractor front low mounted work lights. 

00 De-activated
01 Activated
10 Fault Detected
11 Not Available";

CM_ SG_ 2566799614 TractorSideHighMdWkLights "This parameter provides measured data from the tractor side high mounted work lights. 

00 De-activated
01 Activated
10 Fault Detected
11 Not Available";

CM_ SG_ 2566799614 TractorSideLowMdWkLights "This parameter provides measured data from the tractor side low mounted work lights. 

00 De-activated
01 Activated
10 Fault Detected
11 Not Available";

CM_ SG_ 2566799614 TractorRearHighMdWkLights "This parameter provides measured data from the tractor rear high mounted work lights. 

00 De-activated
01 Activated
10 Fault Detected
11 Not Available";

CM_ SG_ 2566799614 TractorRearLowMdWkLights "This parameter provides measured data from the tractor rear low mounted work lights.

00 De-activated
01 Activated
10 Fault Detected
11 Not Available";

CM_ SG_ 2566799614 TrctorUndersideMdWkLights "This parameter provides measured data from the tractor underside mounted work lights. 

00 De-activated
01 Activated
10 Fault Detected
11 Not Available";

CM_ SG_ 2566799614 RearFogLights "This parameter provides measured data from the tractor and/or implement rear fog lights.

00 De-activated
01 Activated
10 Fault Detected
11 Not Available";

CM_ SG_ 2566799614 TractorMarkerLight "This parameter provides measured data from the tractor and attached implement marker lights, including front position lights, rear tail lights, side running lights, license plate lights and instruments and switch back lights.
00 De-activated
01 ...";

CM_ SG_ 2566799614 ImplementMarkerLight "This parameter provides measured data from an attached implement marker lights, including front position lights, rear tail lights, side running lights, license plate lights and instruments and switch back lights.
00 De-activated
01 Activated
10 ...";

CM_ SG_ 2566799614 TractorClearanceLight "This parameter provides measured data from the tractor high mounted clearance and center ID lights.

00 De-activated
01 Activated
10 Fault Detected
11 Not Available";

CM_ SG_ 2566799614 ImplementClearanceLight "This parameter provides measured data from an attached implement high mounted clearance lights.

00 De-activated
01 Activated
10 Fault Detected
11 Not Available";

CM_ SG_ 2566799614 LeftStopLight "This parameter provides measured data from the tractor and attached implement left stop lights.

00 De-activated
01 Activated
10 Fault Detected
11 Not Available";

CM_ SG_ 2566799614 RightStopLight "This parameter provides measured data from the tractor and attached implement right stop lights.

00 De-activated
01 Activated
10 Fault Detected
11 Not Available";

CM_ SG_ 2566799614 CenterStopLight "This parameter provides measured data from the tractor and attached implement center stop lights.

00 De-activated
01 Activated
10 Fault Detected
11 Not Available";

CM_ SG_ 2566799614 BackUpLightAndAlarmHorn "This parameter provides measured data from the back up lights and/ or associated alarm.

00 De-activated
01 Activated
10 Fault Detected
11 Not Available";

CM_ SG_ 2566799614 LeftTurnSignalLights "This parameter provides measured data from the tractor and attached implement left turn signal lights.

00 De-activated
01 Activated
10 Fault Detected
11 Not Available";

CM_ SG_ 2566799614 RightTurnSignalLights "This parameter provides measured data from the tractor and attached implement right turn signal lights.

00 De-activated
01 Activated
10 Fault Detected
11 Not Available";

CM_ SG_ 2566799614 RotatingBeaconLight "This parameter provides measured data from the beacon light on tractor or attached implements.

00 De-activated
01 Activated
10 Fault Detected
11 Not Available";

CM_ SG_ 2566799614 TractorFrontFogLights "This parameter provides measured data from the tractor front fog lights.

00 De-activated
01 Activated
10 Fault Detected
11 Not Available";

CM_ SG_ 2566799614 HighBeamHeadLight "This parameter provides measured data from the tractor high beam head light lamps. 

00 De-activated
01 Activated
10 Fault Detected
11 Not Available";

CM_ SG_ 2566799614 LowBeamHeadLight "This parameter provides measured data from the tractor low beam head light lamps. 

00 De-activated
01 Activated
10 Fault Detected
11 Not Available";

CM_ SG_ 2566799614 AltBeamHeadLight "This parameter provides measured data from the tractor alternate beam head light lamps. 

00 De-activated
01 Activated
10 Fault Detected
11 Not Available";

CM_ SG_ 2566799614 RunningLight "This parameter provides measured data from the vehicle's running lights.

00 De-activated
01 Activated
10 Fault Detected
11 Not Available";

CM_ SG_ 2381851134 HornSwitchReq "True - horn switch request active
False - horn switch request not active";

CM_ BO_ 2314625790 "Ride Height Sensor Raw Information
This message shall provide raw measurements from corresponding sensor";

CM_ SG_ 2314625790 HeightMeasured "HeightMeasured = L*sin(RotationAngle), where L - sensor lever, default 50 mm accordance to Swoboda Ride Height Sensor specification";

CM_ SG_ 2314625790 RotationAngle "Raw Rotation Angle value which is obtained using the voltage-degree characteristic from Swoboda Ride Height Sensorspecification";

CM_ SG_ 2583062270 DoorsSleepReadyState "The status of all vehicle doors ";

CM_ SG_ 2583062270 CargoSideDoorLatchState "Actual state of the door latch";

CM_ SG_ 2583062270 CargoRearDoorLatchState "Actual state of the door latch";

CM_ SG_ 2583062270 BulkheadDoorLatchState "Actual state of the door latch";

CM_ SG_ 2583062270 PassDoorLatchState "Actual state of the door latch";

CM_ SG_ 2583062270 DriverDoorLatchState "Actual state of the door latch";

CM_ SG_ 2583062270 DoorsOpenState "The status of all vehicle doors ";

CM_ SG_ 2566882814 KeyRange "Key fob range state
";

CM_ SG_ 2566882814 KeyCommand "Key fob command for doors central locking
";

CM_ SG_ 2583062526 CentralLockRequest "State of user request for doors central locking
";

CM_ BO_ 2399123966 "For DEBUG-TEST only! Consist of signals that can replace AIN siganls from Analog button block";

CM_ SG_ 2399123966 KeyfobBatteryState "Actual State of the Keyfob Battery";

CM_ SG_ 2583065854 CentralLockRequest "State of user request for doors central locking
";

CM_ BO_ 2163223550 "Crash Notification
This message is transmitted in case of a crash event.
The message contains information about the Crash Type, a Crash Counter and a Checksum. The function of the Crash Counter is to prevent other ECU's from reacting to a faulty ...";

CM_ SG_ 2163223550 CrashChecksum "The Crash Checksum is used to verify the signal path from the airbag ECU to other devices in case of a crash.
The 4 bit checksum is the sum of the high nibble and the low nibble of the sum of the identifier, the first 7 data bytes and the 4 bit ...";

CM_ SG_ 2163223550 CrashCounter "The Crash Counter prevents other ECUs from reacting to a faulty transmission of the Crash Notification PGN and serves as a safety mechanism. The Crash Counter becomes incremented by 1 for every sent message, starting with '0'. (0 follows 15)";

CM_ SG_ 2163223550 CrashType "Type of crash event. 

00001 = frontal crash
00010 = rear crash
00100 = side crash (left)
01000 = side crash (right)
10000 = rollover

It is possible to combine different Crash Types. (e.g. frontal and side crash (left) = 00101)";

CM_ BO_ 2566847742 "Dash Display 1";

CM_ SG_ 2566847742 EngOilFilterDiffPress7471 "Change in engine oil pressure, measured across the filter, due to the filter and any accumulation of solid or semisolid material on or in the filter. See SPN 99 for alternate resolution.";

CM_ SG_ 2566847742 FuelLevel2 "Ratio of volume of fuel to the total volume of fuel in the second or right-side storage container.  When Fuel Level 2 is not used, Fuel Level 1 (SPN 96) represents the total fuel in all fuel storage containers.";

CM_ SG_ 2566847742 CargoAmbientTemp "Temperature of air inside vehicle container used to accommodate cargo.";

CM_ SG_ 2566847742 EngOilFilterDiffPress "Change in engine oil pressure, measured across the filter, due to the filter and any accumulation of solid or semisolid material on or in the filter.  See SPN 7471 for alternate resolution.";

CM_ SG_ 2566847742 EngFuelFilterDiffPress "Change in fuel delivery pressure, measured across the filter, due to accumulation of solid or semisolid matter on the filter element.";

CM_ SG_ 2566847742 FuelLevel1 "Ratio of volume of fuel to the total volume of fuel storage container.
When Fuel Level 2 (SPN 38) is not used, Fuel Level 1 represents the total fuel in all fuel storage containers.  When Fuel Level 2 is used, Fuel Level 1 represents the fuel level ...";

CM_ SG_ 2566847742 WasherFluidLevel "Ratio of volume of liquid to total container volume of fluid reservoir in windshield wash system.";

CM_ BO_ 2583173886 "Requests from the HMI to the Washer and Wiper controllers.";

CM_ SG_ 2583173886 WipeRequest "Request from the HMI to the Wiper Controller.";

CM_ SG_ 2583173886 WashRequest "Request from the HMI to the Washer Controller.";

CM_ BO_ 2516075518 "The message contains the actual status of the suspension height.
HDLGHTLVL 1.0.0->ActualRideHeight";

CM_ BO_ 2448847614 "Vehicle Weight message with measured data from Swoboda Ride Height Sensors";

CM_ SG_ 2448847614 RotationAngleRR "Raw Rotation Angle value which is obtained using the voltage-degree characteristic from Swoboda Ride Height Sensor specification";

CM_ SG_ 2448847614 HeightMeasuredRR "HeightMeasured = L*sin(RotationAngle), where L - sensor lever, default 50 mm accordance to Swoboda Ride Height Sensor specification
offset is not taken into account";

CM_ SG_ 2448847614 RotationAngleRL "Raw Rotation Angle value which is obtained using the voltage-degree characteristic from Swoboda Ride Height Sensor specification";

CM_ SG_ 2448847614 HeightMeasuredRL "HeightMeasured = L*sin(RotationAngle), where L - sensor lever, default 50 mm accordance to Swoboda Ride Height Sensor specification
offset is not taken into account";

CM_ SG_ 2448847614 RotationAngleFR "Raw Rotation Angle value which is obtained using the voltage-degree characteristic from Swoboda Ride Height Sensor specification";

CM_ SG_ 2448847614 HeightMeasuredFR "HeightMeasured = L*sin(RotationAngle), where L - sensor lever, default 50 mm accordance to Swoboda Ride Height Sensor specification
offset is not taken into account";

CM_ SG_ 2448847614 RotationAngleFL "Raw Rotation Angle value which is obtained using the voltage-degree characteristic from Swoboda Ride Height Sensor specification";

CM_ SG_ 2448847614 HeightMeasuredFL "HeightMeasured = L*sin(RotationAngle), where L - sensor lever, default 50 mm accordance to Swoboda Ride Height Sensor specification
offset is not taken into account";

CM_ BO_ 2448847102 "Vehicle Weight message with VGW information from Payload Management";

CM_ SG_ 2448847102 RHSensorsFault "Status of data flow from Ride Height Sensors";

CM_ SG_ 2448847102 PMSWarning "Figure of merit for ride height measurement.

00 - Ride height fully functional.  Data is within sensor specification. 
01 - Ride height degraded.  Data is suspect due to environmental conditions.
10 - Error
11 - Not available";

CM_ SG_ 2448847102 VehicleGrossWeight "Minimum value from ride height sensors measured on axles including distance unsprung mass";

CM_ BO_ 2448847358 "Vehicle Weight message with processed IMU  information from Payload Management";

CM_ SG_ 2448847358 IMUFault "Status of data flow from IMU";

CM_ BO_ 2297441790 "Acceleration Sensor
The acceleration sensor message shall provide a measurement of the vehicle's acceleration in the lateral, longitudinal, and vertical axes.  The vehicle dynamics measurements in this message shall be according to a Z-Up axis ...";

CM_ SG_ 2297441790 SpprtVrblTrnsRpttnRtFrAcclrtnSns "Indicates which acceleration transmission rate are supported by the ECU in addition to the required 10 ms transmission rate.
00 - Reserve for SAE assignment
01 - Reserved for SAE assignment
10 - 20 ms rate supported
11 - ECU only supports ...";

CM_ SG_ 2297441790 VrtclAcclrtnExRangeFigureOfMerit "Figure of merit for vertical acceleration measurement.
00 = vertical acceleration is fully functional.  Data is within sensor specification
01 = verticalacceleration is degraded.  Data is suspect due to enviromental conditions
10 = error
11 = ...";

CM_ SG_ 2297441790 LngtdnlAcclrtnExRngFigureOfMerit "Figure of merit for longitudinal acceleration measurement.
00 = longitudinal acceleration is fully functional.  Data is within sensor specification
01 = longitudinal acceleration is degraded.  Data is suspect due to enviromental conditions
10 = ...";

CM_ SG_ 2297441790 LtrlAcclrtonExRangeFigureOfMerit "Figure of merit for lateral acceleration measurement.
00 = lateral acceleration is fully functional.  Data is within sensor specification
01 = lateral acceleration is degraded.  Data is suspect due to enviromental conditions
10 = error
11 = not ...";

CM_ SG_ 2297441790 VerticalAccelerationExRange "Indicates vertical acceleration of the vehicle and the effect of gravity (the component of vehicle acceleration vector along the Z-axis).  A positive vertical acceleration signal of 1 gravity results when the vehicle is stationary on a horizontal ...";

CM_ SG_ 2297441790 LongitudinalAccelerationExRange "Indicates longitudinal acceleration of the vehicle (the component of vehicle acceleration vector along the X-axis).  A positive longitudinal acceleration signal results when the vehicle speed increases in the forward direction.  Longitudinal ...";

CM_ SG_ 2297441790 LateralAccelerationExRange "Indicates lateral acceleration of the vehicle (the component of vehicle acceleration vector along the Y-axis).  A positive lateral acceleration signal results when the vehicle is accelerated to the left.  This parameter is defined according to a ...";

CM_ BO_ 2499547902 "Cab Door Control
This message requests or commands the cabin door functionality; door latches, windows, and mirrors. Doors are numbered left to right, front to back.";

CM_ SG_ 2499547902 MirrorRight2HeatCmd "Command to activate heater for second mirror on the right side (passenger side for left-hand steer vehicle).  Mirror heat may be expected to latch in the 'on' state upon receipt of the command, stay on while the command is 'take no action' and turn ...";

CM_ SG_ 2499547902 MirrorLeft2HeatCmd "Command to activate heater for second mirror on the left side (driver side for left-hand steer vehicle).  Mirror heat may be expected to latch in the 'on' state upon receipt of the command, stay on while the command is 'take no action' and turn off ...";

CM_ SG_ 2499547902 MirrorRight1HeatCmd "Command to activate heater for primary mirror on the right side (passenger side for left-hand steer vehicle).  Mirror heat may be expected to latch in the 'on' state upon receipt of the command, stay on while the command is 'take no action' and turn ...";

CM_ SG_ 2499547902 MirrorLeft1HeatCmd "Command to activate heater for primary mirror on the left side (driver side for left-hand steer vehicle).  Mirror heat may be expected to latch in the 'on' state upon receipt of the command, stay on while the command is 'take no action' and turn off ...";

CM_ SG_ 2499547902 MirrorRight2VerticalCmd "Commands vertical position change of the second mirror on the right side (passenger side for lefthand steer vehicles).

00 = Move up
01 = Move down
10 = Reserved
11 = Take no action";

CM_ SG_ 2499547902 MirrorRight2HorizontalCmd "Commands horizontal position change of the second mirror on the right side (passenger side for lefthand steer vehicles).

00 = Move left
01 = Move right
10 = Reserved
11 = Take no action";

CM_ SG_ 2499547902 MirrorLeft2VerticalCmd "Commands vertical position change of the second mirror on the left side (driver side for left-hand steer vehicles). 

00 = Move up
01 = Move down
10 = Reserved
11 = Take no action";

CM_ SG_ 2499547902 MirrorLeft2HorizontalCmd "Commands horizontal position change of the second mirror on the left side (driver side for left-hand steer vehicles).

00 = Move left
01 = Move right
10 = Reserved
11 = Take no action";

CM_ SG_ 2499547902 MirrorRight1VerticalCmd "Commands vertical position change of the primary mirror on the right side (passenger side for lefthand steer vehicles).

00 = Move up
01 = Move down
10 = Reserved
11 = Take no action";

CM_ SG_ 2499547902 MirrorRight1HorizontalCmd "Commands horizontal position change of the primary mirror on the right side (passenger side for lefthand steer vehicles).

00 = Move left
01 = Move right
10 = Reserved
11 = Take no action";

CM_ SG_ 2499547902 MirrorLeft1VerticalCmd "Commands vertical position change of the primary mirror on the left side (driver side for left-hand steer vehicles).

00 = Move up
01 = Move down
10 = Reserved
11 = Take no action";

CM_ SG_ 2499547902 MirrorLeft1HorizontalCmd "Commands horizontal position change of the primary mirror on the left side (driver side for left-hand steer vehicles).

00 = Move left
01 = Move right
10 = Reserved
11 = Take no action";

CM_ SG_ 2499547902 RightRearWindowPosCmd "Commands position change of the right rear window.

000 = Window move up
001 = Window move down
010 = Window auto up
011 = Window auto down
100 = Reserved
101 = Reserved
110 = Reserved
111 = Take no action";

CM_ SG_ 2499547902 LeftRearWindowPosCmd "Commands position change of left rear window.

000 = Window move up
001 = Window move down
010 = Window auto up
011 = Window auto down
100 = Reserved
101 = Reserved
110 = Reserved
111 = Take no action";

CM_ SG_ 2499547902 RightFrontWindowPosCmd "Commands position change of right front window (passenger door window on left-hand steer vehicles).
000 = Window move up
001 = Window move down
010 = Window auto up
011 = Window auto down
100 = Reserved
101 = Reserved
110 = Reserved
111 = ...";

CM_ SG_ 2499547902 LeftFrontWindowPosCmd "Commands position change of left front window (driver door window on left-hand steer vehicles).
000 = Window move up
001 = Window move down
010 = Window auto up
011 = Window auto down
100 = Reserved
101 = Reserved
110 = Reserved
111 = Take ...";

CM_ SG_ 2499547902 RemoteCabDoorLockReq "Request to the cab door lock controller from Remote Keyless Entry or or other external device to lock or unlock doors.
This parameter is different from Cab Doors Lock Actuation Command (SPN xxxx) because this is a request to actuate door locks ...";

CM_ SG_ 2499547902 DoorsLockActCmd "Commands cab door latch state change: lock or unlock.
000 = Unlock left front cab door latch (driver door on LH steer vehicles)
001 = Unlock right front cab door latch (front passenger door for LH steer vehicles)
010 = Unlock left rear cab door ...";

CM_ BO_ 2583173374 "Wiper faults detected by the Wiper Controller.";

CM_ SG_ 2583173374 WiperSilenceFault "Indicates if Wiper Driver feedback is not on CAN network.";

CM_ SG_ 2583173374 WiperHomePosFault "Indicates if Wiper failed ''home position''.";

CM_ SG_ 2583173374 WiperControlFault "Indicates if Wiper failed to execute command from the Wiper Controller.";

CM_ BO_ 2583177470 "Rain data from the Rain Sensor Driver.";

CM_ SG_ 2583177470 RainIntensity "Rain intensity logical interpretation.";

CM_ BO_ 2583175166 "Message with wiper status";

CM_ SG_ 2583175166 WipeArbRequest "Represent selected wiper status for HMI";

CM_ BO_ 2565865982 "Electronic Brake Controller 1
Used for brake control information";

CM_ SG_ 2565865982 TrctrMntdTrailerABSWarningSignal "This parameter commands the tractor-mounted trailer ABS optical warning signal.

00 Off
01 On 
10 Reserved
11 Take no action";

CM_ SG_ 2565865982 TrailerABSStatus "State signal which indicates that ABS in the trailer is actively controlling the brakes.  A message is sent to the tractor from the trailer (i.e. by PLC). The receiving device in the tractor transfers this information to the J1939 network.  At the ...";

CM_ SG_ 2565865982 HaltBrakeSwitch "Switch signal which indicates the position of the halt brake switch.

00    Halt brake switch passive
01    Halt brake switch active
10    Error
11    Not available";

CM_ SG_ 2565865982 SrcAddrssOfCntrllngDvcFrBrkeCtrl "The source address of the SAE J1939 device currently controlling the brake system. Its value may be the source address of the ECU transmitting the message (which means that no external SAE J1939 message is providing the active command) or the source ...";

CM_ SG_ 2565865982 ATC_ASRInformationSignal "This parameter commands the ATC/ASR driver information signal, for example a dash lamp.

00 Off
01 On 
10 Reserved
11 Take no action";

CM_ SG_ 2565865982 ABS_EBSAmberWarningSignal "This parameter commands the ABS/EBS amber/yellow optical warning signal

00 Off
01 On
10 Reserved
11 Take no action";

CM_ SG_ 2565865982 EBSRedWarningSignal "This parameter commands the EBS red optical warning signal

00 Off
01 On
10 Reserved
11 Take no action";

CM_ SG_ 2565865982 ABSFullyOperational "Signal which indicates whether an ABS system is fully operational or whether its functionality is reduced by a defect or by an intended action (e.g., by activation of an ABS-off-road switch or during special diagnostic procedures).  There are cases ...";

CM_ SG_ 2565865982 EngRetarderSelection "The position of the operator controlled selector, expressed as a percentage and determined by the ratio of the current position of the selector to its maximum possible position. Zero percent means no braking torque is requested by the operator from ...";

CM_ SG_ 2565865982 RemoteAccelEnableSwitch "Switch signal which indicates that the remote accelerator has been enabled and controls the engine.
00 - Off
01 - On
10 - Error
11 - Not available
NOTE-The accelerator interlock switch (see SPN 972) must be disabled in order for the remote ...";

CM_ SG_ 2565865982 EngAuxShutdownSwitch "Switch signal which requests that all engine fueling stop.

00 - Off
01 - On
10 - Error
11 - Not available";

CM_ SG_ 2565865982 EngDerateSwitch "Switch signal used to activate the torque limiting feature of the engine.  The specific nature of torque limiting should be verified with the manufacturer.

00 - Off
01 - On
10 - Error
11 - Not available";

CM_ SG_ 2565865982 AccelInterlockSwitch "Switch signal used to disable the accelerator and remote accelerator inputs, causing the engine to return to idle.

00 - Off
01 - On
10 - Error
11 - Not available";

CM_ SG_ 2565865982 TractionCtrlOverrideSwitch "Switch signal which indicates the position of the traction control override switch.  The traction control override signal disables the automatic traction control function allowing the wheels to spin.
00 - Off
01 - On
10 - Error
11 - Not ...";

CM_ SG_ 2565865982 ASRHillHolderSwitch "Switch signal which indicates the position of the ASR 'hill holder' switch.

00 - ASR 'hill holder' switch passive
01 - ASR 'hill holder' switch active
10 - Error
11 - Not available";

CM_ SG_ 2565865982 ASROffroadSwitch "Switch signal which indicates the position of the ASR off-road switch.

00 - ASR off-road switch passive
01 - ASR off-road switch active
10 - Error
11 - Not available";

CM_ SG_ 2565865982 ABSOffroadSwitch "Switch signal which indicates the position of the ABS off-road switch.

00 - ABS off-road switch passive
01 - ABS off-road switch active
10 - Error
11 - Not available";

CM_ SG_ 2565865982 BrakePedalPos "Ratio of brake pedal position to maximum pedal position.  Used for electric brake applications. 0% means no braking. Also when there are two brake pedals on the machine (Left Brake Pedal Position SPN 3033 and Right Brake Pedal Position SPN 3032) the ...";

CM_ SG_ 2565865982 EBSBrakeSwitch "Switch signal which indicates that the brake pedal is being pressed.  The EBS brake switch is independent of the brake light switch and has no provisions for external connections.
00 - Brake pedal is not being pressed
01 - Brake pedal is being ...";

CM_ SG_ 2565865982 AntiLockBrakingActive "State signal which indicates that the ABS is active.  The signal is set active when wheel brake pressure actually starts to be modulated by ABS and is reset to passive when all wheels are in a stable condition for a certain time.  The signal can ...";

CM_ SG_ 2565865982 ASRBrakeCtrlActive "State signal which indicates that ASR brake control is active. Active means that ASR actually controls wheel brake pressure at one or more wheels of the driven axle(s).
00 - ASR brake control passive but installed
01 - ASR brake control active
10 ...";

CM_ SG_ 2565865982 ASREngCtrlActive "State signal which indicates that ASR engine control has been commanded to be active. Active means that ASR actually tries to control the engine. This state signal is independent of other control commands to the engine (e.g., from the transmission) ...";

CM_ BO_ 2583176190 "Message with information from seatbelts and seatmats monitor";

CM_ SG_ 2583176190 SigSeatSt "Center passenger seatmat state";

CM_ BO_ 2515942654 "Cabin Climate Temperature State";

CM_ BO_ 2566845950 "Ambient Conditions";

CM_ SG_ 2566845950 RoadSurfaceTemp "Indicated temperature of road surface over which vehicle is operating.";

CM_ SG_ 2566845950 EngAirIntakeTemp "Temperature of air entering vehicle air induction system.";

CM_ SG_ 2566845950 AmbientAirTemp "Temperature of air surrounding vehicle.";

CM_ SG_ 2566845950 CabInteriorTemp "Temperature of air inside the part of the vehicle that encloses the driver and vehicle operating controls.

Note: See also SPN 1691.  SPN 1662 is an additional diagnostic SPN associated with cab temperature.";

CM_ SG_ 2566845950 BarometricPress "Absolute air pressure of the atmosphere.";

CM_ BO_ 2515942142 "Cabin Climate Temperature State";

CM_ SG_ 513 SensorFSL_Echo1Height "Detected 1st echo: Height classification result for the reflection (low/high/unknown)";

CM_ SG_ 513 SensorFSL_Echo2Dist "Detected 2nd echo: Current distance of the track. U16_Max will be output in case no distance is measured";

CM_ SG_ 513 SensorFSL_Echo1Dist "Detected 1st echo: Current distance of the track. U16_Max will be output in case no distance is measured";

CM_ SG_ 513 SensorFSL_Echo1NumDetn "Detected 1st echo: Number of detections for the current track. This information shows the quality level of the distance ";

CM_ SG_ 513 SensorFSL_BlindDist "For each signalway the blind distance is provided";

CM_ SG_ 513 SensorFSL_SignalWayId "Signal Way ID";

CM_ SG_ 545 SensorRSL_Echo1Height "Detected 1st echo: Height classification result for the reflection (low/high/unknown)";

CM_ SG_ 545 SensorRSL_Echo2Dist "Detected 2nd echo: Current distance of the track. U16_Max will be output in case no distance is measured";

CM_ SG_ 545 SensorRSL_Echo1Dist "Detected 1st echo: Current distance of the track. U16_Max will be output in case no distance is measured";

CM_ SG_ 545 SensorRSL_Echo1NumDetn "Detected 1st echo: Number of detections for the current track. This information shows the quality level of the distance ";

CM_ SG_ 545 SensorRSL_BlindDist "For each signalway the blind distance is provided";

CM_ SG_ 545 SensorRSL_SignalWayId "Signal Way ID";

CM_ SG_ 533 SensorFSR_Echo1Height "Detected 1st echo: Height classification result for the reflection (low/high/unknown)";

CM_ SG_ 533 SensorFSR_Echo2Dist "Detected 2nd echo: Current distance of the track. U16_Max will be output in case no distance is measured";

CM_ SG_ 533 SensorFSR_Echo1Dist "Detected 1st echo: Current distance of the track. U16_Max will be output in case no distance is measured";

CM_ SG_ 533 SensorFSR_Echo1NumDetn "Detected 1st echo: Number of detections for the current track. This information shows the quality level of the distance ";

CM_ SG_ 533 SensorFSR_BlindDist "For each signalway the blind distance is provided";

CM_ SG_ 533 SensorFSR_SignalWayId "Signal Way ID";

CM_ SG_ 565 SensorRSR_Echo1Height "Detected 1st echo: Height classification result for the reflection (low/high/unknown)";

CM_ SG_ 565 SensorRSR_Echo2Dist "Detected 2nd echo: Current distance of the track. U16_Max will be output in case no distance is measured";

CM_ SG_ 565 SensorRSR_Echo1Dist "Detected 1st echo: Current distance of the track. U16_Max will be output in case no distance is measured";

CM_ SG_ 565 SensorRSR_Echo1NumDetn "Detected 1st echo: Number of detections for the current track. This information shows the quality level of the distance ";

CM_ SG_ 565 SensorRSR_BlindDist "For each signalway the blind distance is provided";

CM_ SG_ 565 SensorRSR_SignalWayId "Signal Way ID";

CM_ SG_ 517 SensorFOL_Echo1Height "Detected 1st echo: Height classification result for the reflection (low/high/unknown)";

CM_ SG_ 517 SensorFOL_Echo2Dist "Detected 2nd echo: Current distance of the track. U16_Max will be output in case no distance is measured";

CM_ SG_ 517 SensorFOL_Echo1Dist "Detected 1st echo: Current distance of the track. U16_Max will be output in case no distance is measured";

CM_ SG_ 517 SensorFOL_Echo1NumDetn "Detected 1st echo: Number of detections for the current track. This information shows the quality level of the distance ";

CM_ SG_ 517 SensorFOL_BlindDist "For each signalway the blind distance is provided";

CM_ SG_ 517 SensorFOL_SignalWayId "Signal Way ID";

CM_ SG_ 549 SensorROL_Echo1Height "Detected 1st echo: Height classification result for the reflection (low/high/unknown)";

CM_ SG_ 549 SensorROL_Echo2Dist "Detected 2nd echo: Current distance of the track. U16_Max will be output in case no distance is measured";

CM_ SG_ 549 SensorROL_Echo1Dist "Detected 1st echo: Current distance of the track. U16_Max will be output in case no distance is measured";

CM_ SG_ 549 SensorROL_Echo1NumDetn "Detected 1st echo: Number of detections for the current track. This information shows the quality level of the distance ";

CM_ SG_ 549 SensorROL_BlindDist "For each signalway the blind distance is provided";

CM_ SG_ 549 SensorROL_SignalWayId "Signal Way ID";

CM_ SG_ 521 SensorFIL_Echo1Height "Detected 1st echo: Height classification result for the reflection (low/high/unknown)";

CM_ SG_ 521 SensorFIL_Echo2Dist "Detected 2nd echo: Current distance of the track. U16_Max will be output in case no distance is measured";

CM_ SG_ 521 SensorFIL_Echo1Dist "Detected 1st echo: Current distance of the track. U16_Max will be output in case no distance is measured";

CM_ SG_ 521 SensorFIL_Echo1NumDetn "Detected 1st echo: Number of detections for the current track. This information shows the quality level of the distance ";

CM_ SG_ 521 SensorFIL_BlindDist "For each signalway the blind distance is provided";

CM_ SG_ 521 SensorFIL_SignalWayId "Signal Way ID";

CM_ SG_ 553 SensorRIL_Echo1Height "Detected 1st echo: Height classification result for the reflection (low/high/unknown)";

CM_ SG_ 553 SensorRIL_Echo2Dist "Detected 2nd echo: Current distance of the track. U16_Max will be output in case no distance is measured";

CM_ SG_ 553 SensorRIL_Echo1Dist "Detected 1st echo: Current distance of the track. U16_Max will be output in case no distance is measured";

CM_ SG_ 553 SensorRIL_Echo1NumDetn "Detected 1st echo: Number of detections for the current track. This information shows the quality level of the distance ";

CM_ SG_ 553 SensorRIL_BlindDist "For each signalway the blind distance is provided";

CM_ SG_ 553 SensorRIL_SignalWayId "Signal Way ID";

CM_ SG_ 525 SensorFIR_Echo1Height "Detected 1st echo: Height classification result for the reflection (low/high/unknown)";

CM_ SG_ 525 SensorFIR_Echo2Dist "Detected 2nd echo: Current distance of the track. U16_Max will be output in case no distance is measured";

CM_ SG_ 525 SensorFIR_Echo1Dist "Detected 1st echo: Current distance of the track. U16_Max will be output in case no distance is measured";

CM_ SG_ 525 SensorFIR_Echo1NumDetn "Detected 1st echo: Number of detections for the current track. This information shows the quality level of the distance ";

CM_ SG_ 525 SensorFIR_BlindDist "For each signalway the blind distance is provided";

CM_ SG_ 525 SensorFIR_SignalWayId "Signal Way ID";

CM_ SG_ 557 SensorRIR_Echo1Height "Detected 1st echo: Height classification result for the reflection (low/high/unknown)";

CM_ SG_ 557 SensorRIR_Echo2Dist "Detected 2nd echo: Current distance of the track. U16_Max will be output in case no distance is measured";

CM_ SG_ 557 SensorRIR_Echo1Dist "Detected 1st echo: Current distance of the track. U16_Max will be output in case no distance is measured";

CM_ SG_ 557 SensorRIR_Echo1NumDetn "Detected 1st echo: Number of detections for the current track. This information shows the quality level of the distance ";

CM_ SG_ 557 SensorRIR_BlindDist "For each signalway the blind distance is provided";

CM_ SG_ 557 SensorRIR_SignalWayId "Signal Way ID";

CM_ SG_ 529 SensorFOR_Echo1Height "Detected 1st echo: Height classification result for the reflection (low/high/unknown)";

CM_ SG_ 529 SensorFOR_Echo2Dist "Detected 2nd echo: Current distance of the track. U16_Max will be output in case no distance is measured";

CM_ SG_ 529 SensorFOR_Echo1Dist "Detected 1st echo: Current distance of the track. U16_Max will be output in case no distance is measured";

CM_ SG_ 529 SensorFOR_Echo1NumDetn "Detected 1st echo: Number of detections for the current track. This information shows the quality level of the distance ";

CM_ SG_ 529 SensorFOR_BlindDist "For each signalway the blind distance is provided";

CM_ SG_ 529 SensorFOR_SignalWayId "Signal Way ID";

CM_ SG_ 561 SensorROR_Echo1Height "Detected 1st echo: Height classification result for the reflection (low/high/unknown)";

CM_ SG_ 561 SensorROR_Echo2Dist "Detected 2nd echo: Current distance of the track. U16_Max will be output in case no distance is measured";

CM_ SG_ 561 SensorROR_Echo1Dist "Detected 1st echo: Current distance of the track. U16_Max will be output in case no distance is measured";

CM_ SG_ 561 SensorROR_Echo1NumDetn "Detected 1st echo: Number of detections for the current track. This information shows the quality level of the distance ";

CM_ SG_ 561 SensorROR_BlindDist "For each signalway the blind distance is provided";

CM_ SG_ 561 SensorROR_SignalWayId "Signal Way ID";

CM_ BO_ 2566803454 "Vehicle Dynamic Stability Control 1
Contains information which relates to the VDC system status.";

CM_ SG_ 2566803454 TrailerVDCActive "The trailer-VDC (Vehicle Dynamic Control) is an electronic vehicle stability function within the (semi) trailer braking system. It acts to stabilize the (semi) trailer during dynamic maneuvers. VDC includes Roll Over Prevention (ROP) and/or Yaw ...";

CM_ SG_ 2566803454 YCBrakeCtrlActive "State signal which indicates that Yaw Control (YC) has activated brake control. Active means that YC actually controls wheel brake pressure at one or more wheels of the vehicle or vehicle combination. Within the physical limits, YC attempts to ...";

CM_ SG_ 2566803454 YCEngCtrlActive "State Signal which indicates that the Yaw Control (YC) has commanded engine control to be active. Within the physical limits, YC attempts to prevent yawing of the vehicle. Active means that YC actually tries to control the engine. This state signal ...";

CM_ SG_ 2566803454 ROPBrakeCtrlActive "State signal which indicates that Roll over Prevention (ROP) has activated brake control. Active means that ROP actually controls wheel brake pressure at one or more wheels of the vehicle or vehicle combination. Within the physical limits, ROP ...";

CM_ SG_ 2566803454 ROPEngCtrlActive "State Signal which indicates that the Roll Over Prevention (ROP) has commanded engine control to be active. Within the physical limits, ROP attempts to prevent rolling over of the vehicle. Active means that ROP actually tries to control the engine ...";

CM_ SG_ 2566803454 VDCBrakeLightRq "Indicates whether VDC requests to turn the vehicle brake lights on

00 Turn brake light not on
01 Turn brake light on
10 Reserved
11 Don't care/Take no action";

CM_ SG_ 2566803454 VDCFullyOperational "Signal that indicates whether VDC is fully operational or whether its functionality is reduced by a permanent or temporary (e.g. low voltage) defect, by intended action (e.g. disabled by a switch or during special diagnostic procedures), not ...";

CM_ SG_ 2566803454 VDCInformationSignal "This parameter commands the VDC information signal, for example a dash lamp.

00 Off
01 On
10 Reserved
11 Don't care/Take no action";

BA_DEF_ SG_  "SigType" ENUM  "Default","Range","RangeSigned","ASCII","Discrete","Control","ReferencePGN","DTC","StringDelimiter","StringLength","StringLengthControl","MessageCounter","MessageChecksum";

BA_DEF_ SG_  "GenSigEVName" STRING ;

BA_DEF_ SG_  "GenSigILSupport" ENUM  "No","Yes";

BA_DEF_ SG_  "GenSigSendType" ENUM  "Cyclic","OnWrite","OnWriteWithRepetition","OnChange","OnChangeWithRepetition","IfActive","IfActiveWithRepetition","NoSigSendType";

BA_DEF_ SG_  "GenSigStartValue" INT 0 2147483647;

BA_DEF_ BO_  "GenMsgDelayTime" INT 0 1000;

BA_DEF_ BO_  "GenMsgILSupport" ENUM  "No","Yes";

BA_DEF_ BO_  "GenMsgStartDelayTime" INT 0 100000;

BA_DEF_ BU_  "NmStationAddress" INT 0 255;

BA_DEF_ BO_  "GenMsgSendType" ENUM  "cyclic","NotUsed","IfActive","NotUsed","NotUsed","NotUsed","NotUsed","NotUsed","noMsgSendType";

BA_DEF_ BO_  "GenMsgRequestable" INT 0 1;

BA_DEF_ BO_  "GenMsgCycleTime" INT 0 3600000;

BA_DEF_ SG_  "SPN" INT 0 524287;

BA_DEF_  "DBName" STRING ;

BA_DEF_  "BusType" STRING ;

BA_DEF_  "ProtocolType" STRING ;

BA_DEF_ BO_  "VFrameFormat" ENUM  "StandardCAN","ExtendedCAN","reserved","J1939PG";

BA_DEF_DEF_  "SigType" "Default";

BA_DEF_DEF_  "GenSigEVName" "Env@Nodename_@Signame";

BA_DEF_DEF_  "GenSigILSupport" "Yes";

BA_DEF_DEF_  "GenSigSendType" "NoSigSendType";

BA_DEF_DEF_  "GenSigStartValue" 0;

BA_DEF_DEF_  "GenMsgDelayTime" 0;

BA_DEF_DEF_  "GenMsgILSupport" "Yes";

BA_DEF_DEF_  "GenMsgStartDelayTime" 0;

BA_DEF_DEF_  "NmStationAddress" 254;

BA_DEF_DEF_  "GenMsgSendType" "noMsgSendType";

BA_DEF_DEF_  "GenMsgRequestable" 1;

BA_DEF_DEF_  "GenMsgCycleTime" 0;

BA_DEF_DEF_  "SPN" 0;

BA_DEF_DEF_  "DBName" "";

BA_DEF_DEF_  "BusType" "CAN";

BA_DEF_DEF_  "ProtocolType" "J1939";

BA_DEF_DEF_  "VFrameFormat" "J1939PG";

BA_ "DBName" "HGCS";

BA_ "GenMsgCycleTime" BO_ 2180423678 100;

BA_ "GenMsgSendType" BO_ 2180423678 0;

BA_ "GenSigStartValue" SG_ 2180423678 rllrShttrLckActtRq 3;

BA_ "GenMsgDelayTime" BO_ 2381750526 1000;

BA_ "GenMsgSendType" BO_ 2381750526 0;

BA_ "GenMsgCycleTime" BO_ 2381750526 1000;

BA_ "SendOnChange" BO_ 2381750526 1;

BA_ "SendOnChange" BO_ 2381750782 1;

BA_ "GenMsgCycleTime" BO_ 2381750782 1000;

BA_ "GenMsgSendType" BO_ 2381750782 0;

BA_ "SendOnChange" BO_ 2381751038 1;

BA_ "GenMsgCycleTime" BO_ 2381751038 1000;

BA_ "GenMsgSendType" BO_ 2381751038 0;

BA_ "SendOnChange" BO_ 2381751294 1;

BA_ "GenMsgCycleTime" BO_ 2381751294 1000;

BA_ "GenMsgSendType" BO_ 2381751294 0;

BA_ "SendOnChange" BO_ 2381751550 1;

BA_ "GenMsgCycleTime" BO_ 2381751550 1000;

BA_ "GenMsgSendType" BO_ 2381751550 0;

BA_ "GenMsgCycleTime" BO_ 2583078398 100;

BA_ "GenMsgSendType" BO_ 2583078398 0;

BA_ "GenMsgCycleTime" BO_ 2583078654 100;

BA_ "GenMsgSendType" BO_ 2583078654 0;

BA_ "GenMsgCycleTime" BO_ 2583078910 100;

BA_ "GenMsgCycleTime" BO_ 2583079166 100;

BA_ "GenMsgSendType" BO_ 2583079166 0;

BA_ "SendOnChange" BO_ 2583079166 1;

BA_ "GenMsgCycleTime" BO_ 2583210494 200;

BA_ "SendOnChange" BO_ 2583210494 1;

BA_ "GenMsgSendType" BO_ 2583210494 0;

BA_ "GenMsgSendType" BO_ 2583210750 0;

BA_ "GenMsgCycleTime" BO_ 2583210750 1000;

BA_ "GenSigStartValue" SG_ 2583210750 Glss2HtrStt 3;

BA_ "GenMsgSendType" BO_ 2583211006 0;

BA_ "GenMsgCycleTime" BO_ 2583211006 1000;

BA_ "GenSigStartValue" SG_ 2583211006 Glss3HtrStt 3;

BA_ "SendOnChange" BO_ 2365443838 1;

BA_ "GenMsgCycleTime" BO_ 2365443838 1000;

BA_ "GenMsgSendType" BO_ 2365443838 0;

BA_ "GenMsgDelayTime" BO_ 2365443838 1000;

BA_ "GenMsgSendType" BO_ 2565868030 0;

BA_ "GenMsgCycleTime" BO_ 2565868030 10;

BA_ "SigType" SG_ 2565868030 LongitudinalAcceleration 1;

BA_ "SPN" SG_ 2565868030 LongitudinalAcceleration 1810;

BA_ "SigType" SG_ 2565868030 LateralAcceleration 1;

BA_ "SPN" SG_ 2565868030 LateralAcceleration 1809;

BA_ "SigType" SG_ 2565868030 YawRate 1;

BA_ "SPN" SG_ 2565868030 YawRate 1808;

BA_ "SigType" SG_ 2565868030 SteerWheelAngleSensorType 5;

BA_ "SPN" SG_ 2565868030 SteerWheelAngleSensorType 1812;

BA_ "GenSigStartValue" SG_ 2565868030 SteerWheelTurnCounter 22;

BA_ "SPN" SG_ 2565868030 SteerWheelTurnCounter 1811;

BA_ "SigType" SG_ 2565868030 SteerWheelAngle 1;

BA_ "SPN" SG_ 2565868030 SteerWheelAngle 1807;

BA_ "GenMsgSendType" BO_ 2566767870 0;

BA_ "GenMsgCycleTime" BO_ 2566767870 100;

BA_ "SigType" SG_ 2566767870 EmergencyBrakingActive 5;

BA_ "SPN" SG_ 2566767870 EmergencyBrakingActive 5847;

BA_ "SigType" SG_ 2566767870 PrkngBrakeActuatorFullyActivated 4;

BA_ "SPN" SG_ 2566767870 PrkngBrakeActuatorFullyActivated 5275;

BA_ "SigType" SG_ 2566767870 XBRAccelerationLimit 1;

BA_ "GenSigStartValue" SG_ 2566767870 XBRAccelerationLimit 25;

BA_ "SPN" SG_ 2566767870 XBRAccelerationLimit 2921;

BA_ "SPN" SG_ 2566767870 XBRActiveCtrlMode 2918;

BA_ "SigType" SG_ 2566767870 XBRSystemState 5;

BA_ "SPN" SG_ 2566767870 XBRSystemState 2917;

BA_ "SigType" SG_ 2566767870 FoundationBrakeUse 5;

BA_ "SPN" SG_ 2566767870 FoundationBrakeUse 2919;

BA_ "SPN" SG_ 2566767870 HillHolderMode 2912;

BA_ "SPN" SG_ 2566767870 HaltBrakeMode 2913;

BA_ "SigType" SG_ 2566767870 BrakeTempWarning 5;

BA_ "SPN" SG_ 2566767870 BrakeTempWarning 3839;

BA_ "GenMsgSendType" BO_ 2365484286 0;

BA_ "GenMsgCycleTime" BO_ 2365484286 50;

BA_ "SigType" SG_ 2365484286 TachographVehicleSpeed 1;

BA_ "SPN" SG_ 2365484286 TachographVehicleSpeed 1624;

BA_ "SigType" SG_ 2365484286 TachographOutputShaftSpeed 1;

BA_ "SPN" SG_ 2365484286 TachographOutputShaftSpeed 1623;

BA_ "SigType" SG_ 2365484286 DirectionIndicator 4;

BA_ "SPN" SG_ 2365484286 DirectionIndicator 1619;

BA_ "SigType" SG_ 2365484286 TachographPerformance 5;

BA_ "SPN" SG_ 2365484286 TachographPerformance 1620;

BA_ "SigType" SG_ 2365484286 HandlingInformation 5;

BA_ "SPN" SG_ 2365484286 HandlingInformation 1621;

BA_ "SigType" SG_ 2365484286 SystemEvent 5;

BA_ "SPN" SG_ 2365484286 SystemEvent 1622;

BA_ "SigType" SG_ 2365484286 DriverCardDriver2 4;

BA_ "SPN" SG_ 2365484286 DriverCardDriver2 1616;

BA_ "SPN" SG_ 2365484286 Driver2TimeRelatedStates 1618;

BA_ "SigType" SG_ 2365484286 VehicleOverspeed 4;

BA_ "SPN" SG_ 2365484286 VehicleOverspeed 1614;

BA_ "SigType" SG_ 2365484286 DriverCardDriver1 4;

BA_ "SPN" SG_ 2365484286 DriverCardDriver1 1615;

BA_ "SPN" SG_ 2365484286 Driver1TimeRelatedStates 1617;

BA_ "SigType" SG_ 2365484286 VehicleMotion 4;

BA_ "SPN" SG_ 2365484286 VehicleMotion 1611;

BA_ "SPN" SG_ 2365484286 Driver2WorkingState 1613;

BA_ "SPN" SG_ 2365484286 Driver1WorkingState 1612;

BA_ "SendOnChange" BO_ 2582766846 1;

BA_ "GenMsgCycleTime" BO_ 2582766846 1000;

BA_ "GenMsgSendType" BO_ 2582766846 0;

BA_ "GenSigStartValue" SG_ 2582766846 ACU_Active 3;

BA_ "GenSigStartValue" SG_ 2582766846 ACU_Alarm 3;

BA_ "GenSigStartValue" SG_ 2582766846 USS_Status 3;

BA_ "GenSigStartValue" SG_ 2582766846 ACU_Status 3;

BA_ "GenSigStartValue" SG_ 2582766846 Intrusion_detected 3;

BA_ "GenMsgCycleTime" BO_ 2382314494 40;

BA_ "GenMsgSendType" BO_ 2382314494 0;

BA_ "SigType" SG_ 2382314494 GS_CRC 12;

BA_ "SigType" SG_ 2382314494 GS_MC 11;

BA_ "GenSigStartValue" SG_ 2382314494 GS_Demand 3;

BA_ "SendOnChange" BO_ 2365473278 1;

BA_ "GenMsgDelayTime" BO_ 2365473278 100;

BA_ "GenMsgSendType" BO_ 2365473278 0;

BA_ "GenMsgCycleTime" BO_ 2365473278 1000;

BA_ "SigType" SG_ 2365473278 ImplementRearWorkLightCmd 5;

BA_ "SPN" SG_ 2365473278 ImplementRearWorkLightCmd 2405;

BA_ "SigType" SG_ 2365473278 ImplLeftFacingWorkLightCmd 5;

BA_ "SPN" SG_ 2365473278 ImplLeftFacingWorkLightCmd 2399;

BA_ "SigType" SG_ 2365473278 ImplRightFwdWorkLightCmd 5;

BA_ "SPN" SG_ 2365473278 ImplRightFwdWorkLightCmd 2401;

BA_ "SigType" SG_ 2365473278 LightingDataRqCmd 5;

BA_ "SPN" SG_ 2365473278 LightingDataRqCmd 2393;

BA_ "SigType" SG_ 2365473278 ImplLeftForwardWorkLightCmd 5;

BA_ "SPN" SG_ 2365473278 ImplLeftForwardWorkLightCmd 2597;

BA_ "SigType" SG_ 2365473278 ImplRightFacingWorkLightCmd 5;

BA_ "SPN" SG_ 2365473278 ImplRightFacingWorkLightCmd 2406;

BA_ "SigType" SG_ 2365473278 ImplOEMOption1LightCmd 5;

BA_ "SPN" SG_ 2365473278 ImplOEMOption1LightCmd 2395;

BA_ "SigType" SG_ 2365473278 ImplOEMOption2LightCmd 5;

BA_ "SPN" SG_ 2365473278 ImplOEMOption2LightCmd 2397;

BA_ "SigType" SG_ 2365473278 TrctrFrntHghMdWkLightsCmd 5;

BA_ "SPN" SG_ 2365473278 TrctrFrntHghMdWkLightsCmd 2355;

BA_ "SigType" SG_ 2365473278 TrctrFrntLowMdWkLightsCmd 5;

BA_ "SPN" SG_ 2365473278 TrctrFrntLowMdWkLightsCmd 2353;

BA_ "SigType" SG_ 2365473278 TrctrSdeHighMdWkLightsCmd 5;

BA_ "SPN" SG_ 2365473278 TrctrSdeHighMdWkLightsCmd 2365;

BA_ "SigType" SG_ 2365473278 TrctrSideLowMdWkLightsCmd 5;

BA_ "SPN" SG_ 2365473278 TrctrSideLowMdWkLightsCmd 2363;

BA_ "SigType" SG_ 2365473278 TrctrRarHighMdWkLightsCmd 5;

BA_ "SPN" SG_ 2365473278 TrctrRarHighMdWkLightsCmd 2361;

BA_ "SigType" SG_ 2365473278 TrctrRearLowMdWkLightsCmd 5;

BA_ "SPN" SG_ 2365473278 TrctrRearLowMdWkLightsCmd 2359;

BA_ "SigType" SG_ 2365473278 TrctrUndrsdeMdWkLightsCmd 5;

BA_ "SPN" SG_ 2365473278 TrctrUndrsdeMdWkLightsCmd 2357;

BA_ "SigType" SG_ 2365473278 RearFogLightsCmd 5;

BA_ "SPN" SG_ 2365473278 RearFogLightsCmd 2389;

BA_ "SigType" SG_ 2365473278 TractorMarkerLightCmd 5;

BA_ "SPN" SG_ 2365473278 TractorMarkerLightCmd 2377;

BA_ "SigType" SG_ 2365473278 ImplementMarkerLightCmd 5;

BA_ "SPN" SG_ 2365473278 ImplementMarkerLightCmd 2379;

BA_ "SigType" SG_ 2365473278 TractorClearanceLightCmd 5;

BA_ "SPN" SG_ 2365473278 TractorClearanceLightCmd 2381;

BA_ "SigType" SG_ 2365473278 ImplementClearanceLightCmd 5;

BA_ "SPN" SG_ 2365473278 ImplementClearanceLightCmd 2383;

BA_ "SigType" SG_ 2365473278 LeftStopLightCmd 5;

BA_ "SPN" SG_ 2365473278 LeftStopLightCmd 2371;

BA_ "SigType" SG_ 2365473278 RightStopLightCmd 5;

BA_ "SPN" SG_ 2365473278 RightStopLightCmd 2373;

BA_ "SigType" SG_ 2365473278 CenterStopLightCmd 5;

BA_ "SPN" SG_ 2365473278 CenterStopLightCmd 2375;

BA_ "SigType" SG_ 2365473278 BackUpLightAndAlarmHornCmd 5;

BA_ "SPN" SG_ 2365473278 BackUpLightAndAlarmHornCmd 2391;

BA_ "SigType" SG_ 2365473278 LeftTurnSignalLightsCmd 5;

BA_ "SPN" SG_ 2365473278 LeftTurnSignalLightsCmd 2367;

BA_ "SigType" SG_ 2365473278 RightTurnSignalLightsCmd 5;

BA_ "SPN" SG_ 2365473278 RightTurnSignalLightsCmd 2369;

BA_ "SigType" SG_ 2365473278 RotatingBeaconLightCmd 5;

BA_ "SPN" SG_ 2365473278 RotatingBeaconLightCmd 2385;

BA_ "SigType" SG_ 2365473278 TractorFrontFogLightsCmd 5;

BA_ "SPN" SG_ 2365473278 TractorFrontFogLightsCmd 2387;

BA_ "SigType" SG_ 2365473278 HighBeamHeadLightCmd 5;

BA_ "SPN" SG_ 2365473278 HighBeamHeadLightCmd 2347;

BA_ "SigType" SG_ 2365473278 LowBeamHeadLightCmd 5;

BA_ "SPN" SG_ 2365473278 LowBeamHeadLightCmd 2349;

BA_ "SigType" SG_ 2365473278 AltBeamHeadLightCmd 5;

BA_ "SPN" SG_ 2365473278 AltBeamHeadLightCmd 2351;

BA_ "SigType" SG_ 2365473278 RunningLightCmd 5;

BA_ "SPN" SG_ 2365473278 RunningLightCmd 2403;

BA_ "GenMsgCycleTime" BO_ 2399117310 100;

BA_ "GenMsgSendType" BO_ 2399117310 0;

BA_ "SigType" SG_ 2399117310 VSM_CRC 12;

BA_ "SigType" SG_ 2399117310 VSM_Cnt 11;

BA_ "GenSigStartValue" SG_ 2399117310 VSM_State 7;

BA_ "GenMsgCycleTime" BO_ 2566799614 100;

BA_ "SigType" SG_ 2566799614 ImplementRearWorkLight 4;

BA_ "SPN" SG_ 2566799614 ImplementRearWorkLight 2394;

BA_ "SigType" SG_ 2566799614 ImplLeftFacingWorkLight 4;

BA_ "SPN" SG_ 2566799614 ImplLeftFacingWorkLight 2400;

BA_ "SigType" SG_ 2566799614 ImplRightForwardWorkLight 4;

BA_ "SPN" SG_ 2566799614 ImplRightForwardWorkLight 2402;

BA_ "SigType" SG_ 2566799614 ImplLeftForwardWorkLight 4;

BA_ "SPN" SG_ 2566799614 ImplLeftForwardWorkLight 2598;

BA_ "SigType" SG_ 2566799614 ImplRightFacingWorkLight 4;

BA_ "SPN" SG_ 2566799614 ImplRightFacingWorkLight 2407;

BA_ "SigType" SG_ 2566799614 ImplementOEMOption1Light 4;

BA_ "SPN" SG_ 2566799614 ImplementOEMOption1Light 2396;

BA_ "SigType" SG_ 2566799614 ImplementOEMOption2Light 4;

BA_ "SPN" SG_ 2566799614 ImplementOEMOption2Light 2398;

BA_ "SigType" SG_ 2566799614 TrctorFrontHighMdWkLights 4;

BA_ "SPN" SG_ 2566799614 TrctorFrontHighMdWkLights 2356;

BA_ "SigType" SG_ 2566799614 TractorFrontLowMdWkLights 4;

BA_ "SPN" SG_ 2566799614 TractorFrontLowMdWkLights 2354;

BA_ "SigType" SG_ 2566799614 TractorSideHighMdWkLights 4;

BA_ "SPN" SG_ 2566799614 TractorSideHighMdWkLights 2366;

BA_ "SigType" SG_ 2566799614 TractorSideLowMdWkLights 4;

BA_ "SPN" SG_ 2566799614 TractorSideLowMdWkLights 2364;

BA_ "SigType" SG_ 2566799614 TractorRearHighMdWkLights 4;

BA_ "SPN" SG_ 2566799614 TractorRearHighMdWkLights 2362;

BA_ "SigType" SG_ 2566799614 TractorRearLowMdWkLights 4;

BA_ "SPN" SG_ 2566799614 TractorRearLowMdWkLights 2360;

BA_ "SigType" SG_ 2566799614 TrctorUndersideMdWkLights 4;

BA_ "SPN" SG_ 2566799614 TrctorUndersideMdWkLights 2358;

BA_ "SigType" SG_ 2566799614 RearFogLights 4;

BA_ "SPN" SG_ 2566799614 RearFogLights 2390;

BA_ "SigType" SG_ 2566799614 TractorMarkerLight 4;

BA_ "SPN" SG_ 2566799614 TractorMarkerLight 2378;

BA_ "SigType" SG_ 2566799614 ImplementMarkerLight 4;

BA_ "SPN" SG_ 2566799614 ImplementMarkerLight 2380;

BA_ "SigType" SG_ 2566799614 TractorClearanceLight 4;

BA_ "SPN" SG_ 2566799614 TractorClearanceLight 2382;

BA_ "SigType" SG_ 2566799614 ImplementClearanceLight 4;

BA_ "SPN" SG_ 2566799614 ImplementClearanceLight 2384;

BA_ "SigType" SG_ 2566799614 LeftStopLight 4;

BA_ "SPN" SG_ 2566799614 LeftStopLight 2372;

BA_ "SigType" SG_ 2566799614 RightStopLight 4;

BA_ "SPN" SG_ 2566799614 RightStopLight 2374;

BA_ "SigType" SG_ 2566799614 CenterStopLight 4;

BA_ "SPN" SG_ 2566799614 CenterStopLight 2376;

BA_ "SigType" SG_ 2566799614 BackUpLightAndAlarmHorn 4;

BA_ "SPN" SG_ 2566799614 BackUpLightAndAlarmHorn 2392;

BA_ "SigType" SG_ 2566799614 LeftTurnSignalLights 4;

BA_ "SPN" SG_ 2566799614 LeftTurnSignalLights 2368;

BA_ "SigType" SG_ 2566799614 RightTurnSignalLights 4;

BA_ "SPN" SG_ 2566799614 RightTurnSignalLights 2370;

BA_ "SigType" SG_ 2566799614 RotatingBeaconLight 4;

BA_ "SPN" SG_ 2566799614 RotatingBeaconLight 2386;

BA_ "SigType" SG_ 2566799614 TractorFrontFogLights 4;

BA_ "SPN" SG_ 2566799614 TractorFrontFogLights 2388;

BA_ "SigType" SG_ 2566799614 HighBeamHeadLight 4;

BA_ "SPN" SG_ 2566799614 HighBeamHeadLight 2348;

BA_ "SigType" SG_ 2566799614 LowBeamHeadLight 4;

BA_ "SPN" SG_ 2566799614 LowBeamHeadLight 2350;

BA_ "SigType" SG_ 2566799614 AltBeamHeadLight 4;

BA_ "SPN" SG_ 2566799614 AltBeamHeadLight 2352;

BA_ "SigType" SG_ 2566799614 RunningLight 4;

BA_ "SPN" SG_ 2566799614 RunningLight 2404;

BA_ "GenMsgCycleTime" BO_ 2381851134 1000;

BA_ "SendOnChange" BO_ 2381851134 1;

BA_ "GenMsgCycleTime" BO_ 2382241534 100;

BA_ "GenMsgSendType" BO_ 2382241534 0;

BA_ "GenMsgCycleTime" BO_ 2314625790 100;

BA_ "GenMsgSendType" BO_ 2314625790 0;

BA_ "GenSigStartValue" SG_ 2314625790 RotationAngle 30;

BA_ "GenMsgSendType" BO_ 2583062270 0;

BA_ "GenMsgCycleTime" BO_ 2583062270 100;

BA_ "GenMsgCycleTime" BO_ 2566882814 100;

BA_ "GenMsgSendType" BO_ 2566882814 0;

BA_ "SendOnChange" BO_ 2566882814 1;

BA_ "GenSigStartValue" SG_ 2566882814 KeyRange 7;

BA_ "GenSigStartValue" SG_ 2566882814 KeyCommand 7;

BA_ "SendOnChange" BO_ 2583062526 1;

BA_ "GenMsgCycleTime" BO_ 2583062526 1000;

BA_ "GenMsgSendType" BO_ 2583062526 0;

BA_ "GenSigStartValue" SG_ 2583062526 CentralLockRequest 7;

BA_ "GenMsgCycleTime" BO_ 2399123966 100;

BA_ "GenMsgSendType" BO_ 2399123966 0;

BA_ "SigType" SG_ 2399123966 VehSec_CRC 12;

BA_ "SigType" SG_ 2399123966 VehSec_CNT 11;

BA_ "SPN" SG_ 2399123966 KeyfobBatteryState 520006;

BA_ "SPN" SG_ 2399123966 SecurityWakeUpRequest 520005;

BA_ "GenSigStartValue" SG_ 2399123966 SecurityWakeUpRequest 3;

BA_ "SPN" SG_ 2399123966 SecurityReadyToSleep 520004;

BA_ "GenSigStartValue" SG_ 2399123966 SecurityReadyToSleep 3;

BA_ "SPN" SG_ 2399123966 VehicleLockState 520003;

BA_ "SPN" SG_ 2399123966 DriveSecurityState 520002;

BA_ "SendOnChange" BO_ 2583065854 1;

BA_ "GenMsgSendType" BO_ 2583065854 0;

BA_ "GenMsgCycleTime" BO_ 2583065854 1000;

BA_ "SendOnChange" BO_ 2163223550 1;

BA_ "GenMsgSendType" BO_ 2163223550 0;

BA_ "GenMsgCycleTime" BO_ 2163223550 100;

BA_ "SigType" SG_ 2163223550 CrashChecksum 12;

BA_ "SPN" SG_ 2163223550 CrashChecksum 4975;

BA_ "SigType" SG_ 2163223550 CrashCounter 11;

BA_ "SPN" SG_ 2163223550 CrashCounter 4974;

BA_ "SPN" SG_ 2163223550 CrashType 4973;

BA_ "GenMsgSendType" BO_ 2566847742 0;

BA_ "GenMsgCycleTime" BO_ 2566847742 1000;

BA_ "SigType" SG_ 2566847742 EngOilFilterDiffPress7471 1;

BA_ "SPN" SG_ 2566847742 EngOilFilterDiffPress7471 7471;

BA_ "SigType" SG_ 2566847742 FuelLevel2 1;

BA_ "SPN" SG_ 2566847742 FuelLevel2 38;

BA_ "SigType" SG_ 2566847742 CargoAmbientTemp 1;

BA_ "SPN" SG_ 2566847742 CargoAmbientTemp 169;

BA_ "SigType" SG_ 2566847742 EngOilFilterDiffPress 1;

BA_ "SPN" SG_ 2566847742 EngOilFilterDiffPress 99;

BA_ "SigType" SG_ 2566847742 EngFuelFilterDiffPress 1;

BA_ "SPN" SG_ 2566847742 EngFuelFilterDiffPress 95;

BA_ "SigType" SG_ 2566847742 FuelLevel1 1;

BA_ "SPN" SG_ 2566847742 FuelLevel1 96;

BA_ "SigType" SG_ 2566847742 WasherFluidLevel 1;

BA_ "SPN" SG_ 2566847742 WasherFluidLevel 80;

BA_ "GenMsgCycleTime" BO_ 2583173886 200;

BA_ "SendOnChange" BO_ 2583173886 1;

BA_ "GenMsgSendType" BO_ 2583173886 0;

BA_ "GenMsgSendType" BO_ 2516075518 0;

BA_ "GenMsgCycleTime" BO_ 2516075518 100;

BA_ "SigType" SG_ 2516075518 RideHeight_Value 4;

BA_ "GenMsgCycleTime" BO_ 2448847614 100;

BA_ "GenMsgSendType" BO_ 2448847614 0;

BA_ "GenSigStartValue" SG_ 2448847614 RotationAngleRR 30;

BA_ "GenSigStartValue" SG_ 2448847614 RotationAngleRL 30;

BA_ "GenSigStartValue" SG_ 2448847614 RotationAngleFR 30;

BA_ "GenSigStartValue" SG_ 2448847614 RotationAngleFL 30;

BA_ "GenMsgCycleTime" BO_ 2448847102 100;

BA_ "GenMsgSendType" BO_ 2448847102 0;

BA_ "GenMsgCycleTime" BO_ 2448847358 100;

BA_ "GenMsgSendType" BO_ 2448847358 0;

BA_ "GenSigStartValue" SG_ 2448847358 AngleY_out 30;

BA_ "GenSigStartValue" SG_ 2448847358 AngleX_out 30;

BA_ "GenMsgSendType" BO_ 2297441790 0;

BA_ "GenMsgCycleTime" BO_ 2297441790 10;

BA_ "SigType" SG_ 2297441790 SpprtVrblTrnsRpttnRtFrAcclrtnSns 5;

BA_ "SPN" SG_ 2297441790 SpprtVrblTrnsRpttnRtFrAcclrtnSns 5353;

BA_ "SigType" SG_ 2297441790 VrtclAcclrtnExRangeFigureOfMerit 5;

BA_ "SPN" SG_ 2297441790 VrtclAcclrtnExRangeFigureOfMerit 5352;

BA_ "SigType" SG_ 2297441790 LngtdnlAcclrtnExRngFigureOfMerit 5;

BA_ "SPN" SG_ 2297441790 LngtdnlAcclrtnExRngFigureOfMerit 5351;

BA_ "SigType" SG_ 2297441790 LtrlAcclrtonExRangeFigureOfMerit 5;

BA_ "SPN" SG_ 2297441790 LtrlAcclrtonExRangeFigureOfMerit 5350;

BA_ "SigType" SG_ 2297441790 VerticalAccelerationExRange 1;

BA_ "SPN" SG_ 2297441790 VerticalAccelerationExRange 5349;

BA_ "SigType" SG_ 2297441790 LongitudinalAccelerationExRange 1;

BA_ "SPN" SG_ 2297441790 LongitudinalAccelerationExRange 5348;

BA_ "SigType" SG_ 2297441790 LateralAccelerationExRange 1;

BA_ "SPN" SG_ 2297441790 LateralAccelerationExRange 5347;

BA_ "GenMsgSendType" BO_ 2583180030 0;

BA_ "GenMsgCycleTime" BO_ 2583180030 1000;

BA_ "GenSigStartValue" SG_ 2583180030 WindowHeatedGlassSt 3;

BA_ "GenSigStartValue" SG_ 2583180030 FrontDoorHeatedGlassSt 3;

BA_ "GenSigStartValue" SG_ 2583180030 RearHeatedWindscreenSt 3;

BA_ "GenSigStartValue" SG_ 2583180030 FrontHeatedWindscreenSt 3;

BA_ "GenMsgDelayTime" BO_ 2499547902 100;

BA_ "GenMsgSendType" BO_ 2499547902 0;

BA_ "GenMsgCycleTime" BO_ 2499547902 1000;

BA_ "SendOnChange" BO_ 2499547902 1;

BA_ "SigType" SG_ 2499547902 MirrorRight2HeatCmd 5;

BA_ "SPN" SG_ 2499547902 MirrorRight2HeatCmd 7744;

BA_ "SigType" SG_ 2499547902 MirrorLeft2HeatCmd 5;

BA_ "SPN" SG_ 2499547902 MirrorLeft2HeatCmd 7743;

BA_ "SigType" SG_ 2499547902 MirrorRight1HeatCmd 5;

BA_ "SPN" SG_ 2499547902 MirrorRight1HeatCmd 7742;

BA_ "SigType" SG_ 2499547902 MirrorLeft1HeatCmd 5;

BA_ "SPN" SG_ 2499547902 MirrorLeft1HeatCmd 7741;

BA_ "SigType" SG_ 2499547902 MirrorRight2VerticalCmd 5;

BA_ "SPN" SG_ 2499547902 MirrorRight2VerticalCmd 7740;

BA_ "SigType" SG_ 2499547902 MirrorRight2HorizontalCmd 5;

BA_ "SPN" SG_ 2499547902 MirrorRight2HorizontalCmd 7739;

BA_ "SigType" SG_ 2499547902 MirrorLeft2VerticalCmd 5;

BA_ "SPN" SG_ 2499547902 MirrorLeft2VerticalCmd 7738;

BA_ "SigType" SG_ 2499547902 MirrorLeft2HorizontalCmd 5;

BA_ "SPN" SG_ 2499547902 MirrorLeft2HorizontalCmd 7737;

BA_ "SigType" SG_ 2499547902 MirrorRight1VerticalCmd 5;

BA_ "SPN" SG_ 2499547902 MirrorRight1VerticalCmd 7736;

BA_ "SigType" SG_ 2499547902 MirrorRight1HorizontalCmd 5;

BA_ "SPN" SG_ 2499547902 MirrorRight1HorizontalCmd 7735;

BA_ "SigType" SG_ 2499547902 MirrorLeft1VerticalCmd 5;

BA_ "SPN" SG_ 2499547902 MirrorLeft1VerticalCmd 7734;

BA_ "SigType" SG_ 2499547902 MirrorLeft1HorizontalCmd 5;

BA_ "SPN" SG_ 2499547902 MirrorLeft1HorizontalCmd 7733;

BA_ "SPN" SG_ 2499547902 RightRearWindowPosCmd 7732;

BA_ "SPN" SG_ 2499547902 LeftRearWindowPosCmd 7731;

BA_ "SPN" SG_ 2499547902 RightFrontWindowPosCmd 7730;

BA_ "SPN" SG_ 2499547902 LeftFrontWindowPosCmd 7729;

BA_ "SPN" SG_ 2499547902 RemoteCabDoorLockReq 7728;

BA_ "SPN" SG_ 2499547902 DoorsLockActCmd 7727;

BA_ "GenMsgCycleTime" BO_ 2583173374 200;

BA_ "SendOnChange" BO_ 2583173374 1;

BA_ "GenMsgSendType" BO_ 2583173374 0;

BA_ "SendOnChange" BO_ 2583177470 1;

BA_ "GenMsgSendType" BO_ 2583177470 0;

BA_ "GenMsgCycleTime" BO_ 2583177470 200;

BA_ "GenMsgCycleTime" BO_ 2583175166 200;

BA_ "SendOnChange" BO_ 2583175166 1;

BA_ "GenMsgSendType" BO_ 2583175166 0;

BA_ "GenMsgSendType" BO_ 2364552702 0;

BA_ "GenMsgCycleTime" BO_ 2364552702 100;

BA_ "GenMsgSendType" BO_ 2565865982 0;

BA_ "GenMsgCycleTime" BO_ 2565865982 100;

BA_ "SigType" SG_ 2565865982 TrctrMntdTrailerABSWarningSignal 5;

BA_ "SPN" SG_ 2565865982 TrctrMntdTrailerABSWarningSignal 1792;

BA_ "SigType" SG_ 2565865982 TrailerABSStatus 5;

BA_ "SPN" SG_ 2565865982 TrailerABSStatus 1836;

BA_ "SigType" SG_ 2565865982 HaltBrakeSwitch 4;

BA_ "SPN" SG_ 2565865982 HaltBrakeSwitch 2911;

BA_ "SPN" SG_ 2565865982 SrcAddrssOfCntrllngDvcFrBrkeCtrl 1481;

BA_ "SigType" SG_ 2565865982 ATC_ASRInformationSignal 5;

BA_ "SPN" SG_ 2565865982 ATC_ASRInformationSignal 1793;

BA_ "SigType" SG_ 2565865982 ABS_EBSAmberWarningSignal 5;

BA_ "SPN" SG_ 2565865982 ABS_EBSAmberWarningSignal 1438;

BA_ "SigType" SG_ 2565865982 EBSRedWarningSignal 5;

BA_ "SPN" SG_ 2565865982 EBSRedWarningSignal 1439;

BA_ "SigType" SG_ 2565865982 ABSFullyOperational 5;

BA_ "SPN" SG_ 2565865982 ABSFullyOperational 1243;

BA_ "SigType" SG_ 2565865982 EngRetarderSelection 1;

BA_ "SPN" SG_ 2565865982 EngRetarderSelection 973;

BA_ "SigType" SG_ 2565865982 RemoteAccelEnableSwitch 4;

BA_ "SPN" SG_ 2565865982 RemoteAccelEnableSwitch 969;

BA_ "SigType" SG_ 2565865982 EngAuxShutdownSwitch 4;

BA_ "SPN" SG_ 2565865982 EngAuxShutdownSwitch 970;

BA_ "SigType" SG_ 2565865982 EngDerateSwitch 4;

BA_ "SPN" SG_ 2565865982 EngDerateSwitch 971;

BA_ "SigType" SG_ 2565865982 AccelInterlockSwitch 4;

BA_ "SPN" SG_ 2565865982 AccelInterlockSwitch 972;

BA_ "SigType" SG_ 2565865982 TractionCtrlOverrideSwitch 4;

BA_ "SPN" SG_ 2565865982 TractionCtrlOverrideSwitch 1238;

BA_ "SigType" SG_ 2565865982 ASRHillHolderSwitch 4;

BA_ "SPN" SG_ 2565865982 ASRHillHolderSwitch 577;

BA_ "SigType" SG_ 2565865982 ASROffroadSwitch 4;

BA_ "SPN" SG_ 2565865982 ASROffroadSwitch 576;

BA_ "SigType" SG_ 2565865982 ABSOffroadSwitch 4;

BA_ "SPN" SG_ 2565865982 ABSOffroadSwitch 575;

BA_ "SigType" SG_ 2565865982 BrakePedalPos 1;

BA_ "SPN" SG_ 2565865982 BrakePedalPos 521;

BA_ "SigType" SG_ 2565865982 EBSBrakeSwitch 4;

BA_ "SPN" SG_ 2565865982 EBSBrakeSwitch 1121;

BA_ "SigType" SG_ 2565865982 AntiLockBrakingActive 5;

BA_ "SPN" SG_ 2565865982 AntiLockBrakingActive 563;

BA_ "SigType" SG_ 2565865982 ASRBrakeCtrlActive 5;

BA_ "SPN" SG_ 2565865982 ASRBrakeCtrlActive 562;

BA_ "SigType" SG_ 2565865982 ASREngCtrlActive 5;

BA_ "SPN" SG_ 2565865982 ASREngCtrlActive 561;

BA_ "GenMsgCycleTime" BO_ 2583176190 250;

BA_ "GenMsgSendType" BO_ 2583176190 0;

BA_ "GenSigStartValue" SG_ 2583176190 SigSeatSt 3;

BA_ "PpCcGenMsgType" BO_ 2381731326 "PpCcOutput";

BA_ "GenMsgSendType" BO_ 2381731326 0;

BA_ "SendOnChange" BO_ 2381731326 1;

BA_ "GenMsgCycleTime" BO_ 2381731326 1000;

BA_ "GenMsgSendType" BO_ 2381723902 0;

BA_ "GenMsgCycleTime" BO_ 2381723902 250;

BA_ "GenSigStartValue" SG_ 2381723902 AirOutTemperature 8736;

BA_ "GenSigStartValue" SG_ 2381723902 AirInTemperature 8736;

BA_ "GenSigStartValue" SG_ 2381723902 ColdCoilTemperature 8736;

BA_ "GenMsgCycleTime" BO_ 2566848570 1000;

BA_ "GenMsgSendType" BO_ 2566848570 0;

BA_ "GenMsgCycleTime" BO_ 2566848826 1000;

BA_ "GenMsgSendType" BO_ 2566848826 0;

BA_ "GenSignalSendType" SG_ 2566848826 Addressing_Status 0;

BA_ "GenMsgCycleTime" BO_ 2565814823 100;

BA_ "GenMsgSendType" BO_ 2565814823 0;

BA_ "GenMsgCycleTime" BO_ 2515942398 100;

BA_ "GenMsgSendType" BO_ 2515942398 0;

BA_ "GenSigStartValue" SG_ 2515942398 UserSaloonTemperatureRequest 9408;

BA_ "GenSigStartValue" SG_ 2515942398 UserCabinTemperatureRequest 9408;

BA_ "GenSigStartValue" SG_ 2515942398 UserCabinRecirculationRequest 3;

BA_ "GenMsgSendType" BO_ 2382245374 0;

BA_ "GenMsgCycleTime" BO_ 2382245374 100;

BA_ "GenSigStartValue" SG_ 2382245374 Thot 40;

BA_ "SigType" SG_ 2382245374 Thot 1;

BA_ "GenSigStartValue" SG_ 2382245374 Text 40;

BA_ "SigType" SG_ 2382245374 Text 1;

BA_ "GenSigStartValue" SG_ 2382245374 T_RfrLow 40;

BA_ "SigType" SG_ 2382245374 T_RfrLow 1;

BA_ "GenSigStartValue" SG_ 2382245374 T_RfrHi 40;

BA_ "SigType" SG_ 2382245374 T_RfrHi 1;

BA_ "GenSigStartValue" SG_ 2382245374 T4 40;

BA_ "SigType" SG_ 2382245374 T4 1;

BA_ "GenSigStartValue" SG_ 2382245374 T3 40;

BA_ "SigType" SG_ 2382245374 T3 1;

BA_ "GenSigStartValue" SG_ 2382245374 T2 40;

BA_ "SigType" SG_ 2382245374 T2 1;

BA_ "GenSigStartValue" SG_ 2382245374 T1 40;

BA_ "SigType" SG_ 2382245374 T1 1;

BA_ "GenMsgCycleTime" BO_ 2515942654 100;

BA_ "GenMsgSendType" BO_ 2515942654 0;

BA_ "GenSigStartValue" SG_ 2515942654 ActualSaloonTemperature 8736;

BA_ "GenSigStartValue" SG_ 2515942654 ActualCabinTemperature 8736;

BA_ "GenSigStartValue" SG_ 2515942654 TargetCabinTemperature 8736;

BA_ "GenMsgSendType" BO_ 2566845950 0;

BA_ "GenMsgCycleTime" BO_ 2566845950 1000;

BA_ "SigType" SG_ 2566845950 RoadSurfaceTemp 1;

BA_ "SPN" SG_ 2566845950 RoadSurfaceTemp 79;

BA_ "SigType" SG_ 2566845950 EngAirIntakeTemp 1;

BA_ "SPN" SG_ 2566845950 EngAirIntakeTemp 172;

BA_ "SigType" SG_ 2566845950 AmbientAirTemp 1;

BA_ "SPN" SG_ 2566845950 AmbientAirTemp 171;

BA_ "SigType" SG_ 2566845950 CabInteriorTemp 1;

BA_ "SPN" SG_ 2566845950 CabInteriorTemp 170;

BA_ "SigType" SG_ 2566845950 BarometricPress 1;

BA_ "SPN" SG_ 2566845950 BarometricPress 108;

BA_ "GenMsgSendType" BO_ 2381723646 0;

BA_ "GenMsgCycleTime" BO_ 2381723646 1000;

BA_ "GenMsgSendType" BO_ 2382239742 0;

BA_ "GenMsgCycleTime" BO_ 2382239742 100;

BA_ "GenSigStartValue" SG_ 2382239742 CabineHeatingDemand 100;

BA_ "GenSigStartValue" SG_ 2382239742 CabineCoolingDemand 100;

BA_ "GenMsgSendType" BO_ 2515949566 0;

BA_ "GenMsgCycleTime" BO_ 2515949566 1000;

BA_ "GenSigStartValue" SG_ 2515949566 TargetTemperatureState 9408;

BA_ "GenMsgCycleTime" BO_ 2515942142 100;

BA_ "GenMsgSendType" BO_ 2515942142 0;

BA_ "GenMsgCycleTime" BO_ 2516060670 300;

BA_ "GenMsgSendType" BO_ 2516060670 0;

BA_ "GenMsgSendType" BO_ 513 0;

BA_ "GenMsgCycleTime" BO_ 513 80;

BA_ "NmAsrMessage" BO_ 513 0;

BA_ "VFrameFormat" BO_ 513 0;

BA_ "GenSigSendType" SG_ 513 SensorFSL_Echo1Height 0;

BA_ "GenSigSendType" SG_ 513 SensorFSL_Echo2Dist 0;

BA_ "GenSigSendType" SG_ 513 SensorFSL_Echo1Dist 0;

BA_ "GenSigSendType" SG_ 513 SensorFSL_Echo1NumDetn 0;

BA_ "GenSigSendType" SG_ 513 SensorFSL_BlindDist 0;

BA_ "GenSigSendType" SG_ 513 SensorFSL_SignalWayId 0;

BA_ "GenMsgSendType" BO_ 545 0;

BA_ "GenMsgCycleTime" BO_ 545 80;

BA_ "NmAsrMessage" BO_ 545 0;

BA_ "VFrameFormat" BO_ 545 0;

BA_ "GenSigSendType" SG_ 545 SensorRSL_Echo1Height 0;

BA_ "GenSigSendType" SG_ 545 SensorRSL_Echo2Dist 0;

BA_ "GenSigSendType" SG_ 545 SensorRSL_Echo1Dist 0;

BA_ "GenSigSendType" SG_ 545 SensorRSL_Echo1NumDetn 0;

BA_ "GenSigSendType" SG_ 545 SensorRSL_BlindDist 0;

BA_ "GenSigSendType" SG_ 545 SensorRSL_SignalWayId 0;

BA_ "GenMsgSendType" BO_ 533 0;

BA_ "GenMsgCycleTime" BO_ 533 80;

BA_ "NmAsrMessage" BO_ 533 0;

BA_ "VFrameFormat" BO_ 533 0;

BA_ "GenSigSendType" SG_ 533 SensorFSR_Echo1Height 0;

BA_ "GenSigSendType" SG_ 533 SensorFSR_Echo2Dist 0;

BA_ "GenSigSendType" SG_ 533 SensorFSR_Echo1Dist 0;

BA_ "GenSigSendType" SG_ 533 SensorFSR_Echo1NumDetn 0;

BA_ "GenSigSendType" SG_ 533 SensorFSR_BlindDist 0;

BA_ "GenSigSendType" SG_ 533 SensorFSR_SignalWayId 0;

BA_ "GenMsgSendType" BO_ 565 0;

BA_ "GenMsgCycleTime" BO_ 565 80;

BA_ "NmAsrMessage" BO_ 565 0;

BA_ "VFrameFormat" BO_ 565 0;

BA_ "GenSigSendType" SG_ 565 SensorRSR_Echo1Height 0;

BA_ "GenSigSendType" SG_ 565 SensorRSR_Echo2Dist 0;

BA_ "GenSigSendType" SG_ 565 SensorRSR_Echo1Dist 0;

BA_ "GenSigSendType" SG_ 565 SensorRSR_Echo1NumDetn 0;

BA_ "GenSigSendType" SG_ 565 SensorRSR_BlindDist 0;

BA_ "GenSigSendType" SG_ 565 SensorRSR_SignalWayId 0;

BA_ "GenMsgSendType" BO_ 517 0;

BA_ "GenMsgCycleTime" BO_ 517 80;

BA_ "NmAsrMessage" BO_ 517 0;

BA_ "VFrameFormat" BO_ 517 0;

BA_ "GenSigSendType" SG_ 517 SensorFOL_Echo1Height 0;

BA_ "GenSigSendType" SG_ 517 SensorFOL_Echo2Dist 0;

BA_ "GenSigSendType" SG_ 517 SensorFOL_Echo1Dist 0;

BA_ "GenSigSendType" SG_ 517 SensorFOL_Echo1NumDetn 0;

BA_ "GenSigSendType" SG_ 517 SensorFOL_BlindDist 0;

BA_ "GenSigSendType" SG_ 517 SensorFOL_SignalWayId 0;

BA_ "GenMsgSendType" BO_ 549 0;

BA_ "GenMsgCycleTime" BO_ 549 80;

BA_ "NmAsrMessage" BO_ 549 0;

BA_ "VFrameFormat" BO_ 549 0;

BA_ "GenSigSendType" SG_ 549 SensorROL_Echo1Height 0;

BA_ "GenSigSendType" SG_ 549 SensorROL_Echo2Dist 0;

BA_ "GenSigSendType" SG_ 549 SensorROL_Echo1Dist 0;

BA_ "GenSigSendType" SG_ 549 SensorROL_Echo1NumDetn 0;

BA_ "GenSigSendType" SG_ 549 SensorROL_BlindDist 0;

BA_ "GenSigSendType" SG_ 549 SensorROL_SignalWayId 0;

BA_ "GenMsgSendType" BO_ 521 0;

BA_ "GenMsgCycleTime" BO_ 521 80;

BA_ "NmAsrMessage" BO_ 521 0;

BA_ "VFrameFormat" BO_ 521 0;

BA_ "GenSigSendType" SG_ 521 SensorFIL_Echo1Height 0;

BA_ "GenSigSendType" SG_ 521 SensorFIL_Echo2Dist 0;

BA_ "GenSigSendType" SG_ 521 SensorFIL_Echo1Dist 0;

BA_ "GenSigSendType" SG_ 521 SensorFIL_Echo1NumDetn 0;

BA_ "GenSigSendType" SG_ 521 SensorFIL_BlindDist 0;

BA_ "GenSigSendType" SG_ 521 SensorFIL_SignalWayId 0;

BA_ "GenMsgSendType" BO_ 553 0;

BA_ "GenMsgCycleTime" BO_ 553 80;

BA_ "NmAsrMessage" BO_ 553 0;

BA_ "VFrameFormat" BO_ 553 0;

BA_ "GenSigSendType" SG_ 553 SensorRIL_Echo1Height 0;

BA_ "GenSigSendType" SG_ 553 SensorRIL_Echo2Dist 0;

BA_ "GenSigSendType" SG_ 553 SensorRIL_Echo1Dist 0;

BA_ "GenSigSendType" SG_ 553 SensorRIL_Echo1NumDetn 0;

BA_ "GenSigSendType" SG_ 553 SensorRIL_BlindDist 0;

BA_ "GenSigSendType" SG_ 553 SensorRIL_SignalWayId 0;

BA_ "GenMsgSendType" BO_ 525 0;

BA_ "GenMsgCycleTime" BO_ 525 80;

BA_ "NmAsrMessage" BO_ 525 0;

BA_ "VFrameFormat" BO_ 525 0;

BA_ "GenSigSendType" SG_ 525 SensorFIR_Echo1Height 0;

BA_ "GenSigSendType" SG_ 525 SensorFIR_Echo2Dist 0;

BA_ "GenSigSendType" SG_ 525 SensorFIR_Echo1Dist 0;

BA_ "GenSigSendType" SG_ 525 SensorFIR_Echo1NumDetn 0;

BA_ "GenSigSendType" SG_ 525 SensorFIR_BlindDist 0;

BA_ "GenSigSendType" SG_ 525 SensorFIR_SignalWayId 0;

BA_ "GenMsgSendType" BO_ 557 0;

BA_ "GenMsgCycleTime" BO_ 557 80;

BA_ "NmAsrMessage" BO_ 557 0;

BA_ "VFrameFormat" BO_ 557 0;

BA_ "GenSigSendType" SG_ 557 SensorRIR_Echo1Height 0;

BA_ "GenSigSendType" SG_ 557 SensorRIR_Echo2Dist 0;

BA_ "GenSigSendType" SG_ 557 SensorRIR_Echo1Dist 0;

BA_ "GenSigSendType" SG_ 557 SensorRIR_Echo1NumDetn 0;

BA_ "GenSigSendType" SG_ 557 SensorRIR_BlindDist 0;

BA_ "GenSigSendType" SG_ 557 SensorRIR_SignalWayId 0;

BA_ "GenMsgSendType" BO_ 529 0;

BA_ "GenMsgCycleTime" BO_ 529 80;

BA_ "NmAsrMessage" BO_ 529 0;

BA_ "VFrameFormat" BO_ 529 0;

BA_ "GenSigSendType" SG_ 529 SensorFOR_Echo1Height 0;

BA_ "GenSigSendType" SG_ 529 SensorFOR_Echo2Dist 0;

BA_ "GenSigSendType" SG_ 529 SensorFOR_Echo1Dist 0;

BA_ "GenSigSendType" SG_ 529 SensorFOR_Echo1NumDetn 0;

BA_ "GenSigSendType" SG_ 529 SensorFOR_BlindDist 0;

BA_ "GenSigSendType" SG_ 529 SensorFOR_SignalWayId 0;

BA_ "GenMsgSendType" BO_ 561 0;

BA_ "GenMsgCycleTime" BO_ 561 80;

BA_ "NmAsrMessage" BO_ 561 0;

BA_ "VFrameFormat" BO_ 561 0;

BA_ "GenSigSendType" SG_ 561 SensorROR_Echo1Height 0;

BA_ "GenSigSendType" SG_ 561 SensorROR_Echo2Dist 0;

BA_ "GenSigSendType" SG_ 561 SensorROR_Echo1Dist 0;

BA_ "GenSigSendType" SG_ 561 SensorROR_Echo1NumDetn 0;

BA_ "GenSigSendType" SG_ 561 SensorROR_BlindDist 0;

BA_ "GenSigSendType" SG_ 561 SensorROR_SignalWayId 0;

BA_ "GenMsgSendType" BO_ 2516060414 0;

BA_ "GenMsgCycleTime" BO_ 2516060414 300;

BA_ "GenMsgSendType" BO_ 2516059134 0;

BA_ "GenMsgCycleTime" BO_ 2516059134 300;

BA_ "GenMsgSendType" BO_ 2516059390 0;

BA_ "GenMsgCycleTime" BO_ 2516059390 300;

BA_ "GenMsgSendType" BO_ 2516059646 0;

BA_ "GenMsgCycleTime" BO_ 2516059646 300;

BA_ "GenMsgSendType" BO_ 2566803454 0;

BA_ "GenMsgCycleTime" BO_ 2566803454 100;

BA_ "SigType" SG_ 2566803454 TrailerVDCActive 5;

BA_ "SPN" SG_ 2566803454 TrailerVDCActive 5624;

BA_ "SigType" SG_ 2566803454 YCBrakeCtrlActive 5;

BA_ "SPN" SG_ 2566803454 YCBrakeCtrlActive 1819;

BA_ "SigType" SG_ 2566803454 YCEngCtrlActive 5;

BA_ "SPN" SG_ 2566803454 YCEngCtrlActive 1817;

BA_ "SigType" SG_ 2566803454 ROPBrakeCtrlActive 5;

BA_ "SPN" SG_ 2566803454 ROPBrakeCtrlActive 1818;

BA_ "SigType" SG_ 2566803454 ROPEngCtrlActive 5;

BA_ "SPN" SG_ 2566803454 ROPEngCtrlActive 1816;

BA_ "SigType" SG_ 2566803454 VDCBrakeLightRq 5;

BA_ "SPN" SG_ 2566803454 VDCBrakeLightRq 1815;

BA_ "SigType" SG_ 2566803454 VDCFullyOperational 5;

BA_ "SPN" SG_ 2566803454 VDCFullyOperational 1814;

BA_ "SigType" SG_ 2566803454 VDCInformationSignal 5;

BA_ "SPN" SG_ 2566803454 VDCInformationSignal 1813;

VAL_ 2180423678 rllrShttrLckActtRq 3 "Not Available" 1 "Locked" 0 "Unlocked" ;

VAL_ 2381750526 hzrdSwtchStt 3 "Not available" 2 "Reserved" 1 "Pressed" 0 "No Action" ;

VAL_ 2381750782 rghtDRLStt 3 "Not Available" 2 "Fault Detected" 1 "Activated" 0 "De activated" ;

VAL_ 2381750782 frntLftPstnLmpStt 3 "Not Available" 2 "Fault Detected" 1 "Activated" 0 "De activated" ;

VAL_ 2381750782 frntRghtPstnLmpCmd 3 "Don't Care" 2 "Reserved" 1 "Activate" 0 "De activate" ;

VAL_ 2381750782 LftDRLCmmnd 3 "Don't Care" 2 "Reserved" 1 "Activate" 0 "De activate" ;

VAL_ 2381750782 RrFgLmpCmd 3 "Don't Care" 2 "Reserved" 1 "Activate" 0 "De activate" ;

VAL_ 2381750782 rrLftPstnLmpCmd 3 "Don't Care" 2 "Reserved" 1 "Activate" 0 "De activate" ;

VAL_ 2381750782 rrRgstrtnPltLmpCmd 3 "Don't Care" 2 "Reserved" 1 "Activate" 0 "De activate" ;

VAL_ 2381750782 dppdBmLmpCmd 3 "Don't Care" 2 "Reserved" 1 "Activate" 0 "De activate" ;

VAL_ 2381750782 mnBmLmpCmd 3 "Don't Care" 2 "Reserved" 1 "Activate" 0 "De activate" ;

VAL_ 2381750782 cttRghtSdLmp 3 "Don't Care" 2 "Reserved" 1 "Activate" 0 "De activate" ;

VAL_ 2381750782 cttLftSdLmp 3 "Don't Care" 2 "Reserved" 1 "Activate" 0 "De activate" ;

VAL_ 2381751038 lftDRLStt 3 "Not Available" 2 "Fault Detected" 1 "Activated" 0 "De activated" ;

VAL_ 2381751038 LftDppdBmLmpStt 3 "Not Available" 2 "Fault Detected" 1 "Activated" 0 "De activated" ;

VAL_ 2381751038 LftMnBmLmpStt 3 "Not Available" 2 "Fault Detected" 1 "Activated" 0 "De activated" ;

VAL_ 2381751038 frntRghtPstnLmpStt 3 "Not Available" 2 "Fault Detected" 1 "Activated" 0 "De activated" ;

VAL_ 2381751038 lftSdIndctrStt 3 "Not Available" 2 "Fault Detected" 1 "Activated" 0 "De activated" ;

VAL_ 2381751038 frntRghtIndctrStt 3 "Not Available" 2 "Fault Detected" 1 "Activated" 0 "De activated" ;

VAL_ 2381751038 frntLftIndctrStt 3 "Not Available" 2 "Fault Detected" 1 "Activated" 0 "De activated" ;

VAL_ 2381751294 rghtBrkLmpStt 3 "Not Available" 2 "Fault Detected" 1 "Activated" 0 "De activated" ;

VAL_ 2381751294 rrRghtPstnLmpStt 3 "Not Available" 2 "Fault Detected" 1 "Activated" 0 "De activated" ;

VAL_ 2381751294 rrRghtIndctrStt 3 "Not Available" 2 "Fault Detected" 1 "Activated" 0 "De activated" ;

VAL_ 2381751550 RrLftFgLmpStt 3 "Not Available" 2 "Fault Detected" 1 "Activated" 0 "De activated" ;

VAL_ 2381751550 rrLftPstnLmpStt 3 "Not Available" 2 "Fault Detected" 1 "Activated" 0 "De activated" ;

VAL_ 2381751550 rrLftIndctrStt 3 "Not Available" 2 "Fault Detected" 1 "Activated" 0 "De activated" ;

VAL_ 2381751550 brkLmpsCmmnd 3 "Don't Care" 2 "Reserved" 1 "Activate" 0 "De activate" ;

VAL_ 2583078398 blkhdDrLtchStt 3 "Not Available" 2 "Error" 1 "Latched" 0 "Unlatched" ;

VAL_ 2583078654 blkhdDrLtchRq 3 "Not Available" 2 "DoubleLock" 1 "Unlatch" 0 "Inactive" ;

VAL_ 2583078654 pssDrLtchRq 3 "Not Available" 2 "DoubleLock" 1 "Unlatch" 0 "Inactive" ;

VAL_ 2583078654 drvrDrLtchRq 3 "Not Available" 2 "DoubleLock" 1 "Unlatch" 0 "Inactive" ;

VAL_ 2583078910 pssPwrSldngDrSttDspl 7 "Not available" 6 "Error" 5 "Unknown" 4 "Closing" 3 "Opening" 2 "Intermediate" 1 "Closed" 0 "Open" ;

VAL_ 2583078910 pssDrLtchStt 3 "Not Available" 2 "Closed" 1 "Ajared" 0 "Opened" ;

VAL_ 2583079166 snsdSrvcHtchStt 3 "NA" 2 "Error" 1 "Opened" 0 "Closed" ;

VAL_ 2583210494 WshrCmmnd 1 "WSH_TurnOn" 0 "WSH_TurnOff" ;

VAL_ 2583210750 Glss2HtrStt 3 "Not available" 2 "Error" 1 "On" 0 "Off" ;

VAL_ 2583211006 Glss3HtrStt 3 "Not available" 2 "Error" 1 "On" 0 "Off" ;

VAL_ 2365443838 MainBeamStalksReq 3 "Not available" 2 "Full Pull" 1 "Half Pull" 0 "No Action" ;

VAL_ 2365443838 TurnIndReq 5 "Not available" 4 "Full Down" 3 "Half Down" 2 "Full Up" 1 "Half Up" 0 "No Action" ;

VAL_ 2365443838 SwitchReq 3 "Not available" 2 "Reserved" 1 "Pressed" 0 "No Action" ;

VAL_ 2565868030 SteerWheelAngleSensorType 3 "Not Available" 2 "Reserved" 1 "Absolute measuring principle" 0 "Relative measuring principle" ;

VAL_ 2566767870 EmergencyBrakingActive 3 "not available" 2 "reserved" 1 "active" 0 "inactive" ;

VAL_ 2566767870 PrkngBrakeActuatorFullyActivated 3 "Not available" 2 "Error" 1 "Parking Brake Actuator fully activated" 0 "Parking Brake Actuator not fully activated" ;

VAL_ 2566767870 XBRActiveCtrlMode 15 "Not available" 3 "Maximum mode of XBR acceleration control being executed" 2 "Addition mode of XBR acceleration control being executed" 1 "Driver's brake demand being executed" 0 "No brake demand being executed" ;

VAL_ 2566767870 XBRSystemState 3 "not available" 2 "No external brake demand will be accepted" 1 "Only external brake demand of highest XBR Priority" 0 "Any external brake demand will be accepted" ;

VAL_ 2566767870 FoundationBrakeUse 3 "Not available" 2 "Reserved" 1 "Foundation brakes in use" 0 "Foundation brakes not in use" ;

VAL_ 2566767870 HillHolderMode 7 "Not available" 6 "Hill holder not functional" 3 "Active,  but may activate parking brake if needed." 2 "Active,  but will change to inactive in a short time" 1 "Active" 0 "Inactive" ;

VAL_ 2566767870 HaltBrakeMode 7 "Not available" 6 "Halt brake not functional" 2 "Active,  but not functioning properly" 1 "Active" 0 "Inactive" ;

VAL_ 2566767870 BrakeTempWarning 3 "not available" 2 "Reserved" 1 "Active" 0 "Not Active" ;

VAL_ 2365484286 DirectionIndicator 3 "Not available" 2 "Error" 1 "Reverse" 0 "Forward" ;

VAL_ 2365484286 TachographPerformance 3 "Not available" 2 "Error" 1 "Performance analysis" 0 "Normal performance" ;

VAL_ 2365484286 HandlingInformation 3 "Not available" 2 "Error" 1 "Handling information" 0 "No handling information" ;

VAL_ 2365484286 SystemEvent 3 "Not available" 2 "Error" 1 "Tachograph event" 0 "No tachograph event" ;

VAL_ 2365484286 DriverCardDriver2 3 "Not available" 2 "Error" 1 "Driver card present" 0 "Driver card not present" ;

VAL_ 2365484286 Driver2TimeRelatedStates 15 "Not available" 14 "Error" 13 "Other" 6 "Limit #6" 5 "Limit #5" 4 "Limit #4" 3 "Limit #3" 2 "Limit #2" 1 "Limit #1" 0 "Normal/No limits reached" ;

VAL_ 2365484286 VehicleOverspeed 3 "Not available" 2 "Error" 1 "Overspeed" 0 "No overspeed" ;

VAL_ 2365484286 DriverCardDriver1 3 "Not available" 2 "Error" 1 "Driver card present" 0 "Driver card not present" ;

VAL_ 2365484286 Driver1TimeRelatedStates 15 "Not available" 14 "Error" 13 "Other" 6 "Limit #6" 5 "Limit #5" 4 "Limit #4" 3 "Limit #3" 2 "Limit #2" 1 "Limit #1" 0 "Normal/No limits reached" ;

VAL_ 2365484286 VehicleMotion 3 "- Not available" 2 "- Error" 1 "Vehicle motion detected" 0 "Vehicle motion not detected" ;

VAL_ 2365484286 Driver2WorkingState 7 "Not available" 6 "Error" 3 "Drive" 2 "Work" 1 "Driver available" 0 "Rest" ;

VAL_ 2365484286 Driver1WorkingState 7 "Not available" 6 "Error" 3 "Drive" 2 "Work" 1 "Driver available" 0 "Rest" ;

VAL_ 2582766846 ACU_Active 3 "Not_Available" 2 "Error" 1 "Siren_on" 0 "Siren_off" ;

VAL_ 2582766846 ACU_Alarm 3 "Not_Available" 2 "Error" 1 "Alarm_on" 0 "Alarm_off" ;

VAL_ 2582766846 USS_Status 3 "Not_Available" 2 "Error" 1 "Armed" 0 "Disarmed" ;

VAL_ 2582766846 ACU_Status 3 "NA" 2 "Error" 1 "Armed" 0 "Disarmed" ;

VAL_ 2582766846 Intrusion_detected 3 "N/A" 2 "Reserved" 1 "Intrusion_detected " 0 "Intrusion_not_detected " ;

VAL_ 2382314494 GS_Inhibits 7 "NA" 6 "Error" 1 "RDSpeedInhib" 0 "NoNotification" 5 "RNDChargeInhib" 4 "PSpeedInhib" 3 "NBrakeInhib" 2 "RDBrakeInhib" ;

VAL_ 2382314494 GS_Est_State 14 "Park_Reverse" 13 "Park_Drive" 11 "Change_in_Progress" 10 "Reverse_PErr" 9 "Drive_PErr" 8 "Neutral_PErr" 7 "Park_DT_Err" 6 "DT_Err" 5 "Reverse" 4 "Drive" 3 "Neutral" 2 "Park" 1 "Error" 0 "N_A" ;

VAL_ 2382314494 Drvtr_state 11 "Change_in_Progress" 1 "Error" 0 "N_A" 5 "Reverse" 4 "Drive" 3 "Neutral" ;

VAL_ 2382314494 move_lock_req 2 "Take_no_action" 1 "Unlocked" 0 "Locked" ;

VAL_ 2382314494 GS_Demand 16 "Reverse_ NoAction" 15 "Drive_NoAction" 14 "Park_Reverse" 13 "Park_Drive" 12 "Neutral_NoAction" 5 "Reverse" 4 "Drive" 3 "Neutral" 2 "Park" ;

VAL_ 2365473278 ImplementRearWorkLightCmd 3 "Don't Care" 2 "Reserved" 1 "Activate" 0 "De-activate" ;

VAL_ 2365473278 ImplLeftFacingWorkLightCmd 3 "Don't Care" 2 "Reserved" 1 "Activate" 0 "De-activate" ;

VAL_ 2365473278 ImplRightFwdWorkLightCmd 3 "Don't Care" 2 "Reserved" 1 "Activate" 0 "De-activate" ;

VAL_ 2365473278 LightingDataRqCmd 3 "Don't Care" 2 "Reserved" 1 "Activate" 0 "De-activate" ;

VAL_ 2365473278 ImplLeftForwardWorkLightCmd 3 "Don't Care" 2 "Reserved" 1 "Activate" 0 "De-activate" ;

VAL_ 2365473278 ImplRightFacingWorkLightCmd 3 "Don't Care" 2 "Reserved" 1 "Activate" 0 "De-activate" ;

VAL_ 2365473278 ImplOEMOption1LightCmd 3 "Don't Care" 2 "Reserved" 1 "Activate" 0 "De-activate" ;

VAL_ 2365473278 ImplOEMOption2LightCmd 3 "Don't Care" 2 "Reserved" 1 "Activate" 0 "De-activate" ;

VAL_ 2365473278 TrctrFrntHghMdWkLightsCmd 3 "Don't Care" 2 "Reserved" 1 "Activate" 0 "De-activate" ;

VAL_ 2365473278 TrctrFrntLowMdWkLightsCmd 3 "Don't Care" 2 "Reserved" 1 "Activate" 0 "De-activate" ;

VAL_ 2365473278 TrctrSdeHighMdWkLightsCmd 3 "Don't Care" 2 "Reserved" 1 "Activate" 0 "De-activate" ;

VAL_ 2365473278 TrctrSideLowMdWkLightsCmd 3 "Don't Care" 2 "Reserved" 1 "Activate" 0 "De-activate" ;

VAL_ 2365473278 TrctrRarHighMdWkLightsCmd 3 "Don't Care" 2 "Reserved" 1 "Activate" 0 "De-activate" ;

VAL_ 2365473278 TrctrRearLowMdWkLightsCmd 3 "Don't Care" 2 "Reserved" 1 "Activate" 0 "De-activate" ;

VAL_ 2365473278 TrctrUndrsdeMdWkLightsCmd 3 "Don't Care" 2 "Reserved" 1 "Activate" 0 "De-activate" ;

VAL_ 2365473278 RearFogLightsCmd 3 "Don't Care" 2 "Reserved" 1 "Activate" 0 "De-activate" ;

VAL_ 2365473278 TractorMarkerLightCmd 3 "Don't Care" 2 "Reserved" 1 "Activate" 0 "De-activate" ;

VAL_ 2365473278 ImplementMarkerLightCmd 2 "Reserved" 3 "Don't Care" 1 "Activate" 0 "De-activate" ;

VAL_ 2365473278 TractorClearanceLightCmd 3 "Don't Care" 2 "Reserved" 1 "Activate" 0 "De-activate" ;

VAL_ 2365473278 ImplementClearanceLightCmd 3 "Don't Care" 2 "Reserved" 1 "Activate" 0 "De-activate" ;

VAL_ 2365473278 LeftStopLightCmd 3 "Don't Care" 2 "Reserved" 1 "Activate" 0 "De-activate" ;

VAL_ 2365473278 RightStopLightCmd 3 "Don't Care" 2 "Reserved" 1 "Activate" 0 "De-activate" ;

VAL_ 2365473278 CenterStopLightCmd 3 "Don't Care" 2 "Reserved" 1 "Activate" 0 "De-activate" ;

VAL_ 2365473278 BackUpLightAndAlarmHornCmd 3 "Don't Care" 2 "Reserved" 1 "Activate" 0 "De-activate" ;

VAL_ 2365473278 LeftTurnSignalLightsCmd 3 "Don't Care" 2 "Reserved" 1 "Activate" 0 "De-activate" ;

VAL_ 2365473278 RightTurnSignalLightsCmd 3 "Don't Care" 2 "Reserved" 1 "Activate" 0 "De-activate" ;

VAL_ 2365473278 RotatingBeaconLightCmd 3 "Don't Care" 2 "Reserved" 1 "Activate" 0 "De-activate" ;

VAL_ 2365473278 TractorFrontFogLightsCmd 3 "Don't Care" 2 "Reserved" 1 "Activate" 0 "De-activate" ;

VAL_ 2365473278 HighBeamHeadLightCmd 3 "Don't Care" 2 "Reserved" 1 "Activate" 0 "De-activate" ;

VAL_ 2365473278 LowBeamHeadLightCmd 3 "Don't Care" 2 "Reserved" 1 "Activate" 0 "De-activate" ;

VAL_ 2365473278 AltBeamHeadLightCmd 3 "Don't Care" 2 "Reserved" 1 "Activate" 0 "De-activate" ;

VAL_ 2365473278 RunningLightCmd 3 "Don't Care" 2 "Reserved" 1 "Activate" 0 "De-activate" ;

VAL_ 2399117310 VSM_Substate 4 "Substate4" 3 "Substate3" 2 "Substate2" 1 "Substate1" 0 "Default" ;

VAL_ 2399117310 VSM_State 7 "NA" 5 "LongTerm Park" 4 "Maintenance" 3 "Charging" 2 "Ready" 1 "Awake" 0 "Sleep" ;

VAL_ 2566799614 ImplementRearWorkLight 3 "Not Available" 2 "Fault Detected" 1 "Activated" 0 "De-activated" ;

VAL_ 2566799614 ImplLeftFacingWorkLight 3 "Not Available" 2 "Fault Detected" 1 "Activated" 0 "De-activated" ;

VAL_ 2566799614 ImplRightForwardWorkLight 3 "Not Available" 2 "Fault Detected" 1 "Activated" 0 "De-activated" ;

VAL_ 2566799614 ImplLeftForwardWorkLight 3 "Not Available" 2 "Fault Detected" 1 "Activated" 0 "De-activated" ;

VAL_ 2566799614 ImplRightFacingWorkLight 3 "Not Available" 2 "Fault Detected" 1 "Activated" 0 "De-activated" ;

VAL_ 2566799614 ImplementOEMOption1Light 3 "Not Available" 2 "Fault Detected" 1 "Activated" 0 "De-activated" ;

VAL_ 2566799614 ImplementOEMOption2Light 3 "Not Available" 2 "Fault Detected" 1 "Activated" 0 "De-activated" ;

VAL_ 2566799614 TrctorFrontHighMdWkLights 3 "Not Available" 2 "Fault Detected" 1 "Activated" 0 "De-activated" ;

VAL_ 2566799614 TractorFrontLowMdWkLights 3 "Not Available" 2 "Fault Detected" 1 "Activated" 0 "De-activated" ;

VAL_ 2566799614 TractorSideHighMdWkLights 3 "Not Available" 2 "Fault Detected" 1 "Activated" 0 "De-activated" ;

VAL_ 2566799614 TractorSideLowMdWkLights 3 "Not Available" 2 "Fault Detected" 1 "Activated" 0 "De-activated" ;

VAL_ 2566799614 TractorRearHighMdWkLights 3 "Not Available" 2 "Fault Detected" 1 "Activated" 0 "De-activated" ;

VAL_ 2566799614 TractorRearLowMdWkLights 3 "Not Available" 2 "Fault Detected" 1 "Activated" 0 "De-activated" ;

VAL_ 2566799614 TrctorUndersideMdWkLights 3 "Not Available" 2 "Fault Detected" 1 "Activated" 0 "De-activated" ;

VAL_ 2566799614 RearFogLights 3 "Not Available" 2 "Fault Detected" 1 "Activated" 0 "De-activated" ;

VAL_ 2566799614 TractorMarkerLight 3 "Not Available" 2 "Fault Detected" 1 "Activated" 0 "De-activated" ;

VAL_ 2566799614 ImplementMarkerLight 3 "Not Available" 2 "Fault Detected" 1 "Activated" 0 "De-activated" ;

VAL_ 2566799614 TractorClearanceLight 3 "Not Available" 2 "Fault Detected" 1 "Activated" 0 "De-activated" ;

VAL_ 2566799614 ImplementClearanceLight 3 "Not Available" 2 "Fault Detected" 1 "Activated" 0 "De-activated" ;

VAL_ 2566799614 LeftStopLight 3 "Not Available" 2 "Fault Detected" 1 "Activated" 0 "De-activated" ;

VAL_ 2566799614 RightStopLight 3 "Not Available" 2 "Fault Detected" 1 "Activated" 0 "De-activated" ;

VAL_ 2566799614 CenterStopLight 3 "Not Available" 2 "Fault Detected" 1 "Activated" 0 "De-activated" ;

VAL_ 2566799614 BackUpLightAndAlarmHorn 3 "Not Available" 2 "Fault Detected" 1 "Activated" 0 "De-activated" ;

VAL_ 2566799614 LeftTurnSignalLights 3 "Not Available" 2 "Fault Detected" 1 "Activated" 0 "De-activated" ;

VAL_ 2566799614 RightTurnSignalLights 3 "Not Available" 2 "Fault Detected" 1 "Activated" 0 "De-activated" ;

VAL_ 2566799614 RotatingBeaconLight 3 "Not Available" 2 "Fault Detected" 1 "Activated" 0 "De-activated" ;

VAL_ 2566799614 TractorFrontFogLights 3 "Not Available" 2 "Fault Detected" 1 "Activated" 0 "De-activated" ;

VAL_ 2566799614 HighBeamHeadLight 3 "Not Available" 2 "Fault Detected" 1 "Activated" 0 "De-activated" ;

VAL_ 2566799614 LowBeamHeadLight 3 "Not Available" 2 "Fault Detected" 1 "Activated" 0 "De-activated" ;

VAL_ 2566799614 AltBeamHeadLight 3 "Not Available" 2 "Fault Detected" 1 "Activated" 0 "De-activated" ;

VAL_ 2566799614 RunningLight 3 "Not Available" 2 "Fault Detected" 1 "Activated" 0 "De-activated" ;

VAL_ 2381851134 HornSwitchReq 3 "HornSwtReqNA" 2 "HornSwtReqErr" 1 "HornSwtReqOn" 0 "HornSwtReqOff" ;

VAL_ 2382241534 CoolantTank_2_LevelSt 3 "NA" 2 "Reserved" 1 "High" 0 "Low" ;

VAL_ 2382241534 CoolantTank_1_LevelSt 3 "NA" 2 "Reserved" 1 "High" 0 "Low" ;

VAL_ 2382241534 OverheatEvent_Overall 3 "Overheat_NA" 2 "Overheat_Error" 1 "Overheat_Detected" 0 "Overheat_Not_Detected" ;

VAL_ 2382241534 MalfunctionEvent_Overall 3 "NA" 2 "Critical_Event" 1 "Medium_Event" 0 "Not_Detected" ;

VAL_ 2382241534 OverheatEvent 15 "Overheat_NA" 14 "Overheat_Error" 6 "Overheat_Battery" 5 "Overheat_DCDC" 4 "Overheat_OBC" 3 "Overheat_Gearbox" 2 "Overheat_Motor" 1 "Overheat_Invertor" 0 "Overheat_Nothing" ;

VAL_ 2382241534 ThermalSystemFault 14 "ThrFlt_Error" 15 "ThrFlt_NA" 3 "ThrFlt_DeviceFault" 2 "ThrFlt_CAN_Comm" 1 "ThrFlt_AmbOORange" 0 "ThrFlt_Nothing" ;

VAL_ 2583062270 DoorsSleepReadyState 3 "Not Available" 1 "All doors standstill" 0 "Any door moving" ;

VAL_ 2583062270 ServiceHatchLatchState 3 "NA" 2 "Fault" 1 "Open" 0 "Closed" ;

VAL_ 2583062270 CargoSideDoorLatchState 3 "Not Available" 2 "Error" 1 "Latched" 0 "Unlatched" ;

VAL_ 2583062270 CargoRearDoorLatchState 3 "Not Available" 2 "Error" 1 "Latched" 0 "Unlatched" ;

VAL_ 2583062270 BulkheadDoorLatchState 3 "Not Available" 2 "Error" 1 "Latched" 0 "Unlatched" ;

VAL_ 2583062270 PassDoorLatchState 3 "Not Available" 2 "Error" 1 "Latched" 0 "Unlatched" ;

VAL_ 2583062270 DriverDoorLatchState 3 "Not Available" 2 "Error" 1 "Latched" 0 "Unlatched" ;

VAL_ 2583062270 DoorsOpenState 3 "Not Available" 2 "Error" 1 "All doors closed" 0 "Any door opened" ;

VAL_ 2566882814 KeyRange 7 "Not Available" 6 "Error" 5 "In Cabin" 4 "In Use Range" 3 "In Wake Up Range" 2 "In Operational Range" 1 "Out of Operational Range" 0 "Lost" ;

VAL_ 2566882814 KeyCommand 7 "Not Available" 6 "Error" 5 "Reserved" 4 "Reserved" 3 "Reserved" 2 "Find Car" 1 "Fully Lock Vehicle" 0 "Unlock Vehicle" ;

VAL_ 2583062526 CentralLockRequest 7 "Not Available" 6 "Error" 5 "Unlock Cargo Side Door" 4 "Unlock Cargo Rear Door" 3 "Unlock Passenger Door" 2 "Unlock Driver Door" 1 "Fully Lock Vehicle" 0 "Unlock Vehicle" ;

VAL_ 2399123966 KeyfobBatteryState 7 "NA" 6 "Error" 5 "Reserved" 4 "Reserved" 3 "Reserved" 2 "Critical Level" 1 "Low Level" 0 "Battery OK" ;

VAL_ 2399123966 SecurityWakeUpRequest 3 "NA" 2 "Error" 1 "SecurityWakeUp" 0 "SecurityNotWakeUp" ;

VAL_ 2399123966 SecurityReadyToSleep 3 "NA" 2 "Error" 1 "Security Ready" 0 "Security Not Ready" ;

VAL_ 2399123966 VehicleLockState 3 "NA" 2 "Error" 1 "Unlocked" 0 "Locked" ;

VAL_ 2399123966 DriveSecurityState 3 "NA" 2 "Error" 1 "Unlocked" 0 "Locked" ;

VAL_ 2583065854 CentralLockRequest 7 "Not Available" 6 "Error" 5 "Unlock Cargo Side Door" 4 "Unlock Cargo Rear Door" 3 "Unlock Passenger Door" 2 "Unlock Driver Door" 1 "Fully Lock Vehicle" 0 "Unlock Vehicle" ;

VAL_ 2163223550 CrashType 16 "rollover" 8 "side crash, right)" 4 "side crash, left)" 2 "rear crash" 1 "frontal crash" ;

VAL_ 2583173886 WipeRequest 7 "WPR_NA" 6 "WPR_Reserved" 5 "WPR_Auto" 4 "WPR_HighSpeed" 3 "WPR_LowSpeed" 2 "WPR_Intermittent" 1 "WPR_SingleStroke" 0 "WPR_TurnOff" ;

VAL_ 2583173886 WashRequest 3 "NA" 2 "Error" 1 "WSH_TurnOn" 0 "WSH_TurnOff" ;

VAL_ 2516075518 RideHeight_Value 0 "Nominal" 1 "Upper" 2 "Lower" 3 "Kneeling" 4 "JackMode" 5 "Fault" 6 "NA" 7 "Reserved" ;

VAL_ 2448847102 RHSensorsFault 3 "NA" 2 "Reserved" 1 "RH Fault" 0 "Ok" ;

VAL_ 2448847102 PMSWarning 3 "NA" 2 "Fault" 1 "Active" 0 "Off" ;

VAL_ 2448847358 IMUFault 3 "NA" 2 "Reserved" 1 "IMU Fault" 0 "Ok" ;

VAL_ 2297441790 SpprtVrblTrnsRpttnRtFrAcclrtnSns 3 "ECU only supports standard transmission rate of 10 ms" 2 "20 ms rate supported" 1 "Reserved for SAE assignment" 0 "Reserve for SAE assignment" ;

VAL_ 2297441790 VrtclAcclrtnExRangeFigureOfMerit 3 "not available" 2 "error" 1 "verticalacceleration is degraded" 0 "vertical acceleration is fully functional" ;

VAL_ 2297441790 LngtdnlAcclrtnExRngFigureOfMerit 3 "not available" 2 "error" 1 "longitudinal acceleration is degraded" 0 "longitudinal acceleration is fully functional" ;

VAL_ 2297441790 LtrlAcclrtonExRangeFigureOfMerit 3 "not available" 2 "error" 1 "lateral acceleration is degraded" 0 "lateral acceleration is fully functional" ;

VAL_ 2583180030 WindowHeatedGlassSt 3 "Not available" 2 "Error" 1 "On" 0 "Off" ;

VAL_ 2583180030 FrontDoorHeatedGlassSt 3 "Not available" 2 "Error" 1 "On" 0 "Off" ;

VAL_ 2583180030 RearHeatedWindscreenSt 3 "Not available" 2 "Error" 1 "On" 0 "Off" ;

VAL_ 2583180030 FrontHeatedWindscreenSt 3 "Not available" 2 "Error" 1 "On" 0 "Off" ;

VAL_ 2499547902 MirrorRight2HeatCmd 3 "Take no action" 2 "Reserved" 1 "Mirror heat on" 0 "Mirror heat off" ;

VAL_ 2499547902 MirrorLeft2HeatCmd 3 "Take no action" 2 "Reserved" 1 "Mirror heat on" 0 "Mirror heat off" ;

VAL_ 2499547902 MirrorRight1HeatCmd 3 "Take no action" 2 "Reserved" 1 "Mirror heat on" 0 "Mirror heat off" ;

VAL_ 2499547902 MirrorLeft1HeatCmd 3 "Take no action" 2 "Reserved" 1 "Mirror heat on" 0 "Mirror heat off" ;

VAL_ 2499547902 MirrorRight2VerticalCmd 3 "Take no action" 2 "Reserved" 1 "Move down" 0 "Move up" ;

VAL_ 2499547902 MirrorRight2HorizontalCmd 3 "Take no action" 2 "Reserved" 1 "Move right" 0 "Move left" ;

VAL_ 2499547902 MirrorLeft2VerticalCmd 3 "Take no action" 2 "Reserved" 1 "Move down" 0 "Move up" ;

VAL_ 2499547902 MirrorLeft2HorizontalCmd 3 "Take no action" 2 "Reserved" 1 "Move right" 0 "Move left" ;

VAL_ 2499547902 MirrorRight1VerticalCmd 3 "Take no action" 2 "Reserved" 1 "Move down" 0 "Move up" ;

VAL_ 2499547902 MirrorRight1HorizontalCmd 3 "Take no action" 2 "Reserved" 1 "Move right" 0 "Move left" ;

VAL_ 2499547902 MirrorLeft1VerticalCmd 3 "Take no action" 2 "Reserved" 1 "Move down" 0 "Move up" ;

VAL_ 2499547902 MirrorLeft1HorizontalCmd 3 "Take no action" 2 "Reserved" 1 "Move right" 0 "Move left" ;

VAL_ 2499547902 RightRearWindowPosCmd 7 "Take no action" 6 "Reserved" 5 "Reserved" 4 "Reserved" 3 "Window auto down" 2 "Window auto up" 1 "Window move down" 0 "Window move up" ;

VAL_ 2499547902 LeftRearWindowPosCmd 7 "Take no action" 6 "Reserved" 5 "Reserved" 4 "Reserved" 3 "Window auto down" 2 "Window auto up" 1 "Window move down" 0 "Window move up" ;

VAL_ 2499547902 RightFrontWindowPosCmd 7 "Take no action" 6 "Reserved" 5 "Reserved" 4 "Reserved" 3 "Window auto down" 2 "Window auto up" 1 "Window move down" 0 "Window move up" ;

VAL_ 2499547902 LeftFrontWindowPosCmd 7 "Take no action" 6 "Reserved" 5 "Reserved" 4 "Reserved" 3 "Window auto down" 2 "Window auto up" 1 "Window move down" 0 "Window move up" ;

VAL_ 2499547902 RemoteCabDoorLockReq 7 "Take no action" 6 "Reserved" 5 "Request lock all cab door latches" 4 "Request unlock all cab door latches" 3 "Request unlock right rear cab door latch" 2 "Request unlock left rear cab door latch" 1 "Request unlock right front cab door latch" 0 "Request unlock left front cab door latch" ;

VAL_ 2499547902 DoorsLockActCmd 7 "Take no action" 6 "Reserved" 5 "Lock all cab door latches" 4 "Unlock all cab door latches" 3 "Unlock right rear cab door latch" 2 "Unlock left rear cab door latch" 1 "Unlock right front cab door latch" 0 "Unlock left front cab door latch" ;

VAL_ 2583177470 RainIntensity 7 "RAIN_NA" 6 "RAIN_Error" 5 "RAIN_Reserved2" 4 "RAIN_Reserved1" 3 "RAIN_High" 2 "RAIN_Medium" 1 "RAIN_Low" 0 "RAIN_Off" ;

VAL_ 2583175166 WipeArbRequest 7 "WPR_NA" 6 "WPR_Reserved" 5 "WPR_Auto" 4 "WPR_HighSpeed" 3 "WPR_LowSpeed" 2 "WPR_Intermittent" 1 "WPR_SingleStroke" 0 "WPR_TurnOff" ;

VAL_ 2364552702 ImmoState 3 "NA" 2 "Error" 1 "Unlocked" 0 "Locked" ;

VAL_ 2565865982 TrctrMntdTrailerABSWarningSignal 3 "Take no action" 2 "Reserved" 1 "On" 0 "Off" ;

VAL_ 2565865982 TrailerABSStatus 3 "Trailer ABS Status Information Not Available or Parameter Not Supported" 2 "Reserved" 1 "Trailer ABS Active" 0 "Trailer ABS Status Information Available But Not Active" ;

VAL_ 2565865982 HaltBrakeSwitch 3 "Not available" 2 "Error" 1 "Halt brake switch active" 0 "Halt brake switch passive" ;

VAL_ 2565865982 ATC_ASRInformationSignal 3 "Take no action" 2 "Reserved" 1 "On" 0 "Off" ;

VAL_ 2565865982 ABS_EBSAmberWarningSignal 3 "Take no action" 2 "Reserved" 1 "On" 0 "Off" ;

VAL_ 2565865982 EBSRedWarningSignal 3 "Take no action" 2 "Reserved" 1 "On" 0 "Off" ;

VAL_ 2565865982 ABSFullyOperational 3 "Not available" 2 "Reserved" 1 "Fully Operational" 0 "Not Fully Operational" ;

VAL_ 2565865982 RemoteAccelEnableSwitch 3 "Not available" 2 "Error" 1 "On" 0 "Off" ;

VAL_ 2565865982 EngAuxShutdownSwitch 3 "Not available" 2 "Error" 1 "On" 0 "Off" ;

VAL_ 2565865982 EngDerateSwitch 3 "Not available" 2 "Error" 1 "On" 0 "Off" ;

VAL_ 2565865982 AccelInterlockSwitch 3 "Not available" 2 "Error" 1 "On" 0 "Off" ;

VAL_ 2565865982 TractionCtrlOverrideSwitch 3 "Not available or not installed" 2 "Error" 1 "On" 0 "Off" ;

VAL_ 2565865982 ASRHillHolderSwitch 3 "Not available" 2 "Error" 1 "ASR 'hill holder' switch active" 0 "ASR 'hill holder' switch passive" ;

VAL_ 2565865982 ASROffroadSwitch 3 "Not available" 2 "Error" 1 "ASR off-road switch active" 0 "ASR off-road switch passive" ;

VAL_ 2565865982 ABSOffroadSwitch 3 "Not available" 2 "Error" 1 "ABS off-road switch active" 0 "ABS off-road switch passive" ;

VAL_ 2565865982 EBSBrakeSwitch 3 "Not available" 2 "Error" 1 "Brake pedal is being pressed" 0 "Brake pedal is not being pressed" ;

VAL_ 2565865982 AntiLockBrakingActive 3 "Not available" 2 "Reserved" 1 "ABS active" 0 "ABS passive but installed" ;

VAL_ 2565865982 ASRBrakeCtrlActive 3 "Not available" 2 "Reserved" 1 "ASR brake control active" 0 "ASR brake control passive but installed" ;

VAL_ 2565865982 ASREngCtrlActive 3 "Not available" 2 "Reserved" 1 "ASR engine control active" 0 "ASR engine control passive but installed" ;

VAL_ 2583176190 SigSeatSt 3 "NA" 2 "Error" 1 "Occpd" 0 "Free" ;

VAL_ 2381731326 TouchFailState 7 "Not Available" 6 "Error" 5 "Reserved" 4 "Reserved" 3 "Reserved" 2 "Failed On Touch" 1 "Failed" 0 "Not Failed" ;

VAL_ 2381731326 TouchEvent 7 "Not Available" 6 "Error" 5 "Reserved" 4 "Reserved" 3 "Double Press" 2 "Pressed" 1 "Unpressed" 0 "Off" ;

VAL_ 2566848826 Defrost_Act_Stall 1 "Stalled" 0 "Normal" ;

VAL_ 2566848826 Defrost_Act_Voltage 2 "UnderVoltage" 1 "OverVoltage" 0 "Normal" ;

VAL_ 2566848826 Defrost_Act_Temp 1 "OverHeated" 0 "Normal" ;

VAL_ 2566848826 Defrost_Act_Response 1 "Error" 0 "Normal" ;

VAL_ 2566848826 Addressing_Status 1 "Addressing" 0 "Not Addressing" ;

VAL_ 2566848826 Face_Act_Stall 1 "Stalled" 0 "Normal" ;

VAL_ 2566848826 Face_Act_Voltage 2 "UnderVoltage" 1 "OverVoltage" 0 "Normal" ;

VAL_ 2566848826 Face_Act_Temp 1 "OverHeated" 0 "Normal" ;

VAL_ 2566848826 Face_Act_Response 1 "Error" 0 "Normal" ;

VAL_ 2566848826 Calibration_Status 1 "Calibrating" 0 "Not Calibrating" ;

VAL_ 2566848826 Foot_Act_Stall 1 "Stalled" 0 "Normal" ;

VAL_ 2566848826 Foot_Act_Voltage 2 "UnderVoltage" 1 "OverVoltage" 0 "Normal" ;

VAL_ 2566848826 Foot_Act_Temp 1 "OverHeated" 0 "Normal" ;

VAL_ 2566848826 Foot_Act_Response 1 "Error" 0 "Normal" ;

VAL_ 2566848826 AirDirectionMode 4 "Screen" 3 "Floor/Screen" 2 "Floor" 1 "Face/Floor" 0 "Face" ;

VAL_ 2566848826 RecircActStall 1 "Stalled" 0 "Normal" ;

VAL_ 2566848826 RecircActVoltage 2 "UnderVoltage" 1 "OverVoltage" 0 "Normal" ;

VAL_ 2566848826 RecircActTemp 1 "OverHeated" 0 "Normal" ;

VAL_ 2566848826 RecircActResponse 1 "Error" 0 "Normal" ;

VAL_ 2566848826 RecircMode 0 "Recirc" 1 "Fresh" ;

VAL_ 2565814823 AirDirectionMode 4 "Screen" 3 "Floor/Screen" 2 "Floor" 1 "Face/Floor" 0 "Face" ;

VAL_ 2565814823 RecircMode 0 "Recirc" 1 "Fresh" ;

VAL_ 2515942398 UserSaloonClimateRequest 7 "NotAvailable" 3 "Standby" 2 "Demist" 1 "Auto" 0 "Ventilation" ;

VAL_ 2515942398 UserDemistRequest 3 "NA" 1 "ON" 0 "OFF" ;

VAL_ 2515942398 UserClimateControlEnable 3 "NA" 1 "Enabled" 0 "Disabled" ;

VAL_ 2515942398 UserCabinAirflowRequest 7 "NotAvailable" 2 "Auto" 1 "Max" 0 "Min" ;

VAL_ 2515942398 UserCabinClimateRequest 7 "NotAvailable" 3 "Standby" 2 "Demist" 1 "Auto" 0 "Ventilation" ;

VAL_ 2515942398 UserCabinRecirculationRequest 2 "AUTO" 3 "NOT AVAILABLE" 1 "CLOSE" 0 "OPEN" ;

VAL_ 2515942398 HMIDirectionRequest 7 "NA" 5 "Auto" 4 "Windscreen/Floor" 3 "Front/Floor" 2 "Floor" 1 "Front" 0 "Windscreen" ;

VAL_ 2515949566 OutletSelectionState 9 "Error" 6 "NA" 5 "Auto" 4 "Demist" 3 "Demist/Feet" 2 "Feet" 1 "Face/Feet" 0 "Face" ;

VAL_ 2515949566 DemistRequestState 9 "Error" 2 "NA" 1 "Enabled" 0 "Disabled" ;

VAL_ 2515949566 ClimateControlEnableState 9 "Error" 2 "NA" 1 "Enabled" 0 "Disabled" ;

VAL_ 2515949566 BlowerSpeedRequestState 9 "Error" 3 "NA" 2 "auto" 1 "high_speed" 0 "low_speed" ;

VAL_ 2515949566 CirculationRequestState 9 "Error" 3 "NA" 2 "Fresh" 1 "Full_recirc" 0 "Auto" ;

VAL_ 2515942142 AirflowDirectionRequest 7 "NotAvailable" 4 "Windscreen" 2 "Floor" 3 "Windscreen/Floor" 1 "Front/Floor" 0 "Front" ;

VAL_ 2515942142 HVACMalfunctionSaloon 3 "NotAvailable" 1 "Fault" 0 "NoFault" ;

VAL_ 2515942142 HVACMalfunctionCabin 3 "NotAvailable" 1 "Fault" 0 "NoFault" ;

VAL_ 2515942142 RecirculationRequest 3 "NotAvailable" 1 "On" 0 "Off" ;

VAL_ 2515942142 HVACModeSaloon 7 "NotAvailable" 3 "Standby" 2 "Cooling" 1 "Heating" 0 "Ventilation" ;

VAL_ 2515942142 HVACModeCabin 4 "Ventilation" 7 "NotAvailable" 3 "Demist" 2 "Heating" 1 "Cooling" 0 "Standby" ;

VAL_ 2515942142 ClimateModeSaloon 4 "Reserved" 7 "NotAvailable" 3 "Standby" 2 "Demist" 1 "Auto" 0 "Ventilation" ;

VAL_ 2515942142 ClimateModeCabin 4 "Reserved" 7 "NotAvailable" 3 "Standby" 2 "Demist" 1 "Auto" 0 "Ventilation" ;

VAL_ 2516060670 paEnableReq 2 "NotAvailable" 1 "Requested" 0 "NotRequested" ;

VAL_ 2516060670 paAutoReq 2 "NotAvailable" 1 "Requested" 0 "NotRequested" ;

VAL_ 513 SensorFSL_Echo1Height 0 "ulsEchoHei_Ukwn" 1 "ulsEchoHei_Lo" 2 "ulsEchoHei_Hi" 3 "ulsEchoHei_Ini" ;

VAL_ 513 SensorFSL_SignalWayId 0 "ulsSignalWayId_FSLtoFSL" 1 "ulsSignalWayId_FOLtoFSL" 2 "ulsSignalWayId_FSLtoFOL" 3 "ulsSignalWayId_FOLtoFOL" 4 "ulsSignalWayId_FILtoFOL" 5 "ulsSignalWayId_FOLtoFIL" 6 "ulsSignalWayId_FILtoFIL" 7 "ulsSignalWayId_FIRtoFIL" 8 "ulsSignalWayId_FILtoFIR" 9 "ulsSignalWayId_FIRtoFIR" 10 "ulsSignalWayId_FORtoFIR" 11 "ulsSignalWayId_FIRtoFOR" 12 "ulsSignalWayId_FORtoFOR" 13 "ulsSignalWayId_FSRtoFOR" 14 "ulsSignalWayId_FORtoFSR" 15 "ulsSignalWayId_FSRtoFSR" 16 "ulsSignalWayId_FCRtoFSR" 17 "ulsSignalWayId_FSRtoFCR" 18 "ulsSignalWayId_FCRtoFCR" 19 "ulsSignalWayId_RCRtoFCR" 20 "ulsSignalWayId_FCRtoRCR" 21 "ulsSignalWayId_RCRtoRCR" 22 "ulsSignalWayId_RSRtoRCR" 23 "ulsSignalWayId_RCRtoRSR" 24 "ulsSignalWayId_RSRtoRSR" 25 "ulsSignalWayId_RORtoRSR" 26 "ulsSignalWayId_RSRtoROR" 27 "ulsSignalWayId_RORtoROR" 28 "ulsSignalWayId_RIRtoROR" 29 "ulsSignalWayId_RORtoRIR" 30 "ulsSignalWayId_RIRtoRIR" 31 "ulsSignalWayId_RILtoRIR" 32 "ulsSignalWayId_RIRtoRIL" 33 "ulsSignalWayId_RILtoRIL" 34 "ulsSignalWayId_ROLtoRIL" 35 "ulsSignalWayId_RILtoROL" 36 "ulsSignalWayId_ROLtoROL" 37 "ulsSignalWayId_RSLtoROL" 38 "ulsSignalWayId_ROLtoRSL" 39 "ulsSignalWayId_RSLtoRSL" 40 "ulsSignalWayId_RCLtoRSL" 41 "ulsSignalWayId_RSLtoRCL" 42 "ulsSignalWayId_RCLtoRCL" 43 "ulsSignalWayId_FCLtoRCL" 44 "ulsSignalWayId_RCLtoFCL" 45 "ulsSignalWayId_FCLtoFCL" 46 "ulsSignalWayId_FSLtoFCL" 47 "ulsSignalWayId_FCLtoFSL" 48 "ulsSignalWayId_reserved1" 49 "ulsSignalWayId_reserved2" 50 "ulsSignalWayId_reserved3" 51 "ulsSignalWayId_reserved4" 52 "ulsSignalWayId_reserved5" 53 "ulsSignalWayId_reserved6" 54 "ulsSignalWayId_reserved7" 55 "ulsSignalWayId_reserved8" 56 "ulsSignalWayId_reserved9" 57 "ulsSignalWayId_reserved10" 58 "ulsSignalWayId_reserved11" 59 "ulsSignalWayId_reserved12" 255 "ulsSignalWayId_Undefind" ;

VAL_ 545 SensorRSL_Echo1Height 0 "ulsEchoHei_Ukwn" 1 "ulsEchoHei_Lo" 2 "ulsEchoHei_Hi" 3 "ulsEchoHei_Ini" ;

VAL_ 545 SensorRSL_SignalWayId 0 "ulsSignalWayId_FSLtoFSL" 1 "ulsSignalWayId_FOLtoFSL" 2 "ulsSignalWayId_FSLtoFOL" 3 "ulsSignalWayId_FOLtoFOL" 4 "ulsSignalWayId_FILtoFOL" 5 "ulsSignalWayId_FOLtoFIL" 6 "ulsSignalWayId_FILtoFIL" 7 "ulsSignalWayId_FIRtoFIL" 8 "ulsSignalWayId_FILtoFIR" 9 "ulsSignalWayId_FIRtoFIR" 10 "ulsSignalWayId_FORtoFIR" 11 "ulsSignalWayId_FIRtoFOR" 12 "ulsSignalWayId_FORtoFOR" 13 "ulsSignalWayId_FSRtoFOR" 14 "ulsSignalWayId_FORtoFSR" 15 "ulsSignalWayId_FSRtoFSR" 16 "ulsSignalWayId_FCRtoFSR" 17 "ulsSignalWayId_FSRtoFCR" 18 "ulsSignalWayId_FCRtoFCR" 19 "ulsSignalWayId_RCRtoFCR" 20 "ulsSignalWayId_FCRtoRCR" 21 "ulsSignalWayId_RCRtoRCR" 22 "ulsSignalWayId_RSRtoRCR" 23 "ulsSignalWayId_RCRtoRSR" 24 "ulsSignalWayId_RSRtoRSR" 25 "ulsSignalWayId_RORtoRSR" 26 "ulsSignalWayId_RSRtoROR" 27 "ulsSignalWayId_RORtoROR" 28 "ulsSignalWayId_RIRtoROR" 29 "ulsSignalWayId_RORtoRIR" 30 "ulsSignalWayId_RIRtoRIR" 31 "ulsSignalWayId_RILtoRIR" 32 "ulsSignalWayId_RIRtoRIL" 33 "ulsSignalWayId_RILtoRIL" 34 "ulsSignalWayId_ROLtoRIL" 35 "ulsSignalWayId_RILtoROL" 36 "ulsSignalWayId_ROLtoROL" 37 "ulsSignalWayId_RSLtoROL" 38 "ulsSignalWayId_ROLtoRSL" 39 "ulsSignalWayId_RSLtoRSL" 40 "ulsSignalWayId_RCLtoRSL" 41 "ulsSignalWayId_RSLtoRCL" 42 "ulsSignalWayId_RCLtoRCL" 43 "ulsSignalWayId_FCLtoRCL" 44 "ulsSignalWayId_RCLtoFCL" 45 "ulsSignalWayId_FCLtoFCL" 46 "ulsSignalWayId_FSLtoFCL" 47 "ulsSignalWayId_FCLtoFSL" 48 "ulsSignalWayId_reserved1" 49 "ulsSignalWayId_reserved2" 50 "ulsSignalWayId_reserved3" 51 "ulsSignalWayId_reserved4" 52 "ulsSignalWayId_reserved5" 53 "ulsSignalWayId_reserved6" 54 "ulsSignalWayId_reserved7" 55 "ulsSignalWayId_reserved8" 56 "ulsSignalWayId_reserved9" 57 "ulsSignalWayId_reserved10" 58 "ulsSignalWayId_reserved11" 59 "ulsSignalWayId_reserved12" 255 "ulsSignalWayId_Undefind" ;

VAL_ 533 SensorFSR_Echo1Height 0 "ulsEchoHei_Ukwn" 1 "ulsEchoHei_Lo" 2 "ulsEchoHei_Hi" 3 "ulsEchoHei_Ini" ;

VAL_ 533 SensorFSR_SignalWayId 0 "ulsSignalWayId_FSLtoFSL" 1 "ulsSignalWayId_FOLtoFSL" 2 "ulsSignalWayId_FSLtoFOL" 3 "ulsSignalWayId_FOLtoFOL" 4 "ulsSignalWayId_FILtoFOL" 5 "ulsSignalWayId_FOLtoFIL" 6 "ulsSignalWayId_FILtoFIL" 7 "ulsSignalWayId_FIRtoFIL" 8 "ulsSignalWayId_FILtoFIR" 9 "ulsSignalWayId_FIRtoFIR" 10 "ulsSignalWayId_FORtoFIR" 11 "ulsSignalWayId_FIRtoFOR" 12 "ulsSignalWayId_FORtoFOR" 13 "ulsSignalWayId_FSRtoFOR" 14 "ulsSignalWayId_FORtoFSR" 15 "ulsSignalWayId_FSRtoFSR" 16 "ulsSignalWayId_FCRtoFSR" 17 "ulsSignalWayId_FSRtoFCR" 18 "ulsSignalWayId_FCRtoFCR" 19 "ulsSignalWayId_RCRtoFCR" 20 "ulsSignalWayId_FCRtoRCR" 21 "ulsSignalWayId_RCRtoRCR" 22 "ulsSignalWayId_RSRtoRCR" 23 "ulsSignalWayId_RCRtoRSR" 24 "ulsSignalWayId_RSRtoRSR" 25 "ulsSignalWayId_RORtoRSR" 26 "ulsSignalWayId_RSRtoROR" 27 "ulsSignalWayId_RORtoROR" 28 "ulsSignalWayId_RIRtoROR" 29 "ulsSignalWayId_RORtoRIR" 30 "ulsSignalWayId_RIRtoRIR" 31 "ulsSignalWayId_RILtoRIR" 32 "ulsSignalWayId_RIRtoRIL" 33 "ulsSignalWayId_RILtoRIL" 34 "ulsSignalWayId_ROLtoRIL" 35 "ulsSignalWayId_RILtoROL" 36 "ulsSignalWayId_ROLtoROL" 37 "ulsSignalWayId_RSLtoROL" 38 "ulsSignalWayId_ROLtoRSL" 39 "ulsSignalWayId_RSLtoRSL" 40 "ulsSignalWayId_RCLtoRSL" 41 "ulsSignalWayId_RSLtoRCL" 42 "ulsSignalWayId_RCLtoRCL" 43 "ulsSignalWayId_FCLtoRCL" 44 "ulsSignalWayId_RCLtoFCL" 45 "ulsSignalWayId_FCLtoFCL" 46 "ulsSignalWayId_FSLtoFCL" 47 "ulsSignalWayId_FCLtoFSL" 48 "ulsSignalWayId_reserved1" 49 "ulsSignalWayId_reserved2" 50 "ulsSignalWayId_reserved3" 51 "ulsSignalWayId_reserved4" 52 "ulsSignalWayId_reserved5" 53 "ulsSignalWayId_reserved6" 54 "ulsSignalWayId_reserved7" 55 "ulsSignalWayId_reserved8" 56 "ulsSignalWayId_reserved9" 57 "ulsSignalWayId_reserved10" 58 "ulsSignalWayId_reserved11" 59 "ulsSignalWayId_reserved12" 255 "ulsSignalWayId_Undefind" ;

VAL_ 565 SensorRSR_Echo1Height 0 "ulsEchoHei_Ukwn" 1 "ulsEchoHei_Lo" 2 "ulsEchoHei_Hi" 3 "ulsEchoHei_Ini" ;

VAL_ 565 SensorRSR_SignalWayId 0 "ulsSignalWayId_FSLtoFSL" 1 "ulsSignalWayId_FOLtoFSL" 2 "ulsSignalWayId_FSLtoFOL" 3 "ulsSignalWayId_FOLtoFOL" 4 "ulsSignalWayId_FILtoFOL" 5 "ulsSignalWayId_FOLtoFIL" 6 "ulsSignalWayId_FILtoFIL" 7 "ulsSignalWayId_FIRtoFIL" 8 "ulsSignalWayId_FILtoFIR" 9 "ulsSignalWayId_FIRtoFIR" 10 "ulsSignalWayId_FORtoFIR" 11 "ulsSignalWayId_FIRtoFOR" 12 "ulsSignalWayId_FORtoFOR" 13 "ulsSignalWayId_FSRtoFOR" 14 "ulsSignalWayId_FORtoFSR" 15 "ulsSignalWayId_FSRtoFSR" 16 "ulsSignalWayId_FCRtoFSR" 17 "ulsSignalWayId_FSRtoFCR" 18 "ulsSignalWayId_FCRtoFCR" 19 "ulsSignalWayId_RCRtoFCR" 20 "ulsSignalWayId_FCRtoRCR" 21 "ulsSignalWayId_RCRtoRCR" 22 "ulsSignalWayId_RSRtoRCR" 23 "ulsSignalWayId_RCRtoRSR" 24 "ulsSignalWayId_RSRtoRSR" 25 "ulsSignalWayId_RORtoRSR" 26 "ulsSignalWayId_RSRtoROR" 27 "ulsSignalWayId_RORtoROR" 28 "ulsSignalWayId_RIRtoROR" 29 "ulsSignalWayId_RORtoRIR" 30 "ulsSignalWayId_RIRtoRIR" 31 "ulsSignalWayId_RILtoRIR" 32 "ulsSignalWayId_RIRtoRIL" 33 "ulsSignalWayId_RILtoRIL" 34 "ulsSignalWayId_ROLtoRIL" 35 "ulsSignalWayId_RILtoROL" 36 "ulsSignalWayId_ROLtoROL" 37 "ulsSignalWayId_RSLtoROL" 38 "ulsSignalWayId_ROLtoRSL" 39 "ulsSignalWayId_RSLtoRSL" 40 "ulsSignalWayId_RCLtoRSL" 41 "ulsSignalWayId_RSLtoRCL" 42 "ulsSignalWayId_RCLtoRCL" 43 "ulsSignalWayId_FCLtoRCL" 44 "ulsSignalWayId_RCLtoFCL" 45 "ulsSignalWayId_FCLtoFCL" 46 "ulsSignalWayId_FSLtoFCL" 47 "ulsSignalWayId_FCLtoFSL" 48 "ulsSignalWayId_reserved1" 49 "ulsSignalWayId_reserved2" 50 "ulsSignalWayId_reserved3" 51 "ulsSignalWayId_reserved4" 52 "ulsSignalWayId_reserved5" 53 "ulsSignalWayId_reserved6" 54 "ulsSignalWayId_reserved7" 55 "ulsSignalWayId_reserved8" 56 "ulsSignalWayId_reserved9" 57 "ulsSignalWayId_reserved10" 58 "ulsSignalWayId_reserved11" 59 "ulsSignalWayId_reserved12" 255 "ulsSignalWayId_Undefind" ;

VAL_ 517 SensorFOL_Echo1Height 0 "ulsEchoHei_Ukwn" 1 "ulsEchoHei_Lo" 2 "ulsEchoHei_Hi" 3 "ulsEchoHei_Ini" ;

VAL_ 517 SensorFOL_SignalWayId 0 "ulsSignalWayId_FSLtoFSL" 1 "ulsSignalWayId_FOLtoFSL" 2 "ulsSignalWayId_FSLtoFOL" 3 "ulsSignalWayId_FOLtoFOL" 4 "ulsSignalWayId_FILtoFOL" 5 "ulsSignalWayId_FOLtoFIL" 6 "ulsSignalWayId_FILtoFIL" 7 "ulsSignalWayId_FIRtoFIL" 8 "ulsSignalWayId_FILtoFIR" 9 "ulsSignalWayId_FIRtoFIR" 10 "ulsSignalWayId_FORtoFIR" 11 "ulsSignalWayId_FIRtoFOR" 12 "ulsSignalWayId_FORtoFOR" 13 "ulsSignalWayId_FSRtoFOR" 14 "ulsSignalWayId_FORtoFSR" 15 "ulsSignalWayId_FSRtoFSR" 16 "ulsSignalWayId_FCRtoFSR" 17 "ulsSignalWayId_FSRtoFCR" 18 "ulsSignalWayId_FCRtoFCR" 19 "ulsSignalWayId_RCRtoFCR" 20 "ulsSignalWayId_FCRtoRCR" 21 "ulsSignalWayId_RCRtoRCR" 22 "ulsSignalWayId_RSRtoRCR" 23 "ulsSignalWayId_RCRtoRSR" 24 "ulsSignalWayId_RSRtoRSR" 25 "ulsSignalWayId_RORtoRSR" 26 "ulsSignalWayId_RSRtoROR" 27 "ulsSignalWayId_RORtoROR" 28 "ulsSignalWayId_RIRtoROR" 29 "ulsSignalWayId_RORtoRIR" 30 "ulsSignalWayId_RIRtoRIR" 31 "ulsSignalWayId_RILtoRIR" 32 "ulsSignalWayId_RIRtoRIL" 33 "ulsSignalWayId_RILtoRIL" 34 "ulsSignalWayId_ROLtoRIL" 35 "ulsSignalWayId_RILtoROL" 36 "ulsSignalWayId_ROLtoROL" 37 "ulsSignalWayId_RSLtoROL" 38 "ulsSignalWayId_ROLtoRSL" 39 "ulsSignalWayId_RSLtoRSL" 40 "ulsSignalWayId_RCLtoRSL" 41 "ulsSignalWayId_RSLtoRCL" 42 "ulsSignalWayId_RCLtoRCL" 43 "ulsSignalWayId_FCLtoRCL" 44 "ulsSignalWayId_RCLtoFCL" 45 "ulsSignalWayId_FCLtoFCL" 46 "ulsSignalWayId_FSLtoFCL" 47 "ulsSignalWayId_FCLtoFSL" 48 "ulsSignalWayId_reserved1" 49 "ulsSignalWayId_reserved2" 50 "ulsSignalWayId_reserved3" 51 "ulsSignalWayId_reserved4" 52 "ulsSignalWayId_reserved5" 53 "ulsSignalWayId_reserved6" 54 "ulsSignalWayId_reserved7" 55 "ulsSignalWayId_reserved8" 56 "ulsSignalWayId_reserved9" 57 "ulsSignalWayId_reserved10" 58 "ulsSignalWayId_reserved11" 59 "ulsSignalWayId_reserved12" 255 "ulsSignalWayId_Undefind" ;

VAL_ 549 SensorROL_Echo1Height 0 "ulsEchoHei_Ukwn" 1 "ulsEchoHei_Lo" 2 "ulsEchoHei_Hi" 3 "ulsEchoHei_Ini" ;

VAL_ 549 SensorROL_SignalWayId 0 "ulsSignalWayId_FSLtoFSL" 1 "ulsSignalWayId_FOLtoFSL" 2 "ulsSignalWayId_FSLtoFOL" 3 "ulsSignalWayId_FOLtoFOL" 4 "ulsSignalWayId_FILtoFOL" 5 "ulsSignalWayId_FOLtoFIL" 6 "ulsSignalWayId_FILtoFIL" 7 "ulsSignalWayId_FIRtoFIL" 8 "ulsSignalWayId_FILtoFIR" 9 "ulsSignalWayId_FIRtoFIR" 10 "ulsSignalWayId_FORtoFIR" 11 "ulsSignalWayId_FIRtoFOR" 12 "ulsSignalWayId_FORtoFOR" 13 "ulsSignalWayId_FSRtoFOR" 14 "ulsSignalWayId_FORtoFSR" 15 "ulsSignalWayId_FSRtoFSR" 16 "ulsSignalWayId_FCRtoFSR" 17 "ulsSignalWayId_FSRtoFCR" 18 "ulsSignalWayId_FCRtoFCR" 19 "ulsSignalWayId_RCRtoFCR" 20 "ulsSignalWayId_FCRtoRCR" 21 "ulsSignalWayId_RCRtoRCR" 22 "ulsSignalWayId_RSRtoRCR" 23 "ulsSignalWayId_RCRtoRSR" 24 "ulsSignalWayId_RSRtoRSR" 25 "ulsSignalWayId_RORtoRSR" 26 "ulsSignalWayId_RSRtoROR" 27 "ulsSignalWayId_RORtoROR" 28 "ulsSignalWayId_RIRtoROR" 29 "ulsSignalWayId_RORtoRIR" 30 "ulsSignalWayId_RIRtoRIR" 31 "ulsSignalWayId_RILtoRIR" 32 "ulsSignalWayId_RIRtoRIL" 33 "ulsSignalWayId_RILtoRIL" 34 "ulsSignalWayId_ROLtoRIL" 35 "ulsSignalWayId_RILtoROL" 36 "ulsSignalWayId_ROLtoROL" 37 "ulsSignalWayId_RSLtoROL" 38 "ulsSignalWayId_ROLtoRSL" 39 "ulsSignalWayId_RSLtoRSL" 40 "ulsSignalWayId_RCLtoRSL" 41 "ulsSignalWayId_RSLtoRCL" 42 "ulsSignalWayId_RCLtoRCL" 43 "ulsSignalWayId_FCLtoRCL" 44 "ulsSignalWayId_RCLtoFCL" 45 "ulsSignalWayId_FCLtoFCL" 46 "ulsSignalWayId_FSLtoFCL" 47 "ulsSignalWayId_FCLtoFSL" 48 "ulsSignalWayId_reserved1" 49 "ulsSignalWayId_reserved2" 50 "ulsSignalWayId_reserved3" 51 "ulsSignalWayId_reserved4" 52 "ulsSignalWayId_reserved5" 53 "ulsSignalWayId_reserved6" 54 "ulsSignalWayId_reserved7" 55 "ulsSignalWayId_reserved8" 56 "ulsSignalWayId_reserved9" 57 "ulsSignalWayId_reserved10" 58 "ulsSignalWayId_reserved11" 59 "ulsSignalWayId_reserved12" 255 "ulsSignalWayId_Undefind" ;

VAL_ 521 SensorFIL_Echo1Height 0 "ulsEchoHei_Ukwn" 1 "ulsEchoHei_Lo" 2 "ulsEchoHei_Hi" 3 "ulsEchoHei_Ini" ;

VAL_ 521 SensorFIL_SignalWayId 0 "ulsSignalWayId_FSLtoFSL" 1 "ulsSignalWayId_FOLtoFSL" 2 "ulsSignalWayId_FSLtoFOL" 3 "ulsSignalWayId_FOLtoFOL" 4 "ulsSignalWayId_FILtoFOL" 5 "ulsSignalWayId_FOLtoFIL" 6 "ulsSignalWayId_FILtoFIL" 7 "ulsSignalWayId_FIRtoFIL" 8 "ulsSignalWayId_FILtoFIR" 9 "ulsSignalWayId_FIRtoFIR" 10 "ulsSignalWayId_FORtoFIR" 11 "ulsSignalWayId_FIRtoFOR" 12 "ulsSignalWayId_FORtoFOR" 13 "ulsSignalWayId_FSRtoFOR" 14 "ulsSignalWayId_FORtoFSR" 15 "ulsSignalWayId_FSRtoFSR" 16 "ulsSignalWayId_FCRtoFSR" 17 "ulsSignalWayId_FSRtoFCR" 18 "ulsSignalWayId_FCRtoFCR" 19 "ulsSignalWayId_RCRtoFCR" 20 "ulsSignalWayId_FCRtoRCR" 21 "ulsSignalWayId_RCRtoRCR" 22 "ulsSignalWayId_RSRtoRCR" 23 "ulsSignalWayId_RCRtoRSR" 24 "ulsSignalWayId_RSRtoRSR" 25 "ulsSignalWayId_RORtoRSR" 26 "ulsSignalWayId_RSRtoROR" 27 "ulsSignalWayId_RORtoROR" 28 "ulsSignalWayId_RIRtoROR" 29 "ulsSignalWayId_RORtoRIR" 30 "ulsSignalWayId_RIRtoRIR" 31 "ulsSignalWayId_RILtoRIR" 32 "ulsSignalWayId_RIRtoRIL" 33 "ulsSignalWayId_RILtoRIL" 34 "ulsSignalWayId_ROLtoRIL" 35 "ulsSignalWayId_RILtoROL" 36 "ulsSignalWayId_ROLtoROL" 37 "ulsSignalWayId_RSLtoROL" 38 "ulsSignalWayId_ROLtoRSL" 39 "ulsSignalWayId_RSLtoRSL" 40 "ulsSignalWayId_RCLtoRSL" 41 "ulsSignalWayId_RSLtoRCL" 42 "ulsSignalWayId_RCLtoRCL" 43 "ulsSignalWayId_FCLtoRCL" 44 "ulsSignalWayId_RCLtoFCL" 45 "ulsSignalWayId_FCLtoFCL" 46 "ulsSignalWayId_FSLtoFCL" 47 "ulsSignalWayId_FCLtoFSL" 48 "ulsSignalWayId_reserved1" 49 "ulsSignalWayId_reserved2" 50 "ulsSignalWayId_reserved3" 51 "ulsSignalWayId_reserved4" 52 "ulsSignalWayId_reserved5" 53 "ulsSignalWayId_reserved6" 54 "ulsSignalWayId_reserved7" 55 "ulsSignalWayId_reserved8" 56 "ulsSignalWayId_reserved9" 57 "ulsSignalWayId_reserved10" 58 "ulsSignalWayId_reserved11" 59 "ulsSignalWayId_reserved12" 255 "ulsSignalWayId_Undefind" ;

VAL_ 553 SensorRIL_Echo1Height 0 "ulsEchoHei_Ukwn" 1 "ulsEchoHei_Lo" 2 "ulsEchoHei_Hi" 3 "ulsEchoHei_Ini" ;

VAL_ 553 SensorRIL_SignalWayId 0 "ulsSignalWayId_FSLtoFSL" 1 "ulsSignalWayId_FOLtoFSL" 2 "ulsSignalWayId_FSLtoFOL" 3 "ulsSignalWayId_FOLtoFOL" 4 "ulsSignalWayId_FILtoFOL" 5 "ulsSignalWayId_FOLtoFIL" 6 "ulsSignalWayId_FILtoFIL" 7 "ulsSignalWayId_FIRtoFIL" 8 "ulsSignalWayId_FILtoFIR" 9 "ulsSignalWayId_FIRtoFIR" 10 "ulsSignalWayId_FORtoFIR" 11 "ulsSignalWayId_FIRtoFOR" 12 "ulsSignalWayId_FORtoFOR" 13 "ulsSignalWayId_FSRtoFOR" 14 "ulsSignalWayId_FORtoFSR" 15 "ulsSignalWayId_FSRtoFSR" 16 "ulsSignalWayId_FCRtoFSR" 17 "ulsSignalWayId_FSRtoFCR" 18 "ulsSignalWayId_FCRtoFCR" 19 "ulsSignalWayId_RCRtoFCR" 20 "ulsSignalWayId_FCRtoRCR" 21 "ulsSignalWayId_RCRtoRCR" 22 "ulsSignalWayId_RSRtoRCR" 23 "ulsSignalWayId_RCRtoRSR" 24 "ulsSignalWayId_RSRtoRSR" 25 "ulsSignalWayId_RORtoRSR" 26 "ulsSignalWayId_RSRtoROR" 27 "ulsSignalWayId_RORtoROR" 28 "ulsSignalWayId_RIRtoROR" 29 "ulsSignalWayId_RORtoRIR" 30 "ulsSignalWayId_RIRtoRIR" 31 "ulsSignalWayId_RILtoRIR" 32 "ulsSignalWayId_RIRtoRIL" 33 "ulsSignalWayId_RILtoRIL" 34 "ulsSignalWayId_ROLtoRIL" 35 "ulsSignalWayId_RILtoROL" 36 "ulsSignalWayId_ROLtoROL" 37 "ulsSignalWayId_RSLtoROL" 38 "ulsSignalWayId_ROLtoRSL" 39 "ulsSignalWayId_RSLtoRSL" 40 "ulsSignalWayId_RCLtoRSL" 41 "ulsSignalWayId_RSLtoRCL" 42 "ulsSignalWayId_RCLtoRCL" 43 "ulsSignalWayId_FCLtoRCL" 44 "ulsSignalWayId_RCLtoFCL" 45 "ulsSignalWayId_FCLtoFCL" 46 "ulsSignalWayId_FSLtoFCL" 47 "ulsSignalWayId_FCLtoFSL" 48 "ulsSignalWayId_reserved1" 49 "ulsSignalWayId_reserved2" 50 "ulsSignalWayId_reserved3" 51 "ulsSignalWayId_reserved4" 52 "ulsSignalWayId_reserved5" 53 "ulsSignalWayId_reserved6" 54 "ulsSignalWayId_reserved7" 55 "ulsSignalWayId_reserved8" 56 "ulsSignalWayId_reserved9" 57 "ulsSignalWayId_reserved10" 58 "ulsSignalWayId_reserved11" 59 "ulsSignalWayId_reserved12" 255 "ulsSignalWayId_Undefind" ;

VAL_ 525 SensorFIR_Echo1Height 0 "ulsEchoHei_Ukwn" 1 "ulsEchoHei_Lo" 2 "ulsEchoHei_Hi" 3 "ulsEchoHei_Ini" ;

VAL_ 525 SensorFIR_SignalWayId 0 "ulsSignalWayId_FSLtoFSL" 1 "ulsSignalWayId_FOLtoFSL" 2 "ulsSignalWayId_FSLtoFOL" 3 "ulsSignalWayId_FOLtoFOL" 4 "ulsSignalWayId_FILtoFOL" 5 "ulsSignalWayId_FOLtoFIL" 6 "ulsSignalWayId_FILtoFIL" 7 "ulsSignalWayId_FIRtoFIL" 8 "ulsSignalWayId_FILtoFIR" 9 "ulsSignalWayId_FIRtoFIR" 10 "ulsSignalWayId_FORtoFIR" 11 "ulsSignalWayId_FIRtoFOR" 12 "ulsSignalWayId_FORtoFOR" 13 "ulsSignalWayId_FSRtoFOR" 14 "ulsSignalWayId_FORtoFSR" 15 "ulsSignalWayId_FSRtoFSR" 16 "ulsSignalWayId_FCRtoFSR" 17 "ulsSignalWayId_FSRtoFCR" 18 "ulsSignalWayId_FCRtoFCR" 19 "ulsSignalWayId_RCRtoFCR" 20 "ulsSignalWayId_FCRtoRCR" 21 "ulsSignalWayId_RCRtoRCR" 22 "ulsSignalWayId_RSRtoRCR" 23 "ulsSignalWayId_RCRtoRSR" 24 "ulsSignalWayId_RSRtoRSR" 25 "ulsSignalWayId_RORtoRSR" 26 "ulsSignalWayId_RSRtoROR" 27 "ulsSignalWayId_RORtoROR" 28 "ulsSignalWayId_RIRtoROR" 29 "ulsSignalWayId_RORtoRIR" 30 "ulsSignalWayId_RIRtoRIR" 31 "ulsSignalWayId_RILtoRIR" 32 "ulsSignalWayId_RIRtoRIL" 33 "ulsSignalWayId_RILtoRIL" 34 "ulsSignalWayId_ROLtoRIL" 35 "ulsSignalWayId_RILtoROL" 36 "ulsSignalWayId_ROLtoROL" 37 "ulsSignalWayId_RSLtoROL" 38 "ulsSignalWayId_ROLtoRSL" 39 "ulsSignalWayId_RSLtoRSL" 40 "ulsSignalWayId_RCLtoRSL" 41 "ulsSignalWayId_RSLtoRCL" 42 "ulsSignalWayId_RCLtoRCL" 43 "ulsSignalWayId_FCLtoRCL" 44 "ulsSignalWayId_RCLtoFCL" 45 "ulsSignalWayId_FCLtoFCL" 46 "ulsSignalWayId_FSLtoFCL" 47 "ulsSignalWayId_FCLtoFSL" 48 "ulsSignalWayId_reserved1" 49 "ulsSignalWayId_reserved2" 50 "ulsSignalWayId_reserved3" 51 "ulsSignalWayId_reserved4" 52 "ulsSignalWayId_reserved5" 53 "ulsSignalWayId_reserved6" 54 "ulsSignalWayId_reserved7" 55 "ulsSignalWayId_reserved8" 56 "ulsSignalWayId_reserved9" 57 "ulsSignalWayId_reserved10" 58 "ulsSignalWayId_reserved11" 59 "ulsSignalWayId_reserved12" 255 "ulsSignalWayId_Undefind" ;

VAL_ 557 SensorRIR_Echo1Height 0 "ulsEchoHei_Ukwn" 1 "ulsEchoHei_Lo" 2 "ulsEchoHei_Hi" 3 "ulsEchoHei_Ini" ;

VAL_ 557 SensorRIR_SignalWayId 0 "ulsSignalWayId_FSLtoFSL" 1 "ulsSignalWayId_FOLtoFSL" 2 "ulsSignalWayId_FSLtoFOL" 3 "ulsSignalWayId_FOLtoFOL" 4 "ulsSignalWayId_FILtoFOL" 5 "ulsSignalWayId_FOLtoFIL" 6 "ulsSignalWayId_FILtoFIL" 7 "ulsSignalWayId_FIRtoFIL" 8 "ulsSignalWayId_FILtoFIR" 9 "ulsSignalWayId_FIRtoFIR" 10 "ulsSignalWayId_FORtoFIR" 11 "ulsSignalWayId_FIRtoFOR" 12 "ulsSignalWayId_FORtoFOR" 13 "ulsSignalWayId_FSRtoFOR" 14 "ulsSignalWayId_FORtoFSR" 15 "ulsSignalWayId_FSRtoFSR" 16 "ulsSignalWayId_FCRtoFSR" 17 "ulsSignalWayId_FSRtoFCR" 18 "ulsSignalWayId_FCRtoFCR" 19 "ulsSignalWayId_RCRtoFCR" 20 "ulsSignalWayId_FCRtoRCR" 21 "ulsSignalWayId_RCRtoRCR" 22 "ulsSignalWayId_RSRtoRCR" 23 "ulsSignalWayId_RCRtoRSR" 24 "ulsSignalWayId_RSRtoRSR" 25 "ulsSignalWayId_RORtoRSR" 26 "ulsSignalWayId_RSRtoROR" 27 "ulsSignalWayId_RORtoROR" 28 "ulsSignalWayId_RIRtoROR" 29 "ulsSignalWayId_RORtoRIR" 30 "ulsSignalWayId_RIRtoRIR" 31 "ulsSignalWayId_RILtoRIR" 32 "ulsSignalWayId_RIRtoRIL" 33 "ulsSignalWayId_RILtoRIL" 34 "ulsSignalWayId_ROLtoRIL" 35 "ulsSignalWayId_RILtoROL" 36 "ulsSignalWayId_ROLtoROL" 37 "ulsSignalWayId_RSLtoROL" 38 "ulsSignalWayId_ROLtoRSL" 39 "ulsSignalWayId_RSLtoRSL" 40 "ulsSignalWayId_RCLtoRSL" 41 "ulsSignalWayId_RSLtoRCL" 42 "ulsSignalWayId_RCLtoRCL" 43 "ulsSignalWayId_FCLtoRCL" 44 "ulsSignalWayId_RCLtoFCL" 45 "ulsSignalWayId_FCLtoFCL" 46 "ulsSignalWayId_FSLtoFCL" 47 "ulsSignalWayId_FCLtoFSL" 48 "ulsSignalWayId_reserved1" 49 "ulsSignalWayId_reserved2" 50 "ulsSignalWayId_reserved3" 51 "ulsSignalWayId_reserved4" 52 "ulsSignalWayId_reserved5" 53 "ulsSignalWayId_reserved6" 54 "ulsSignalWayId_reserved7" 55 "ulsSignalWayId_reserved8" 56 "ulsSignalWayId_reserved9" 57 "ulsSignalWayId_reserved10" 58 "ulsSignalWayId_reserved11" 59 "ulsSignalWayId_reserved12" 255 "ulsSignalWayId_Undefind" ;

VAL_ 529 SensorFOR_Echo1Height 0 "ulsEchoHei_Ukwn" 1 "ulsEchoHei_Lo" 2 "ulsEchoHei_Hi" 3 "ulsEchoHei_Ini" ;

VAL_ 529 SensorFOR_SignalWayId 0 "ulsSignalWayId_FSLtoFSL" 1 "ulsSignalWayId_FOLtoFSL" 2 "ulsSignalWayId_FSLtoFOL" 3 "ulsSignalWayId_FOLtoFOL" 4 "ulsSignalWayId_FILtoFOL" 5 "ulsSignalWayId_FOLtoFIL" 6 "ulsSignalWayId_FILtoFIL" 7 "ulsSignalWayId_FIRtoFIL" 8 "ulsSignalWayId_FILtoFIR" 9 "ulsSignalWayId_FIRtoFIR" 10 "ulsSignalWayId_FORtoFIR" 11 "ulsSignalWayId_FIRtoFOR" 12 "ulsSignalWayId_FORtoFOR" 13 "ulsSignalWayId_FSRtoFOR" 14 "ulsSignalWayId_FORtoFSR" 15 "ulsSignalWayId_FSRtoFSR" 16 "ulsSignalWayId_FCRtoFSR" 17 "ulsSignalWayId_FSRtoFCR" 18 "ulsSignalWayId_FCRtoFCR" 19 "ulsSignalWayId_RCRtoFCR" 20 "ulsSignalWayId_FCRtoRCR" 21 "ulsSignalWayId_RCRtoRCR" 22 "ulsSignalWayId_RSRtoRCR" 23 "ulsSignalWayId_RCRtoRSR" 24 "ulsSignalWayId_RSRtoRSR" 25 "ulsSignalWayId_RORtoRSR" 26 "ulsSignalWayId_RSRtoROR" 27 "ulsSignalWayId_RORtoROR" 28 "ulsSignalWayId_RIRtoROR" 29 "ulsSignalWayId_RORtoRIR" 30 "ulsSignalWayId_RIRtoRIR" 31 "ulsSignalWayId_RILtoRIR" 32 "ulsSignalWayId_RIRtoRIL" 33 "ulsSignalWayId_RILtoRIL" 34 "ulsSignalWayId_ROLtoRIL" 35 "ulsSignalWayId_RILtoROL" 36 "ulsSignalWayId_ROLtoROL" 37 "ulsSignalWayId_RSLtoROL" 38 "ulsSignalWayId_ROLtoRSL" 39 "ulsSignalWayId_RSLtoRSL" 40 "ulsSignalWayId_RCLtoRSL" 41 "ulsSignalWayId_RSLtoRCL" 42 "ulsSignalWayId_RCLtoRCL" 43 "ulsSignalWayId_FCLtoRCL" 44 "ulsSignalWayId_RCLtoFCL" 45 "ulsSignalWayId_FCLtoFCL" 46 "ulsSignalWayId_FSLtoFCL" 47 "ulsSignalWayId_FCLtoFSL" 48 "ulsSignalWayId_reserved1" 49 "ulsSignalWayId_reserved2" 50 "ulsSignalWayId_reserved3" 51 "ulsSignalWayId_reserved4" 52 "ulsSignalWayId_reserved5" 53 "ulsSignalWayId_reserved6" 54 "ulsSignalWayId_reserved7" 55 "ulsSignalWayId_reserved8" 56 "ulsSignalWayId_reserved9" 57 "ulsSignalWayId_reserved10" 58 "ulsSignalWayId_reserved11" 59 "ulsSignalWayId_reserved12" 255 "ulsSignalWayId_Undefind" ;

VAL_ 561 SensorROR_Echo1Height 0 "ulsEchoHei_Ukwn" 1 "ulsEchoHei_Lo" 2 "ulsEchoHei_Hi" 3 "ulsEchoHei_Ini" ;

VAL_ 561 SensorROR_SignalWayId 0 "ulsSignalWayId_FSLtoFSL" 1 "ulsSignalWayId_FOLtoFSL" 2 "ulsSignalWayId_FSLtoFOL" 3 "ulsSignalWayId_FOLtoFOL" 4 "ulsSignalWayId_FILtoFOL" 5 "ulsSignalWayId_FOLtoFIL" 6 "ulsSignalWayId_FILtoFIL" 7 "ulsSignalWayId_FIRtoFIL" 8 "ulsSignalWayId_FILtoFIR" 9 "ulsSignalWayId_FIRtoFIR" 10 "ulsSignalWayId_FORtoFIR" 11 "ulsSignalWayId_FIRtoFOR" 12 "ulsSignalWayId_FORtoFOR" 13 "ulsSignalWayId_FSRtoFOR" 14 "ulsSignalWayId_FORtoFSR" 15 "ulsSignalWayId_FSRtoFSR" 16 "ulsSignalWayId_FCRtoFSR" 17 "ulsSignalWayId_FSRtoFCR" 18 "ulsSignalWayId_FCRtoFCR" 19 "ulsSignalWayId_RCRtoFCR" 20 "ulsSignalWayId_FCRtoRCR" 21 "ulsSignalWayId_RCRtoRCR" 22 "ulsSignalWayId_RSRtoRCR" 23 "ulsSignalWayId_RCRtoRSR" 24 "ulsSignalWayId_RSRtoRSR" 25 "ulsSignalWayId_RORtoRSR" 26 "ulsSignalWayId_RSRtoROR" 27 "ulsSignalWayId_RORtoROR" 28 "ulsSignalWayId_RIRtoROR" 29 "ulsSignalWayId_RORtoRIR" 30 "ulsSignalWayId_RIRtoRIR" 31 "ulsSignalWayId_RILtoRIR" 32 "ulsSignalWayId_RIRtoRIL" 33 "ulsSignalWayId_RILtoRIL" 34 "ulsSignalWayId_ROLtoRIL" 35 "ulsSignalWayId_RILtoROL" 36 "ulsSignalWayId_ROLtoROL" 37 "ulsSignalWayId_RSLtoROL" 38 "ulsSignalWayId_ROLtoRSL" 39 "ulsSignalWayId_RSLtoRSL" 40 "ulsSignalWayId_RCLtoRSL" 41 "ulsSignalWayId_RSLtoRCL" 42 "ulsSignalWayId_RCLtoRCL" 43 "ulsSignalWayId_FCLtoRCL" 44 "ulsSignalWayId_RCLtoFCL" 45 "ulsSignalWayId_FCLtoFCL" 46 "ulsSignalWayId_FSLtoFCL" 47 "ulsSignalWayId_FCLtoFSL" 48 "ulsSignalWayId_reserved1" 49 "ulsSignalWayId_reserved2" 50 "ulsSignalWayId_reserved3" 51 "ulsSignalWayId_reserved4" 52 "ulsSignalWayId_reserved5" 53 "ulsSignalWayId_reserved6" 54 "ulsSignalWayId_reserved7" 55 "ulsSignalWayId_reserved8" 56 "ulsSignalWayId_reserved9" 57 "ulsSignalWayId_reserved10" 58 "ulsSignalWayId_reserved11" 59 "ulsSignalWayId_reserved12" 255 "ulsSignalWayId_Undefind" ;

VAL_ 2516060414 paStatus 3 "NotAvailable" 2 "Error" 1 "Active" 0 "NotActive" ;

VAL_ 2566803454 TrailerVDCActive 3 "Not availble or not installed" 2 "Reserved" 1 "VDC active" 0 "VDC passive" ;

VAL_ 2566803454 YCBrakeCtrlActive 3 "Don't care/Take no action" 2 "Reserved" 1 "YC brake control active" 0 "YC brake control passive but installed" ;

VAL_ 2566803454 YCEngCtrlActive 3 "Don't care/Take no action" 2 "Reserved" 1 "YC engine control active" 0 "YC engine control passive but installed" ;

VAL_ 2566803454 ROPBrakeCtrlActive 3 "Don't care/Take no action" 2 "Reserved" 1 "ROP brake control active" 0 "ROP brake control passive but installed" ;

VAL_ 2566803454 ROPEngCtrlActive 3 "Don't care/Take no action" 2 "Reserved" 1 "ROP engine control active" 0 "ROP engine control passive but installed" ;

VAL_ 2566803454 VDCBrakeLightRq 3 "Don't care/Take no action" 2 "Reserved" 1 "Turn brake light on" 0 "Turn brake light not on" ;

VAL_ 2566803454 VDCFullyOperational 3 "Don't care/Take no action" 2 "Reserved" 1 "Fully operational" 0 "Not fully operational" ;

VAL_ 2566803454 VDCInformationSignal 3 "Don't care/Take no action" 2 "Reserved" 1 "On" 0 "Off" ;

SIG_GROUP_ 513 SensorFSL_0 1 : SensorFSL_BlindDist SensorFSL_SignalWayId SensorFSL_Echo1Dist SensorFSL_Echo1NumDetn SensorFSL_Echo1Height SensorFSL_Echo2Dist;

SIG_GROUP_ 545 SensorRSL_0 1 : SensorRSL_BlindDist SensorRSL_SignalWayId SensorRSL_Echo1Dist SensorRSL_Echo1NumDetn SensorRSL_Echo1Height SensorRSL_Echo2Dist;

SIG_GROUP_ 533 SensorFSR_0 1 : SensorFSR_BlindDist SensorFSR_SignalWayId SensorFSR_Echo1Dist SensorFSR_Echo1NumDetn SensorFSR_Echo1Height SensorFSR_Echo2Dist;

SIG_GROUP_ 565 SensorRSR_0 1 : SensorRSR_BlindDist SensorRSR_SignalWayId SensorRSR_Echo1Dist SensorRSR_Echo1NumDetn SensorRSR_Echo1Height SensorRSR_Echo2Dist;

SIG_GROUP_ 517 SensorFOL_0 1 : SensorFOL_BlindDist SensorFOL_SignalWayId SensorFOL_Echo1Dist SensorFOL_Echo1NumDetn SensorFOL_Echo1Height SensorFOL_Echo2Dist;

SIG_GROUP_ 549 SensorROL_0 1 : SensorROL_BlindDist SensorROL_SignalWayId SensorROL_Echo1Dist SensorROL_Echo1NumDetn SensorROL_Echo1Height SensorROL_Echo2Dist;

SIG_GROUP_ 521 SensorFIL_0 1 : SensorFIL_BlindDist SensorFIL_SignalWayId SensorFIL_Echo1Dist SensorFIL_Echo1NumDetn SensorFIL_Echo1Height SensorFIL_Echo2Dist;

SIG_GROUP_ 553 SensorRIL_0 1 : SensorRIL_BlindDist SensorRIL_SignalWayId SensorRIL_Echo1Dist SensorRIL_Echo1NumDetn SensorRIL_Echo1Height SensorRIL_Echo2Dist;

SIG_GROUP_ 525 SensorFIR_0 1 : SensorFIR_BlindDist SensorFIR_SignalWayId SensorFIR_Echo1Dist SensorFIR_Echo1NumDetn SensorFIR_Echo1Height SensorFIR_Echo2Dist;

SIG_GROUP_ 557 SensorRIR_0 1 : SensorRIR_BlindDist SensorRIR_SignalWayId SensorRIR_Echo1Dist SensorRIR_Echo1NumDetn SensorRIR_Echo1Height SensorRIR_Echo2Dist;

SIG_GROUP_ 529 SensorFOR_0 1 : SensorFOR_BlindDist SensorFOR_SignalWayId SensorFOR_Echo1Dist SensorFOR_Echo1NumDetn SensorFOR_Echo1Height SensorFOR_Echo2Dist;

SIG_GROUP_ 561 SensorROR_0 1 : SensorROR_BlindDist SensorROR_SignalWayId SensorROR_Echo1Dist SensorROR_Echo1NumDetn SensorROR_Echo1Height SensorROR_Echo2Dist;
